VERSION "created by canmatrix"

NS_ :

BS_:

BU_: IPD

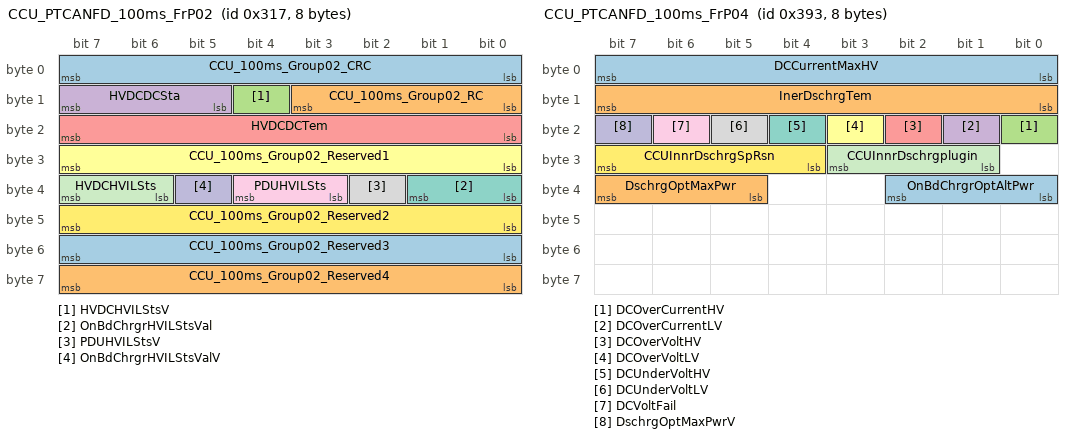
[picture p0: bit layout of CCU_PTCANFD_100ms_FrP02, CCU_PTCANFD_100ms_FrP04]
BO_ 791 CCU_PTCANFD_100ms_FrP02: 8 Vector__XXX
 SG_ CCU_100ms_Group02_CRC : 7|8@0+ (1,0) [0|255] "null" IPD
 SG_ CCU_100ms_Group02_RC : 11|4@0+ (1,0) [0|15] "null" IPD
 SG_ HVDCHVILStsV : 12|1@0+ (1,0) [0|1] "null" IPD
 SG_ HVDCDCSta : 15|3@0+ (1,0) [0|7] "null" IPD
 SG_ HVDCDCTem : 23|8@0+ (1,-40) [-40|215] "" IPD
 SG_ CCU_100ms_Group02_Reserved1 : 31|8@0+ (1,0) [0|255] "null" IPD
 SG_ OnBdChrgrHVILStsVal : 33|2@0+ (1,0) [0|3] "null" IPD
 SG_ PDUHVILStsV : 34|1@0+ (1,0) [0|1] "null" IPD
 SG_ PDUHVILSts : 36|2@0+ (1,0) [0|3] "null" IPD
 SG_ OnBdChrgrHVILStsValV : 37|1@0+ (1,0) [0|1] "null" IPD
 SG_ HVDCHVILSts : 39|2@0+ (1,0) [0|3] "null" IPD
 SG_ CCU_100ms_Group02_Reserved2 : 47|8@0+ (1,0) [0|255] "null" IPD
 SG_ CCU_100ms_Group02_Reserved3 : 55|8@0+ (1,0) [0|255] "null" IPD
 SG_ CCU_100ms_Group02_Reserved4 : 63|8@0+ (1,0) [0|255] "null" IPD

BO_ 915 CCU_PTCANFD_100ms_FrP04: 8 Vector__XXX
 SG_ DCCurrentMaxHV : 7|8@0+ (0.25,0) [0.00|63.75] "A" Vector__XXX
 SG_ InerDschrgTem : 15|8@0+ (1,-40) [-40|215] "DegC" Vector__XXX
 SG_ DCOverCurrentHV : 16|1@0+ (1,0) [0|1] "null" Vector__XXX
 SG_ DCOverCurrentLV : 17|1@0+ (1,0) [0|1] "null" Vector__XXX
 SG_ DCOverVoltHV : 18|1@0+ (1,0) [0|1] "null" Vector__XXX
 SG_ DCOverVoltLV : 19|1@0+ (1,0) [0|1] "null" Vector__XXX
 SG_ DCUnderVoltHV : 20|1@0+ (1,0) [0|1] "null" Vector__XXX
 SG_ DCUnderVoltLV : 21|1@0+ (1,0) [0|1] "null" Vector__XXX
 SG_ DCVoltFail : 22|1@0+ (1,0) [0|1] "null" Vector__XXX
 SG_ DschrgOptMaxPwrV : 23|1@0+ (1,0) [0|1] "null" Vector__XXX
 SG_ CCUInnrDschrgplugin : 27|3@0+ (1,0) [0|7] "null" Vector__XXX
 SG_ CCUInnrDschrgSpRsn : 31|4@0+ (1,0) [0|15] "null" Vector__XXX
 SG_ OnBdChrgrOptAltPwr : 34|3@0+ (0.1,0) [0|0.7] "null" IPD
 SG_ DschrgOptMaxPwr : 39|3@0+ (0.1,0) [0|0.7] "null" IPD

BO_ 992 CCU_PTCANFD_100ms_FrP07: 24 Vector__XXX
 SG_ CCU_100ms_Group07_CRC : 7|8@0+ (1,0) [0|255] "null" IPD
 SG_ CCU_100ms_Group07_RC : 11|4@0+ (1,0) [0|15] "null" IPD
 SG_ CCUOnbdChrgrPlugOnV : 12|1@0+ (1,0) [0|1] "null" IPD
 SG_ CCU_100ms_Group07_Reserved1 : 15|3@0+ (1,0) [0|7] "null" IPD
 SG_ OnBdChrgrCtrlPilotPWMSts : 18|3@0+ (1,0) [0|7] "null" IPD
 SG_ OnBdChrgrWkup : 19|1@0+ (1,0) [0|1] "null" IPD
 SG_ OnBdChrgrSts : 23|4@0+ (1,0) [0|15] "null" IPD
 SG_ OnbdChrgrAltrCrntInptHVCrntLmt : 31|8@0+ (0.5,0) [0|127.5] "A" IPD
 SG_ CCU_100ms_Group07_Reserved3 : 32|1@0+ (1,0) [0|1] "null" IPD
 SG_ OnbdChrgrOtptCrntV : 33|1@0+ (1,0) [0|1] "null" IPD
 SG_ OnbdChrgrOpngMd : 36|3@0+ (1,0) [0|7] "null" IPD
 SG_ CCU_100ms_Group07_Reserved2 : 39|3@0+ (1,0) [0|7] "null" IPD
 SG_ OnBdChrgrAltrCrntInptCrnt : 47|8@0+ (0.2,0) [0|51] "A" IPD
 SG_ OnBdChrgrAltrCrntInptVol : 55|8@0+ (2,0) [0|510] "V" IPD
 SG_ OnbdChrgrOtptCrntVal : 63|12@0+ (0.1,-204.8) [-204.8|204.7] "null" IPD
 SG_ CCU_100ms_Group07_Reserved4 : 66|3@0+ (1,0) [0|7] "null" IPD
 SG_ OnBdChrgrOtptVolV : 67|1@0+ (1,0) [0|1] "null" IPD
 SG_ OnbdChrgrOtptVolVal : 79|16@0+ (0.02,0) [0.00|1310.70] "null" IPD
 SG_ OnBdChrgrL1AltrCrntInptCrnt : 95|8@0+ (0.2,0) [0|51] "A" IPD
 SG_ OnBdChrgrL1AltrCrntInptVol : 103|8@0+ (2,0) [0|510] "V" IPD
 SG_ OnBdChrgrL2AltrCrntInptCrnt : 111|8@0+ (0.2,0) [0|51] "A" IPD
 SG_ OnBdChrgrL2AltrCrntInptVol : 119|8@0+ (2,0) [0|510] "V" IPD
 SG_ OnBdChrgrL3AltrCrntInptCrnt : 127|8@0+ (0.2,0) [0|51] "A" IPD
 SG_ OnBdChrgrL3AltrCrntInptVol : 135|8@0+ (2,0) [0|510] "V" IPD
 SG_ CCUActiveWkup : 136|1@0+ (1,0) [0|1] "null" IPD
 SG_ CCUOnbdChrgrMaxChrgPwr : 143|7@0+ (0.1,0) [0|12.7] "KW" IPD
 SG_ CCU_100ms_Group07_Reserved5 : 147|4@0+ (1,0) [0|15] "null" IPD
 SG_ CCUOnbdChrgrPlugOn : 151|4@0+ (1,0) [0|15] "null" IPD
 SG_ CCU_100ms_Group07_Reserved6 : 155|4@0+ (1,0) [0|15] "null" IPD
 SG_ CCUOnbdChrgrSpRsn : 159|4@0+ (1,0) [0|15] "null" IPD
 SG_ CCU_100ms_Group07_Reserved7 : 167|8@0+ (1,0) [0|255] "null" IPD
 SG_ CCU_100ms_Group07_Reserved9 : 169|2@0+ (1,0) [0|3] "null" IPD
 SG_ OnBdChrgrLastWkup : 170|1@0+ (1,0) [0|1] "null" IPD
 SG_ CCU_100ms_Group07_Reserved8 : 175|5@0+ (1,0) [0|31] "null" IPD
 SG_ CCU_100ms_Group07_Reserved10 : 176|1@0+ (1,0) [0|1] "null" IPD
 SG_ OnBdChrgrCtrlPilotPWMDuty : 183|7@0+ (1,0) [0|127] "null" IPD
 SG_ CCU_100ms_Group07_Reserved11 : 191|8@0+ (1,0) [0|255] "null" IPD

BO_ 966 CCU_PTCANFD_100ms_FrP11: 16 Vector__XXX
 SG_ CCU_100ms_Group11_CRC : 7|8@0+ (1,0) [0|255] "null" IPD
 SG_ CCU_100ms_Group11_RC : 11|4@0+ (1,0) [0|15] "null" IPD
 SG_ CCU_100ms_Group11_Reserved1 : 13|2@0+ (1,0) [0|3] "null" IPD
 SG_ AirCtrlrHVILClsd : 15|2@0+ (1,0) [0|3] "null" IPD
 SG_ CCU_100ms_Group11_Reserved2 : 23|8@0+ (1,0) [0|255] "null" IPD
 SG_ CCUClntFlowReq : 31|8@0+ (0.1,0) [0|25.5] "null" IPD
 SG_ CCU_100ms_Group11_Reserved3 : 39|8@0+ (1,0) [0|255] "null" IPD
 SG_ HVDCDCClntPumpPWMReq : 47|8@0+ (0.4,0) [0|102] "%" IPD
 SG_ AirCtrlrHVILClsdV : 48|1@0+ (1,0) [0|1] "null" IPD
 SG_ ESSPTCHVILSts : 50|2@0+ (1,0) [0|3] "null" IPD
 SG_ CCUOnbdChrgrSktEleccLckEnable : 52|2@0+ (1,0) [0|3] "null" IPD
 SG_ CCU_100ms_Group11_Reserved4 : 55|3@0+ (1,0) [0|7] "null" IPD
 SG_ CCU_100ms_Group11_Reserved6 : 57|2@0+ (1,0) [0|3] "null" IPD
 SG_ HVDCDCIntnlFlr : 58|1@0+ (1,0) [0|1] "null" IPD
 SG_ HVDCDCHdwrFlr : 59|1@0+ (1,0) [0|1] "null" IPD
 SG_ ESSPTCHVILStsV : 60|1@0+ (1,0) [0|1] "null" IPD
 SG_ CCU_100ms_Group11_Reserved5 : 63|3@0+ (1,0) [0|7] "null" IPD
 SG_ CCU_100ms_Group11_Reserved7 : 71|8@0+ (1,0) [0|255] "null" IPD
 SG_ CCU_100ms_Group11_Reserved8 : 79|8@0+ (1,0) [0|255] "null" IPD
 SG_ CCU_100ms_Group11_Reserved9 : 87|8@0+ (1,0) [0|255] "null" IPD
 SG_ CCU_100ms_Group11_Reserved10 : 95|8@0+ (1,0) [0|255] "null" IPD
 SG_ CCU_100ms_Group11_Reserved11 : 103|8@0+ (1,0) [0|255] "null" IPD
 SG_ CCU_100ms_Group11_Reserved12 : 111|8@0+ (1,0) [0|255] "null" IPD
 SG_ CCU_100ms_Group11_Reserved13 : 119|8@0+ (1,0) [0|255] "null" IPD
 SG_ CCU_100ms_Group11_Reserved14 : 127|8@0+ (1,0) [0|255] "null" IPD

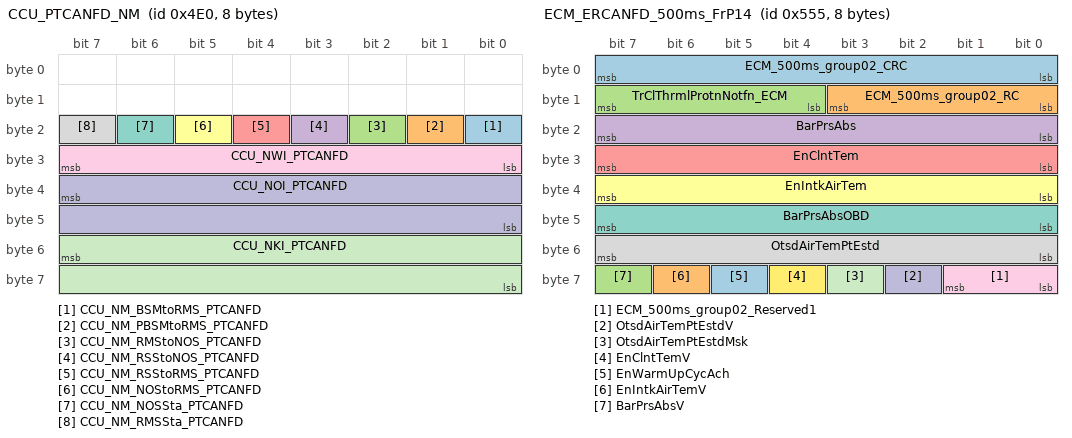
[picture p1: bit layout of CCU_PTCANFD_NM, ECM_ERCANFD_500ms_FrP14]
BO_ 1248 CCU_PTCANFD_NM: 8 Vector__XXX
 SG_ CCU_NM_BSMtoRMS_PTCANFD : 16|1@0+ (1,0) [0|1] "null" Vector__XXX
 SG_ CCU_NM_PBSMtoRMS_PTCANFD : 17|1@0+ (1,0) [0|1] "null" Vector__XXX
 SG_ CCU_NM_RMStoNOS_PTCANFD : 18|1@0+ (1,0) [0|1] "null" Vector__XXX
 SG_ CCU_NM_RSStoNOS_PTCANFD : 19|1@0+ (1,0) [0|1] "null" Vector__XXX
 SG_ CCU_NM_RSStoRMS_PTCANFD : 20|1@0+ (1,0) [0|1] "null" Vector__XXX
 SG_ CCU_NM_NOStoRMS_PTCANFD : 21|1@0+ (1,0) [0|1] "null" Vector__XXX
 SG_ CCU_NM_NOSSta_PTCANFD : 22|1@0+ (1,0) [0|1] "null" Vector__XXX
 SG_ CCU_NM_RMSSta_PTCANFD : 23|1@0+ (1,0) [0|1] "null" Vector__XXX
 SG_ CCU_NWI_PTCANFD : 31|8@0+ (1,0) [0|255] "null" Vector__XXX
 SG_ CCU_NOI_PTCANFD : 39|16@0+ (1,0) [0|65535] "null" Vector__XXX
 SG_ CCU_NKI_PTCANFD : 55|16@0+ (1,0) [0|65535] "null" Vector__XXX

BO_ 132 ECM_ERCANFD_10ms_FrP00: 8 Vector__XXX
 SG_ ECM_010ms_Group00_CRC : 7|8@0+ (1,0) [0|255] "null" IPD
 SG_ ECM_010ms_Group00_RC : 11|4@0+ (1,0) [0|15] "null" IPD
 SG_ EnActuStdyStaToqV : 12|1@0+ (1,0) [0|1] "null" IPD
 SG_ EnRunA : 13|1@0+ (1,0) [0|1] "null" IPD
 SG_ EnSpdSts : 15|2@0+ (1,0) [0|3] "null" IPD
 SG_ EnSpd : 23|16@0+ (0.25,0) [0.00|16383.75] "rpm" IPD
 SG_ ClOpenReqA : 32|1@0+ (1,0) [0|1] "null" IPD
 SG_ EnCtrlrRunCrkTrmlSts : 33|1@0+ (1,0) [0|1] "null" IPD
 SG_ IntlckRelayAuth : 34|1@0+ (1,0) [0|1] "null" IPD
 SG_ RVSPtCrkAbotd : 35|1@0+ (1,0) [0|1] "null" IPD
 SG_ RVSPtRunAbotd : 36|1@0+ (1,0) [0|1] "null" IPD
 SG_ EnTestMdEnbReq : 37|1@0+ (1,0) [0|1] "null" IPD
 SG_ ECM_010ms_Group00_Reserved39 : 39|2@0+ (1,0) [0|3] "null" IPD
 SG_ EnActuStdyStaToq : 47|12@0+ (0.5,-848) [-848|1199.5] "null" IPD
 SG_ EnSpReqToTr : 48|1@0+ (1,0) [0|1] "null" IPD
 SG_ EnCCMd : 51|3@0+ (1,0) [0|7] "null" IPD
 SG_ ECM_010ms_Group00_Reserved63 : 63|8@0+ (1,0) [0|255] "null" IPD

BO_ 1365 ECM_ERCANFD_500ms_FrP14: 8 Vector__XXX
 SG_ ECM_500ms_group02_CRC : 7|8@0+ (1,0) [0|255] "null" IPD
 SG_ ECM_500ms_group02_RC : 11|4@0+ (1,0) [0|15] "null" IPD
 SG_ TrClThrmlProtnNotfn_ECM : 15|4@0+ (1,0) [0|15] "null" IPD
 SG_ BarPrsAbs : 23|8@0+ (0.5,0) [0|127.5] "null" IPD
 SG_ EnClntTem : 31|8@0+ (1,-40) [-40|215] "" IPD
 SG_ EnIntkAirTem : 39|8@0+ (1,-40) [-40|215] "null" IPD
 SG_ BarPrsAbsOBD : 47|8@0+ (1,0) [0|255] "null" IPD
 SG_ OtsdAirTemPtEstd : 55|8@0+ (0.5,-40) [-40|87.5] "null" IPD
 SG_ ECM_500ms_group02_Reserved1 : 57|2@0+ (1,0) [0|3] "null" IPD
 SG_ OtsdAirTemPtEstdV : 58|1@0+ (1,0) [0|1] "null" IPD
 SG_ OtsdAirTemPtEstdMsk : 59|1@0+ (1,0) [0|1] "null" IPD
 SG_ EnClntTemV : 60|1@0+ (1,0) [0|1] "null" IPD
 SG_ EnWarmUpCycAch : 61|1@0+ (1,0) [0|1] "null" IPD
 SG_ EnIntkAirTemV : 62|1@0+ (1,0) [0|1] "null" IPD
 SG_ BarPrsAbsV : 63|1@0+ (1,0) [0|1] "null" IPD

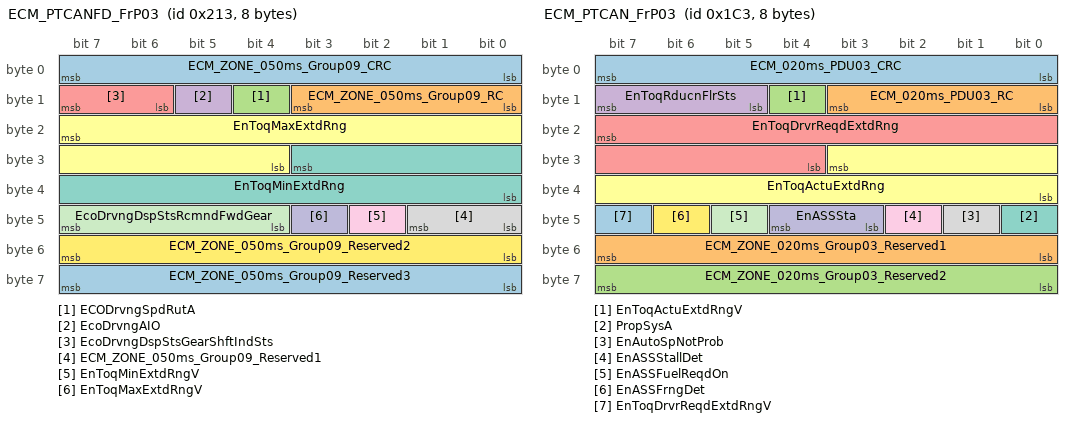
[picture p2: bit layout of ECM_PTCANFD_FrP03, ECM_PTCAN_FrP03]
BO_ 531 ECM_PTCANFD_FrP03: 8 Vector__XXX
 SG_ ECM_ZONE_050ms_Group09_CRC : 7|8@0+ (1,0) [0|255] "null" IPD
 SG_ ECM_ZONE_050ms_Group09_RC : 11|4@0+ (1,0) [0|15] "null" IPD
 SG_ ECODrvngSpdRutA : 12|1@0+ (1,0) [0|1] "null" IPD
 SG_ EcoDrvngAIO : 13|1@0+ (1,0) [0|1] "null" IPD
 SG_ EcoDrvngDspStsGearShftIndSts : 15|2@0+ (1,0) [0|3] "null" IPD
 SG_ EnToqMaxExtdRng : 23|12@0+ (0.5,-848) [-848|1199.5] "Nm" IPD
 SG_ EnToqMinExtdRng : 27|12@0+ (0.5,-848) [-848|1199.5] "Nm" IPD
 SG_ ECM_ZONE_050ms_Group09_Reserved1 : 41|2@0+ (1,0) [0|3] "null" IPD
 SG_ EnToqMinExtdRngV : 42|1@0+ (1,0) [0|1] "null" IPD
 SG_ EnToqMaxExtdRngV : 43|1@0+ (1,0) [0|1] "null" IPD
 SG_ EcoDrvngDspStsRcmndFwdGear : 47|4@0+ (1,0) [0|15] "null" IPD
 SG_ ECM_ZONE_050ms_Group09_Reserved2 : 55|8@0+ (1,0) [0|255] "null" IPD
 SG_ ECM_ZONE_050ms_Group09_Reserved3 : 63|8@0+ (1,0) [0|255] "null" IPD

BO_ 451 ECM_PTCAN_FrP03: 8 Vector__XXX
 SG_ ECM_020ms_PDU03_CRC : 7|8@0+ (1,0) [0|255] "null" IPD
 SG_ ECM_020ms_PDU03_RC : 11|4@0+ (1,0) [0|15] "null" IPD
 SG_ EnToqActuExtdRngV : 12|1@0+ (1,0) [0|1] "null" IPD
 SG_ EnToqRducnFlrSts : 15|3@0+ (1,0) [0|7] "null" IPD
 SG_ EnToqDrvrReqdExtdRng : 23|12@0+ (0.5,-848) [-848|1199.5] "Nm" IPD
 SG_ EnToqActuExtdRng : 27|12@0+ (0.5,-848) [-848|1199.5] "Nm" IPD
 SG_ PropSysA : 40|1@0+ (1,0) [0|1] "null" IPD
 SG_ EnAutoSpNotProb : 41|1@0+ (1,0) [0|1] "null" IPD
 SG_ EnASSStallDet : 42|1@0+ (1,0) [0|1] "null" IPD
 SG_ EnASSSta : 44|2@0+ (1,0) [0|3] "null" IPD
 SG_ EnASSFuelReqdOn : 45|1@0+ (1,0) [0|1] "null" IPD
 SG_ EnASSFrngDet : 46|1@0+ (1,0) [0|1] "null" IPD
 SG_ EnToqDrvrReqdExtdRngV : 47|1@0+ (1,0) [0|1] "null" IPD
 SG_ ECM_ZONE_020ms_Group03_Reserved1 : 55|8@0+ (1,0) [0|255] "null" IPD
 SG_ ECM_ZONE_020ms_Group03_Reserved2 : 63|8@0+ (1,0) [0|255] "null" IPD

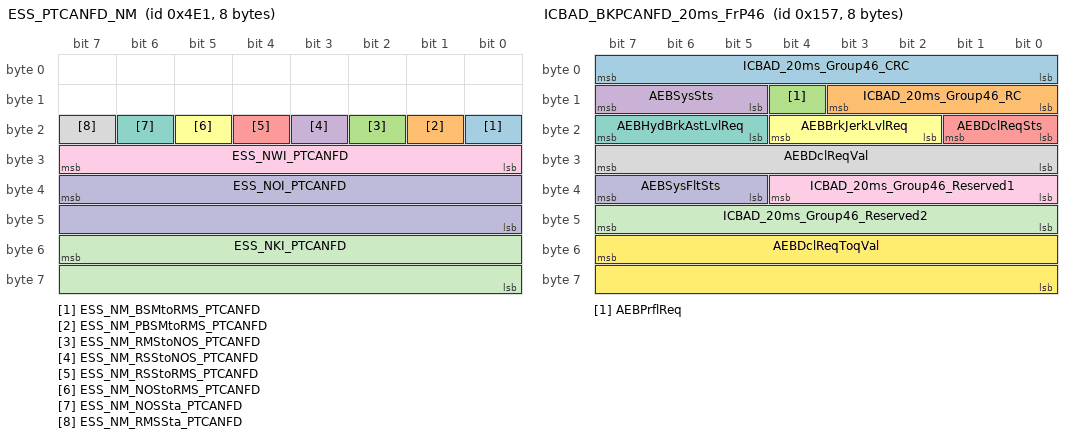
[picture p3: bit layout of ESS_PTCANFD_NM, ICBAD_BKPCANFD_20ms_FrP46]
BO_ 1249 ESS_PTCANFD_NM: 8 Vector__XXX
 SG_ ESS_NM_BSMtoRMS_PTCANFD : 16|1@0+ (1,0) [0|1] "null" Vector__XXX
 SG_ ESS_NM_PBSMtoRMS_PTCANFD : 17|1@0+ (1,0) [0|1] "null" Vector__XXX
 SG_ ESS_NM_RMStoNOS_PTCANFD : 18|1@0+ (1,0) [0|1] "null" Vector__XXX
 SG_ ESS_NM_RSStoNOS_PTCANFD : 19|1@0+ (1,0) [0|1] "null" Vector__XXX
 SG_ ESS_NM_RSStoRMS_PTCANFD : 20|1@0+ (1,0) [0|1] "null" Vector__XXX
 SG_ ESS_NM_NOStoRMS_PTCANFD : 21|1@0+ (1,0) [0|1] "null" Vector__XXX
 SG_ ESS_NM_NOSSta_PTCANFD : 22|1@0+ (1,0) [0|1] "null" Vector__XXX
 SG_ ESS_NM_RMSSta_PTCANFD : 23|1@0+ (1,0) [0|1] "null" Vector__XXX
 SG_ ESS_NWI_PTCANFD : 31|8@0+ (1,0) [0|255] "null" Vector__XXX
 SG_ ESS_NOI_PTCANFD : 39|16@0+ (1,0) [0|65535] "null" Vector__XXX
 SG_ ESS_NKI_PTCANFD : 55|16@0+ (1,0) [0|65535] "null" Vector__XXX

BO_ 307 FVCM_BKPCANFD_20ms_FrP02: 16 IPD
 SG_ FVCM_20ms_Group02_CRC : 7|8@0+ (1,0) [0|255] "null" Vector__XXX
 SG_ FVCM_20ms_Group02_RC : 11|4@0+ (1,0) [0|15] "null" Vector__XXX
 SG_ FVCM_20ms_Group02_Reserved1 : 15|4@0+ (1,0) [0|15] "null" Vector__XXX
 SG_ ACCTotWhlToqReqVal : 23|16@0+ (1,-30000) [-30000|35535] "null" Vector__XXX
 SG_ ACCDrvrSelTrgtSpd : 39|15@0+ (0.015625,0) [0.000000|511.984375] "ms" Vector__XXX
 SG_ ACCGoNotfr : 40|1@0+ (1,0) [0|1] "null" Vector__XXX
 SG_ FVCM_20ms_Group02_Reserved2 : 48|1@0+ (1,0) [0|1] "null" Vector__XXX
 SG_ ACCDetObjDistLvl : 51|3@0+ (1,0) [0|7] "null" Vector__XXX
 SG_ ELKSysSts_IPD : 55|4@0+ (1,0) [0|15] "null" Vector__XXX
 SG_ ACCTotWhlToqReqSts : 57|2@0+ (1,0) [0|3] "null" Vector__XXX
 SG_ ACCTJAMdSwDspCmd : 60|3@0+ (1,0) [0|7] "null" Vector__XXX
 SG_ ACCSeldTrgtDistLvl : 63|3@0+ (1,0) [0|7] "null" Vector__XXX
 SG_ FVCM_20ms_Group02_Reserved3 : 71|8@0+ (1,0) [0|255] "null" Vector__XXX
 SG_ HandOffStrgWhlDetnSta : 73|2@0+ (1,0) [0|3] "null" Vector__XXX
 SG_ ILCActvnDircnDspCmd : 76|3@0+ (1,0) [0|7] "null" Vector__XXX
 SG_ FVCM_20ms_Group02_Reserved4 : 79|3@0+ (1,0) [0|7] "null" Vector__XXX
 SG_ ILCSwDspCmd : 81|2@0+ (1,0) [0|3] "null" Vector__XXX
 SG_ ILCSysSts : 84|3@0+ (1,0) [0|7] "null" Vector__XXX
 SG_ ILCActvnVelDspCmd : 87|3@0+ (1,0) [0|7] "null" Vector__XXX
 SG_ HandOffStrgWhlDetnStaV : 88|1@0+ (1,0) [0|1] "null" Vector__XXX
 SG_ LDWLKAAudReq : 90|2@0+ (1,0) [0|3] "null" Vector__XXX
 SG_ LDWAdoWrnngDspCmd : 92|2@0+ (1,0) [0|3] "null" Vector__XXX
 SG_ LDWLKADspCmd : 95|3@0+ (1,0) [0|7] "null" Vector__XXX
 SG_ FVCM_20ms_Group02_Reserved5 : 98|3@0+ (1,0) [0|7] "null" Vector__XXX
 SG_ LKADrvrTkovReq : 99|1@0+ (1,0) [0|1] "null" Vector__XXX
 SG_ LDWSnstvtLvl : 101|2@0+ (1,0) [0|3] "null" Vector__XXX
 SG_ LDWLKAHptWrnngDspCmd : 103|2@0+ (1,0) [0|3] "null" Vector__XXX
 SG_ EyeOffRoadDetnSta : 105|2@0+ (1,0) [0|3] "null" Vector__XXX
 SG_ FVCM_20ms_Group02_Reserved6 : 111|6@0+ (1,0) [0|63] "null" Vector__XXX
 SG_ FVCM_20ms_Group02_Reserved7 : 113|2@0+ (1,0) [0|3] "null" Vector__XXX
 SG_ EyeOffRoadDetnStaV : 114|1@0+ (1,0) [0|1] "null" Vector__XXX
 SG_ ACCMsgReq : 119|5@0+ (1,0) [0|31] "null" Vector__XXX
 SG_ FVCM_20ms_Group02_Reserved8 : 127|8@0+ (1,0) [0|255] "null" Vector__XXX

BO_ 382 ICBAD_BKPCANFD_20ms_FrP07: 8 IPD
 SG_ ICBAD_20ms_Group07_CRC : 7|8@0+ (1,0) [0|255] "null" Vector__XXX
 SG_ ICBAD_20ms_Group07_RC : 11|4@0+ (1,0) [0|15] "null" Vector__XXX
 SG_ ACCSdslReq : 12|1@0+ (1,0) [0|1] "null" Vector__XXX
 SG_ ACCGoReq : 13|1@0+ (1,0) [0|1] "null" Vector__XXX
 SG_ ACCAccReqSts_CH : 15|2@0+ (1,0) [0|3] "null" Vector__XXX
 SG_ ACCAccReqVal : 18|11@0+ (0.006,-10.278) [-10.278|2.004] "null" Vector__XXX
 SG_ APAEPBOPReq : 20|2@0+ (1,0) [0|3] "null" Vector__XXX
 SG_ ACCSysFltSts : 23|3@0+ (1,0) [0|7] "null" Vector__XXX
 SG_ AIPkgAPASCSAcclReqVal : 34|11@0+ (0.005,-9.22) [-9.220|1.015] "m/s^2" Vector__XXX
 SG_ ACCSysSts : 37|3@0+ (1,0) [0|7] "null" Vector__XXX
 SG_ APASCSAcclReqSts : 38|1@0+ (1,0) [0|1] "null" Vector__XXX
 SG_ APAEPBOPReqV : 39|1@0+ (1,0) [0|1] "null" Vector__XXX
 SG_ AutodDrvngSysSCSSdslReqV : 48|1@0+ (1,0) [0|1] "null" Vector__XXX
 SG_ AutodDrvngSysSCSSdslReq : 49|1@0+ (1,0) [0|1] "null" Vector__XXX
 SG_ AutodDrvngSysEmgcBrkReqV : 50|1@0+ (1,0) [0|1] "null" Vector__XXX
 SG_ AutodDrvngSysEmgcBrkReq : 51|1@0+ (1,0) [0|1] "null" Vector__XXX
 SG_ ICBAD_20ms_Group07_Reserved1 : 55|4@0+ (1,0) [0|15] "null" Vector__XXX
 SG_ AutodDrvngSysSCSDrvOffReqV : 56|1@0+ (1,0) [0|1] "null" Vector__XXX
 SG_ AutodDrvngSysSCSDrvOffReq : 57|1@0+ (1,0) [0|1] "null" Vector__XXX
 SG_ AutodDrvngSysMdReqV : 58|1@0+ (1,0) [0|1] "null" Vector__XXX
 SG_ AutodDrvngSysMdReq : 59|1@0+ (1,0) [0|1] "null" Vector__XXX
 SG_ AutodDrvngSysFlrStsV : 60|1@0+ (1,0) [0|1] "null" Vector__XXX
 SG_ AutodDrvngSysFlrSts : 63|3@0+ (1,0) [0|7] "null" Vector__XXX

BO_ 343 ICBAD_BKPCANFD_20ms_FrP46: 8 IPD
 SG_ ICBAD_20ms_Group46_CRC : 7|8@0+ (1,0) [0|255] "null" Vector__XXX
 SG_ ICBAD_20ms_Group46_RC : 11|4@0+ (1,0) [0|15] "null" Vector__XXX
 SG_ AEBPrflReq : 12|1@0+ (1,0) [0|1] "null" Vector__XXX
 SG_ AEBSysSts : 15|3@0+ (1,0) [0|7] "null" Vector__XXX
 SG_ AEBDclReqSts : 17|2@0+ (1,0) [0|3] "null" Vector__XXX
 SG_ AEBBrkJerkLvlReq : 20|3@0+ (1,0) [0|7] "null" Vector__XXX
 SG_ AEBHydBrkAstLvlReq : 23|3@0+ (1,0) [0|7] "null" Vector__XXX
 SG_ AEBDclReqVal : 31|8@0+ (0.1,-12.7) [-12.7|12.8] "m/s2" Vector__XXX
 SG_ ICBAD_20ms_Group46_Reserved1 : 36|5@0+ (1,0) [0|31] "null" Vector__XXX
 SG_ AEBSysFltSts : 39|3@0+ (1,0) [0|7] "null" Vector__XXX
 SG_ ICBAD_20ms_Group46_Reserved2 : 47|8@0+ (1,0) [0|255] "null" Vector__XXX
 SG_ AEBDclReqToqVal : 55|16@0+ (1,0) [0|65535] "Nm" Vector__XXX

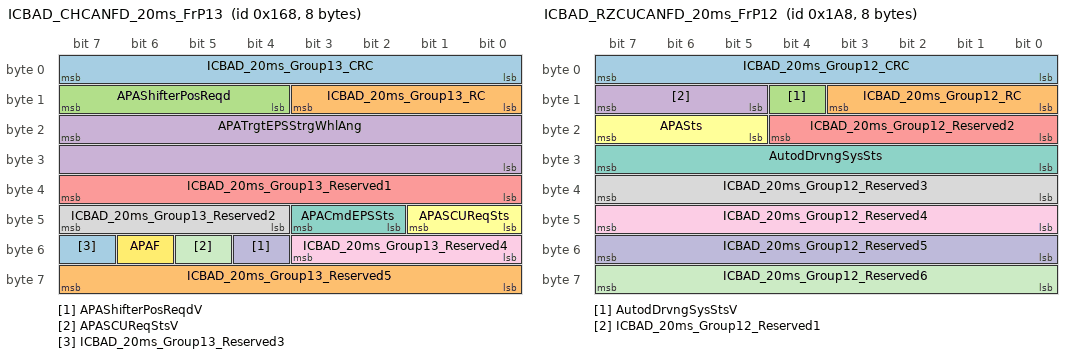
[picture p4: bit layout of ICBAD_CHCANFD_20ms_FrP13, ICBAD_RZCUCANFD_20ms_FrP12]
BO_ 360 ICBAD_CHCANFD_20ms_FrP13: 8 IPD
 SG_ ICBAD_20ms_Group13_CRC : 7|8@0+ (1,0) [0|255] "null" Vector__XXX
 SG_ ICBAD_20ms_Group13_RC : 11|4@0+ (1,0) [0|15] "null" Vector__XXX
 SG_ APAShifterPosReqd : 15|4@0+ (1,0) [0|15] "null" Vector__XXX
 SG_ APATrgtEPSStrgWhlAng : 23|16@0+ (0.0625,-2048) [-2048.0000|2047.9375] "percent" Vector__XXX
 SG_ ICBAD_20ms_Group13_Reserved1 : 39|8@0+ (1,0) [0|255] "null" Vector__XXX
 SG_ APASCUReqSts : 41|2@0+ (1,0) [0|3] "null" Vector__XXX
 SG_ APACmdEPSSts : 43|2@0+ (1,0) [0|3] "null" Vector__XXX
 SG_ ICBAD_20ms_Group13_Reserved2 : 47|4@0+ (1,0) [0|15] "null" Vector__XXX
 SG_ ICBAD_20ms_Group13_Reserved4 : 51|4@0+ (1,0) [0|15] "null" Vector__XXX
 SG_ APAShifterPosReqdV : 52|1@0+ (1,0) [0|1] "null" Vector__XXX
 SG_ APASCUReqStsV : 53|1@0+ (1,0) [0|1] "null" Vector__XXX
 SG_ APAF : 54|1@0+ (1,0) [0|1] "null" Vector__XXX
 SG_ ICBAD_20ms_Group13_Reserved3 : 55|1@0+ (1,0) [0|1] "null" Vector__XXX
 SG_ ICBAD_20ms_Group13_Reserved5 : 63|8@0+ (1,0) [0|255] "null" Vector__XXX

BO_ 351 ICBAD_RZCUCANFD_20ms_FrP05: 20 IPD
 SG_ ICBAD_20ms_Group05_CRC : 7|8@0+ (1,0) [0|255] "null" Vector__XXX
 SG_ ICBAD_20ms_Group05_RC : 11|4@0+ (1,0) [0|15] "null" Vector__XXX
 SG_ ICBAD_20ms_Group05_Reserved1 : 12|1@0+ (1,0) [0|1] "null" Vector__XXX
 SG_ APAVCUReqSts : 15|3@0+ (1,0) [0|7] "null" Vector__XXX
 SG_ ICBAD_20ms_Group05_Reserved2 : 23|8@0+ (1,0) [0|255] "null" Vector__XXX
 SG_ APAToqReqVal : 31|12@0+ (0.5,-848) [-848|1199.5] "Nm" Vector__XXX
 SG_ APACrpSpdReqVal_IPD : 33|10@0+ (0.1,0) [0|102.3] "km/h" Vector__XXX
 SG_ ICBAD_20ms_Group05_Reserved3 : 34|1@0+ (1,0) [0|1] "null" Vector__XXX
 SG_ APARevrDrgReq : 35|1@0+ (1,0) [0|1] "null" Vector__XXX
 SG_ ICBAD_20ms_Group05_Reserved4 : 55|8@0+ (1,0) [0|255] "null" Vector__XXX
 SG_ ICBAD_20ms_Group05_Reserved5 : 63|8@0+ (1,0) [0|255] "null" Vector__XXX
 SG_ APATotWhlToqReqVal : 71|16@0+ (1,-30000) [-30000|35535] "Nm" Vector__XXX
 SG_ ICBAD_20ms_Group05_Reserved6 : 87|8@0+ (1,0) [0|255] "null" Vector__XXX
 SG_ ICBAD_20ms_Group05_Reserved7 : 95|8@0+ (1,0) [0|255] "null" Vector__XXX
 SG_ ICBAD_20ms_Group05_Reserved8 : 103|8@0+ (1,0) [0|255] "null" Vector__XXX
 SG_ ICBAD_20ms_Group05_Reserved9 : 111|8@0+ (1,0) [0|255] "null" Vector__XXX
 SG_ ICBAD_20ms_Group05_Reserved10 : 119|8@0+ (1,0) [0|255] "null" Vector__XXX
 SG_ ICBAD_20ms_Group05_Reserved11 : 127|8@0+ (1,0) [0|255] "null" Vector__XXX
 SG_ ICBAD_20ms_Group05_Reserved12 : 135|8@0+ (1,0) [0|255] "null" Vector__XXX
 SG_ ICBAD_20ms_Group05_Reserved13 : 143|8@0+ (1,0) [0|255] "null" Vector__XXX
 SG_ ICBAD_20ms_Group05_Reserved14 : 151|8@0+ (1,0) [0|255] "null" Vector__XXX
 SG_ ICBAD_20ms_Group05_Reserved15 : 159|8@0+ (1,0) [0|255] "null" Vector__XXX

BO_ 424 ICBAD_RZCUCANFD_20ms_FrP12: 8 IPD
 SG_ ICBAD_20ms_Group12_CRC : 7|8@0+ (1,0) [0|255] "null" Vector__XXX
 SG_ ICBAD_20ms_Group12_RC : 11|4@0+ (1,0) [0|15] "null" Vector__XXX
 SG_ AutodDrvngSysStsV : 12|1@0+ (1,0) [0|1] "null" Vector__XXX
 SG_ ICBAD_20ms_Group12_Reserved1 : 15|3@0+ (1,0) [0|7] "null" Vector__XXX
 SG_ ICBAD_20ms_Group12_Reserved2 : 20|5@0+ (1,0) [0|31] "null" Vector__XXX
 SG_ APASts : 23|3@0+ (1,0) [0|7] "null" Vector__XXX
 SG_ AutodDrvngSysSts : 31|8@0+ (1,0) [0|255] "null" Vector__XXX
 SG_ ICBAD_20ms_Group12_Reserved3 : 39|8@0+ (1,0) [0|255] "null" Vector__XXX
 SG_ ICBAD_20ms_Group12_Reserved4 : 47|8@0+ (1,0) [0|255] "null" Vector__XXX
 SG_ ICBAD_20ms_Group12_Reserved5 : 55|8@0+ (1,0) [0|255] "null" Vector__XXX
 SG_ ICBAD_20ms_Group12_Reserved6 : 63|8@0+ (1,0) [0|255] "null" Vector__XXX

BO_ 431 ICBAD_RZCUCANFD_20ms_FrP15_NoSec: 12 IPD
 SG_ ICBAD_20ms_Group15_CRC : 7|8@0+ (1,0) [0|255] "null" Vector__XXX
 SG_ ICBAD_20ms_Group15_RC : 11|4@0+ (1,0) [0|15] "null" Vector__XXX
 SG_ ACCDclReqSts : 13|2@0+ (1,0) [0|3] "null" Vector__XXX
 SG_ ICBAD_20ms_Group15_Reserved1 : 15|2@0+ (1,0) [0|3] "null" Vector__XXX
 SG_ ICBAD_20ms_Group15_Reserved2 : 23|8@0+ (1,0) [0|255] "null" Vector__XXX
 SG_ ACCOtptShaftTotToqReqVal : 31|12@0+ (2,-3392) [-3392|4798] "Nm" Vector__XXX
 SG_ ICBAD_20ms_Group15_Reserved3 : 33|2@0+ (1,0) [0|3] "null" Vector__XXX
 SG_ ACCOtptShaftTotToqReqSts : 35|2@0+ (1,0) [0|3] "null" Vector__XXX
 SG_ AutodDrvngSysStsPT : 47|8@0+ (1,0) [0|255] "null" Vector__XXX
 SG_ ICBAD_20ms_Group15_Reserved4 : 55|8@0+ (1,0) [0|255] "null" Vector__XXX
 SG_ ICBAD_20ms_Group15_Reserved5 : 63|8@0+ (1,0) [0|255] "null" Vector__XXX
 SG_ ICBAD_20ms_Group15_Reserved6 : 71|8@0+ (1,0) [0|255] "null" Vector__XXX
 SG_ ICBAD_20ms_Group15_Reserved7 : 79|8@0+ (1,0) [0|255] "null" Vector__XXX
 SG_ ICBAD_20ms_Group15_Reserved8 : 87|8@0+ (1,0) [0|255] "null" Vector__XXX
 SG_ ICBAD_20ms_Group15_Reserved9 : 95|8@0+ (1,0) [0|255] "null" Vector__XXX

BA_DEF_ BO_ "FrameTriggeringName" STRING;
BA_DEF_ BO_ "GenMsgCycleTime" INT 0 65535;
BA_DEF_ BO_ "GenMsgSendType" ENUM  "cyclicX","spontanX","cyclicIfActiveX","spontanWithDelay","cyclicAndSpontanX","cyclicAndSpontanWithDelay","spontanWithRepitition","cyclicIfActiveAndSpontanWD","cyclicIfActiveFast","cyclicWithRepeatOnDemand","none";
BA_DEF_ BO_ "GenMsgStartValue" STRING;
BA_DEF_ BO_ "PduName" STRING;
BA_DEF_ BO_ "SystemMessageLongSymbol" STRING;
BA_DEF_ BO_ "VFrameFormat" ENUM  "StandardCAN","ExtendedCAN","reserved","reserved","reserved","reserved","reserved","reserved","reserved","reserved","reserved","reserved","reserved","reserved","StandardCAN_FD","ExtendedCAN_FD";
BA_DEF_ SG_ "CompuMethodName" STRING;
BA_DEF_ SG_ "GenSigStartValue" FLOAT 0 100000000000;
BA_DEF_ SG_ "ISignalName" STRING;
BA_DEF_ SG_ "LongName" STRING;
BA_DEF_ SG_ "SysSignalName" STRING;
BA_DEF_ SG_ "SystemSignalLongSymbol" STRING;
BA_DEF_ BU_ "NWM-Knoten" ENUM  "nein","ja";
BA_DEF_ BU_ "NWM-Stationsadresse" HEX 0 63;
BA_DEF_  "BusType" STRING;
BA_ "NWM-Knoten" BU_ IPD 0;
BA_ "NWM-Stationsadresse" BU_ IPD 0;

BA_ "BusType"   "CAN FD";

BA_ "FrameTriggeringName" BO_ 791 "CCU_PTCANFD_100ms_FrP02";
BA_ "GenMsgCycleTime" BO_ 791 100;
BA_ "GenMsgSendType" BO_ 791 0;
BA_ "GenMsgStartValue" BO_ 791 "0010feff24ffffff";
BA_ "PduName" BO_ 791 "CCU_100ms_PDU02";
BA_ "VFrameFormat" BO_ 791 14;
BA_ "FrameTriggeringName" BO_ 915 "CCU_PTCANFD_100ms_FrP04";
BA_ "GenMsgCycleTime" BO_ 915 100;
BA_ "GenMsgSendType" BO_ 915 0;
BA_ "GenMsgStartValue" BO_ 915 "00fe000000000000";
BA_ "PduName" BO_ 915 "CCU_100ms_PDU04";
BA_ "VFrameFormat" BO_ 915 14;
BA_ "FrameTriggeringName" BO_ 992 "CCU_PTCANFD_100ms_FrP07";
BA_ "GenMsgCycleTime" BO_ 992 100;
BA_ "GenMsgSendType" BO_ 992 0;
BA_ "GenMsgStartValue" BO_ 992 "00e00000e30000000f0000000000000000000f0ffffb01ff";
BA_ "PduName" BO_ 992 "CCU_100ms_PDU07";
BA_ "VFrameFormat" BO_ 992 14;
BA_ "FrameTriggeringName" BO_ 966 "CCU_PTCANFD_100ms_FrP11";
BA_ "GenMsgCycleTime" BO_ 966 100;
BA_ "GenMsgSendType" BO_ 966 0;
BA_ "GenMsgStartValue" BO_ 966 "0030ff00ff00e1f3ffffffffffffffff";
BA_ "PduName" BO_ 966 "CCU_100ms_PDU11";
BA_ "VFrameFormat" BO_ 966 14;
BA_ "FrameTriggeringName" BO_ 1248 "CCU_PTCANFD_NM";
BA_ "GenMsgSendType" BO_ 1248 1;
BA_ "GenMsgStartValue" BO_ 1248 "0000000000000000";
BA_ "PduName" BO_ 1248 "NmPDU_PTCANFD_CCU";
BA_ "VFrameFormat" BO_ 1248 14;
BA_ "FrameTriggeringName" BO_ 132 "ECM_ERCANFD_10ms_FrP00";
BA_ "GenMsgCycleTime" BO_ 132 10;
BA_ "GenMsgSendType" BO_ 132 0;
BA_ "GenMsgStartValue" BO_ 132 "00000000c00000ff";
BA_ "PduName" BO_ 132 "ECM_010ms_PDU00";
BA_ "VFrameFormat" BO_ 132 14;
BA_ "FrameTriggeringName" BO_ 1365 "ECM_ERCANFD_500ms_FrP14";
BA_ "GenMsgCycleTime" BO_ 1365 500;
BA_ "GenMsgSendType" BO_ 1365 0;
BA_ "GenMsgStartValue" BO_ 1365 "0000c80000000093";
BA_ "PduName" BO_ 1365 "ECM_500ms_PDU14";
BA_ "VFrameFormat" BO_ 1365 14;
BA_ "FrameTriggeringName" BO_ 531 "ECM_PTCANFD_FrP03";
BA_ "GenMsgCycleTime" BO_ 531 50;
BA_ "GenMsgSendType" BO_ 531 0;
BA_ "GenMsgStartValue" BO_ 531 "000000000003ffff";
BA_ "PduName" BO_ 531 "ECM_ZONE_050ms_PDU09";
BA_ "VFrameFormat" BO_ 531 14;
BA_ "FrameTriggeringName" BO_ 451 "ECM_PTCAN_FrP03";
BA_ "GenMsgCycleTime" BO_ 451 20;
BA_ "GenMsgSendType" BO_ 451 0;
BA_ "GenMsgStartValue" BO_ 451 "000000000008ffff";
BA_ "PduName" BO_ 451 "ECM_ZONE_020ms_PDU03";
BA_ "VFrameFormat" BO_ 451 14;
BA_ "FrameTriggeringName" BO_ 1249 "ESS_PTCANFD_NM";
BA_ "GenMsgSendType" BO_ 1249 1;
BA_ "GenMsgStartValue" BO_ 1249 "0000000000000000";
BA_ "PduName" BO_ 1249 "NmPDU_PTCANFD_ESS";
BA_ "VFrameFormat" BO_ 1249 14;
BA_ "FrameTriggeringName" BO_ 307 "FVCM_BKPCANFD_20ms_FrP02";
BA_ "GenMsgCycleTime" BO_ 307 20;
BA_ "GenMsgSendType" BO_ 307 0;
BA_ "GenMsgStartValue" BO_ 307 "00f0753000000160ffe0000007fc03ff";
BA_ "PduName" BO_ 307 "FVCM_20ms_PDU02";
BA_ "VFrameFormat" BO_ 307 14;
BA_ "FrameTriggeringName" BO_ 382 "ICBAD_BKPCANFD_20ms_FrP07";
BA_ "GenMsgCycleTime" BO_ 382 20;
BA_ "GenMsgSendType" BO_ 382 0;
BA_ "GenMsgStartValue" BO_ 382 "000005a40000f000";
BA_ "PduName" BO_ 382 "ICBAD_20ms_PDU07";
BA_ "VFrameFormat" BO_ 382 14;
BA_ "FrameTriggeringName" BO_ 343 "ICBAD_BKPCANFD_20ms_FrP46";
BA_ "GenMsgCycleTime" BO_ 343 20;
BA_ "GenMsgSendType" BO_ 343 0;
BA_ "GenMsgStartValue" BO_ 343 "0020007f1fff0000";
BA_ "PduName" BO_ 343 "ICBAD_20ms_PDU46";
BA_ "VFrameFormat" BO_ 343 14;
BA_ "FrameTriggeringName" BO_ 360 "ICBAD_CHCANFD_20ms_FrP13";
BA_ "GenMsgCycleTime" BO_ 360 20;
BA_ "GenMsgSendType" BO_ 360 0;
BA_ "GenMsgStartValue" BO_ 360 "00008000fff08fff";
BA_ "PduName" BO_ 360 "ICBAD_20ms_PDU13";
BA_ "VFrameFormat" BO_ 360 14;
BA_ "FrameTriggeringName" BO_ 351 "ICBAD_RZCUCANFD_20ms_FrP05";
BA_ "GenMsgCycleTime" BO_ 351 20;
BA_ "GenMsgSendType" BO_ 351 0;
BA_ "GenMsgStartValue" BO_ 351 "0010ff000400ffff0000ffffffffffffffffffff";
BA_ "PduName" BO_ 351 "ICBAD_20ms_PDU05";
BA_ "VFrameFormat" BO_ 351 14;
BA_ "FrameTriggeringName" BO_ 424 "ICBAD_RZCUCANFD_20ms_FrP12";
BA_ "GenMsgCycleTime" BO_ 424 20;
BA_ "GenMsgSendType" BO_ 424 0;
BA_ "GenMsgStartValue" BO_ 424 "00e01f00ffffffff";
BA_ "PduName" BO_ 424 "ICBAD_20ms_PDU12";
BA_ "VFrameFormat" BO_ 424 14;
BA_ "FrameTriggeringName" BO_ 431 "ICBAD_RZCUCANFD_20ms_FrP15_NoSecOC";
BA_ "GenMsgCycleTime" BO_ 431 20;
BA_ "GenMsgSendType" BO_ 431 0;
BA_ "GenMsgStartValue" BO_ 431 "00c0ff6a0300ffffffffffff";
BA_ "PduName" BO_ 431 "ICBAD_20ms_PDU15";
BA_ "SystemMessageLongSymbol" BO_ 431 "ICBAD_RZCUCANFD_20ms_FrP15_NoSecOC";
BA_ "VFrameFormat" BO_ 431 14;

BA_ "CompuMethodName" SG_ 791 CCU_100ms_Group02_CRC "CCU_100ms_Group02_CRC";
BA_ "ISignalName" SG_ 791 CCU_100ms_Group02_CRC "ICCU_100ms_Group02_CRC";
BA_ "LongName" SG_ 791 CCU_100ms_Group02_CRC "CCU_100ms_Group02_CRC";
BA_ "SysSignalName" SG_ 791 CCU_100ms_Group02_CRC "CCU_100ms_Group02_CRC";
BA_ "CompuMethodName" SG_ 791 CCU_100ms_Group02_RC "CCU_100ms_Group02_RC";
BA_ "ISignalName" SG_ 791 CCU_100ms_Group02_RC "ICCU_100ms_Group02_RC";
BA_ "LongName" SG_ 791 CCU_100ms_Group02_RC "CCU_100ms_Group02_RC";
BA_ "SysSignalName" SG_ 791 CCU_100ms_Group02_RC "CCU_100ms_Group02_RC";
BA_ "CompuMethodName" SG_ 791 HVDCHVILStsV "HVDCHVILStsV";
BA_ "GenSigStartValue" SG_ 791 HVDCHVILStsV 1;
BA_ "ISignalName" SG_ 791 HVDCHVILStsV "IHVDCHVILStsV";
BA_ "LongName" SG_ 791 HVDCHVILStsV "High Voltage Direct Current High Voltage Interlock Loop Status Validity";
BA_ "SysSignalName" SG_ 791 HVDCHVILStsV "HVDCHVILStsV";
BA_ "CompuMethodName" SG_ 791 HVDCDCSta "HVDCDCSta";
BA_ "ISignalName" SG_ 791 HVDCDCSta "IHVDCDCSta";
BA_ "LongName" SG_ 791 HVDCDCSta "High_Voltage_Direct_Current_Direct_Current_State";
BA_ "SysSignalName" SG_ 791 HVDCDCSta "HVDCDCSta";
BA_ "CompuMethodName" SG_ 791 HVDCDCTem "HVDCDCTem";
BA_ "GenSigStartValue" SG_ 791 HVDCDCTem 254;
BA_ "ISignalName" SG_ 791 HVDCDCTem "IHVDCDCTem";
BA_ "LongName" SG_ 791 HVDCDCTem "High Voltage Direct Current Direct Current Temperature";
BA_ "SysSignalName" SG_ 791 HVDCDCTem "HVDCDCTem";
BA_ "CompuMethodName" SG_ 791 CCU_100ms_Group02_Reserved1 "CCU_100ms_Group02_Reserved1";
BA_ "GenSigStartValue" SG_ 791 CCU_100ms_Group02_Reserved1 255;
BA_ "ISignalName" SG_ 791 CCU_100ms_Group02_Reserved1 "ICCU_100ms_Group02_Reserved1";
BA_ "SysSignalName" SG_ 791 CCU_100ms_Group02_Reserved1 "CCU_100ms_Group02_Reserved1";
BA_ "CompuMethodName" SG_ 791 OnBdChrgrHVILStsVal "OnBdChrgrHVILStsVal";
BA_ "ISignalName" SG_ 791 OnBdChrgrHVILStsVal "IOnBdChrgrHVILStsVal";
BA_ "LongName" SG_ 791 OnBdChrgrHVILStsVal "On Board Charger High Voltage Interlock Loop Status Value";
BA_ "SysSignalName" SG_ 791 OnBdChrgrHVILStsVal "OnBdChrgrHVILStsVal";
BA_ "CompuMethodName" SG_ 791 PDUHVILStsV "PDUHVILStsV";
BA_ "GenSigStartValue" SG_ 791 PDUHVILStsV 1;
BA_ "ISignalName" SG_ 791 PDUHVILStsV "IPDUHVILStsV";
BA_ "LongName" SG_ 791 PDUHVILStsV "Power Distribution Unit High Voltage Interlock Loop Status Validity";
BA_ "SysSignalName" SG_ 791 PDUHVILStsV "PDUHVILStsV";
BA_ "CompuMethodName" SG_ 791 PDUHVILSts "PDUHVILSts";
BA_ "ISignalName" SG_ 791 PDUHVILSts "IPDUHVILSts";
BA_ "LongName" SG_ 791 PDUHVILSts "Power Distribution Unit High Voltage Interlock Loop Status";
BA_ "SysSignalName" SG_ 791 PDUHVILSts "PDUHVILSts";
BA_ "CompuMethodName" SG_ 791 OnBdChrgrHVILStsValV "OnBdChrgrHVILStsValV";
BA_ "GenSigStartValue" SG_ 791 OnBdChrgrHVILStsValV 1;
BA_ "ISignalName" SG_ 791 OnBdChrgrHVILStsValV "IOnBdChrgrHVILStsValV";
BA_ "LongName" SG_ 791 OnBdChrgrHVILStsValV "On Board Charger High Voltage Interlock Loop Status Value Validity";
BA_ "SysSignalName" SG_ 791 OnBdChrgrHVILStsValV "OnBdChrgrHVILStsValV";
BA_ "CompuMethodName" SG_ 791 HVDCHVILSts "HVDCHVILSts";
BA_ "ISignalName" SG_ 791 HVDCHVILSts "IHVDCHVILSts";
BA_ "LongName" SG_ 791 HVDCHVILSts "High Voltage Direct Current High Voltage Interlock Loop Status";
BA_ "SysSignalName" SG_ 791 HVDCHVILSts "HVDCHVILSts";
BA_ "CompuMethodName" SG_ 791 CCU_100ms_Group02_Reserved2 "CCU_100ms_Group02_Reserved2";
BA_ "GenSigStartValue" SG_ 791 CCU_100ms_Group02_Reserved2 255;
BA_ "ISignalName" SG_ 791 CCU_100ms_Group02_Reserved2 "ICCU_100ms_Group02_Reserved2";
BA_ "SysSignalName" SG_ 791 CCU_100ms_Group02_Reserved2 "CCU_100ms_Group02_Reserved2";
BA_ "CompuMethodName" SG_ 791 CCU_100ms_Group02_Reserved3 "CCU_100ms_Group02_Reserved3";
BA_ "GenSigStartValue" SG_ 791 CCU_100ms_Group02_Reserved3 255;
BA_ "ISignalName" SG_ 791 CCU_100ms_Group02_Reserved3 "ICCU_100ms_Group02_Reserved3";
BA_ "SysSignalName" SG_ 791 CCU_100ms_Group02_Reserved3 "CCU_100ms_Group02_Reserved3";
BA_ "CompuMethodName" SG_ 791 CCU_100ms_Group02_Reserved4 "CCU_100ms_Group02_Reserved4";
BA_ "GenSigStartValue" SG_ 791 CCU_100ms_Group02_Reserved4 255;
BA_ "ISignalName" SG_ 791 CCU_100ms_Group02_Reserved4 "ICCU_100ms_Group02_Reserved4";
BA_ "SysSignalName" SG_ 791 CCU_100ms_Group02_Reserved4 "CCU_100ms_Group02_Reserved4";
BA_ "CompuMethodName" SG_ 915 DCCurrentMaxHV "DCCurrentMaxHV";
BA_ "ISignalName" SG_ 915 DCCurrentMaxHV "IDCCurrentMaxHV";
BA_ "LongName" SG_ 915 DCCurrentMaxHV "Direct Current Max Current At Hv Side";
BA_ "SysSignalName" SG_ 915 DCCurrentMaxHV "DCCurrentMaxHV";
BA_ "CompuMethodName" SG_ 915 InerDschrgTem "InerDschrgTem";
BA_ "GenSigStartValue" SG_ 915 InerDschrgTem 254;
BA_ "ISignalName" SG_ 915 InerDschrgTem "IInerDschrgTem";
BA_ "LongName" SG_ 915 InerDschrgTem "Inner Discharger Socket Temperature";
BA_ "SysSignalName" SG_ 915 InerDschrgTem "InerDschrgTem";
BA_ "CompuMethodName" SG_ 915 DCOverCurrentHV "DCOverCurrentHV";
BA_ "ISignalName" SG_ 915 DCOverCurrentHV "IDCOverCurrentHV";
BA_ "LongName" SG_ 915 DCOverCurrentHV "Direct Current Over Current At Hv Side";
BA_ "SysSignalName" SG_ 915 DCOverCurrentHV "DCOverCurrentHV";
BA_ "CompuMethodName" SG_ 915 DCOverCurrentLV "DCOverCurrentLV";
BA_ "ISignalName" SG_ 915 DCOverCurrentLV "IDCOverCurrentLV";
BA_ "LongName" SG_ 915 DCOverCurrentLV "Direct Current Over Current At Lv Side";
BA_ "SysSignalName" SG_ 915 DCOverCurrentLV "DCOverCurrentLV";
BA_ "CompuMethodName" SG_ 915 DCOverVoltHV "DCOverVoltHV";
BA_ "ISignalName" SG_ 915 DCOverVoltHV "IDCOverVoltHV";
BA_ "LongName" SG_ 915 DCOverVoltHV "Direct Current Over Volt High Voltage";
BA_ "SysSignalName" SG_ 915 DCOverVoltHV "DCOverVoltHV";
BA_ "CompuMethodName" SG_ 915 DCOverVoltLV "DCOverVoltLV";
BA_ "ISignalName" SG_ 915 DCOverVoltLV "IDCOverVoltLV";
BA_ "LongName" SG_ 915 DCOverVoltLV "Direct Current Over Volt Low Voltage";
BA_ "SysSignalName" SG_ 915 DCOverVoltLV "DCOverVoltLV";
BA_ "CompuMethodName" SG_ 915 DCUnderVoltHV "DCUnderVoltHV";
BA_ "ISignalName" SG_ 915 DCUnderVoltHV "IDCUnderVoltHV";
BA_ "LongName" SG_ 915 DCUnderVoltHV "Direct Current Under Volt High Voltage";
BA_ "SysSignalName" SG_ 915 DCUnderVoltHV "DCUnderVoltHV";
BA_ "CompuMethodName" SG_ 915 DCUnderVoltLV "DCUnderVoltLV";
BA_ "ISignalName" SG_ 915 DCUnderVoltLV "IDCUnderVoltLV";
BA_ "LongName" SG_ 915 DCUnderVoltLV "Direct Current Under Volt Low Voltage";
BA_ "SysSignalName" SG_ 915 DCUnderVoltLV "DCUnderVoltLV";
BA_ "CompuMethodName" SG_ 915 DCVoltFail "DCVoltFail";
BA_ "ISignalName" SG_ 915 DCVoltFail "IDCVoltFail";
BA_ "LongName" SG_ 915 DCVoltFail "Direct Current Voltage Failure";
BA_ "SysSignalName" SG_ 915 DCVoltFail "DCVoltFail";
BA_ "CompuMethodName" SG_ 915 DschrgOptMaxPwrV "DschrgOptMaxPwrV";
BA_ "ISignalName" SG_ 915 DschrgOptMaxPwrV "IDschrgOptMaxPwrV";
BA_ "LongName" SG_ 915 DschrgOptMaxPwrV "Discharge  Output Max Power Valid";
BA_ "SysSignalName" SG_ 915 DschrgOptMaxPwrV "DschrgOptMaxPwrV";
BA_ "CompuMethodName" SG_ 915 CCUInnrDschrgplugin "CCUInnrDschrgplugin";
BA_ "ISignalName" SG_ 915 CCUInnrDschrgplugin "ICCUInnrDschrgplugin";
BA_ "LongName" SG_ 915 CCUInnrDschrgplugin "CCU inner Discharger plug in";
BA_ "SysSignalName" SG_ 915 CCUInnrDschrgplugin "CCUInnrDschrgplugin";
BA_ "CompuMethodName" SG_ 915 CCUInnrDschrgSpRsn "CCUInnrDschrgSpRsn";
BA_ "ISignalName" SG_ 915 CCUInnrDschrgSpRsn "ICCUInnrDschrgSpRsn";
BA_ "LongName" SG_ 915 CCUInnrDschrgSpRsn "CCU Inner Dischargering Stop Reason";
BA_ "SysSignalName" SG_ 915 CCUInnrDschrgSpRsn "CCUInnrDschrgSpRsn";
BA_ "CompuMethodName" SG_ 915 OnBdChrgrOptAltPwr "OnBdChrgrOptAltPwr";
BA_ "ISignalName" SG_ 915 OnBdChrgrOptAltPwr "IOnBdChrgrOptAltPwr";
BA_ "LongName" SG_ 915 OnBdChrgrOptAltPwr "On Board Charger Output Alternating Power";
BA_ "SysSignalName" SG_ 915 OnBdChrgrOptAltPwr "OnBdChrgrOptAltPwr";
BA_ "CompuMethodName" SG_ 915 DschrgOptMaxPwr "DschrgOptMaxPwr";
BA_ "ISignalName" SG_ 915 DschrgOptMaxPwr "IDschrgOptMaxPwr";
BA_ "LongName" SG_ 915 DschrgOptMaxPwr "Discharge  Output Max Power";
BA_ "SysSignalName" SG_ 915 DschrgOptMaxPwr "DschrgOptMaxPwr";
BA_ "CompuMethodName" SG_ 992 CCU_100ms_Group07_CRC "CCU_100ms_Group07_CRC";
BA_ "ISignalName" SG_ 992 CCU_100ms_Group07_CRC "ICCU_100ms_Group07_CRC";
BA_ "LongName" SG_ 992 CCU_100ms_Group07_CRC "CCU_100ms_Group07_CRC";
BA_ "SysSignalName" SG_ 992 CCU_100ms_Group07_CRC "CCU_100ms_Group07_CRC";
BA_ "CompuMethodName" SG_ 992 CCU_100ms_Group07_RC "CCU_100ms_Group07_RC";
BA_ "ISignalName" SG_ 992 CCU_100ms_Group07_RC "ICCU_100ms_Group07_RC";
BA_ "LongName" SG_ 992 CCU_100ms_Group07_RC "CCU_100ms_Group07_RC";
BA_ "SysSignalName" SG_ 992 CCU_100ms_Group07_RC "CCU_100ms_Group07_RC";
BA_ "CompuMethodName" SG_ 992 CCUOnbdChrgrPlugOnV "CCUOnbdChrgrPlugOnV";
BA_ "ISignalName" SG_ 992 CCUOnbdChrgrPlugOnV "ICCUOnbdChrgrPlugOnV";
BA_ "LongName" SG_ 992 CCUOnbdChrgrPlugOnV "Combined Charging Unit Onboard Charger Plug On Validity";
BA_ "SysSignalName" SG_ 992 CCUOnbdChrgrPlugOnV "CCUOnbdChrgrPlugOnV";
BA_ "CompuMethodName" SG_ 992 CCU_100ms_Group07_Reserved1 "CCU_100ms_Group07_Reserved1";
BA_ "GenSigStartValue" SG_ 992 CCU_100ms_Group07_Reserved1 7;
BA_ "ISignalName" SG_ 992 CCU_100ms_Group07_Reserved1 "ICCU_100ms_Group07_Reserved1";
BA_ "SysSignalName" SG_ 992 CCU_100ms_Group07_Reserved1 "CCU_100ms_Group07_Reserved1";
BA_ "CompuMethodName" SG_ 992 OnBdChrgrCtrlPilotPWMSts "OnBdChrgrCtrlPilotPWMSts";
BA_ "ISignalName" SG_ 992 OnBdChrgrCtrlPilotPWMSts "IOnBdChrgrCtrlPilotPWMSts";
BA_ "LongName" SG_ 992 OnBdChrgrCtrlPilotPWMSts "On Board Charger Control Pilot Pulse Width Modulation Status";
BA_ "SysSignalName" SG_ 992 OnBdChrgrCtrlPilotPWMSts "OnBdChrgrCtrlPilotPWMSts";
BA_ "CompuMethodName" SG_ 992 OnBdChrgrWkup "OnBdChrgrWkup";
BA_ "ISignalName" SG_ 992 OnBdChrgrWkup "IOnBdChrgrWkup";
BA_ "LongName" SG_ 992 OnBdChrgrWkup "On Board Charger Wakeup";
BA_ "SysSignalName" SG_ 992 OnBdChrgrWkup "OnBdChrgrWkup";
BA_ "CompuMethodName" SG_ 992 OnBdChrgrSts "OnBdChrgrSts";
BA_ "ISignalName" SG_ 992 OnBdChrgrSts "IOnBdChrgrSts";
BA_ "LongName" SG_ 992 OnBdChrgrSts "On Board Charger Status";
BA_ "SysSignalName" SG_ 992 OnBdChrgrSts "OnBdChrgrSts";
BA_ "CompuMethodName" SG_ 992 OnbdChrgrAltrCrntInptHVCrntLmt "OnbdChrgrAltrCrntInptHVCrntLmt";
BA_ "ISignalName" SG_ 992 OnbdChrgrAltrCrntInptHVCrntLmt "IOnbdChrgrAltrCrntInptHVCrntLmt";
BA_ "LongName" SG_ 992 OnbdChrgrAltrCrntInptHVCrntLmt "Onboard Charger Alternator Current Input High Voltage Current Limit";
BA_ "SysSignalName" SG_ 992 OnbdChrgrAltrCrntInptHVCrntLmt "OnbdChrgrAltrCrntInptHVCrntLmt";
BA_ "CompuMethodName" SG_ 992 CCU_100ms_Group07_Reserved3 "CCU_100ms_Group07_Reserved3";
BA_ "GenSigStartValue" SG_ 992 CCU_100ms_Group07_Reserved3 1;
BA_ "ISignalName" SG_ 992 CCU_100ms_Group07_Reserved3 "ICCU_100ms_Group07_Reserved3";
BA_ "SysSignalName" SG_ 992 CCU_100ms_Group07_Reserved3 "CCU_100ms_Group07_Reserved3";
BA_ "CompuMethodName" SG_ 992 OnbdChrgrOtptCrntV "OnbdChrgrOtptCrntV";
BA_ "GenSigStartValue" SG_ 992 OnbdChrgrOtptCrntV 1;
BA_ "ISignalName" SG_ 992 OnbdChrgrOtptCrntV "IOnbdChrgrOtptCrntV";
BA_ "LongName" SG_ 992 OnbdChrgrOtptCrntV "On Board Charger Output Current Validity";
BA_ "SysSignalName" SG_ 992 OnbdChrgrOtptCrntV "OnbdChrgrOtptCrntV";
BA_ "CompuMethodName" SG_ 992 OnbdChrgrOpngMd "OnbdChrgrOpngMd";
BA_ "ISignalName" SG_ 992 OnbdChrgrOpngMd "IOnbdChrgrOpngMd";
BA_ "LongName" SG_ 992 OnbdChrgrOpngMd "On Board Charger Operating Mode";
BA_ "SysSignalName" SG_ 992 OnbdChrgrOpngMd "OnbdChrgrOpngMd";
BA_ "CompuMethodName" SG_ 992 CCU_100ms_Group07_Reserved2 "CCU_100ms_Group07_Reserved2";
BA_ "GenSigStartValue" SG_ 992 CCU_100ms_Group07_Reserved2 7;
BA_ "ISignalName" SG_ 992 CCU_100ms_Group07_Reserved2 "ICCU_100ms_Group07_Reserved2";
BA_ "SysSignalName" SG_ 992 CCU_100ms_Group07_Reserved2 "CCU_100ms_Group07_Reserved2";
BA_ "CompuMethodName" SG_ 992 OnBdChrgrAltrCrntInptCrnt "OnBdChrgrAltrCrntInptCrnt";
BA_ "ISignalName" SG_ 992 OnBdChrgrAltrCrntInptCrnt "IOnBdChrgrAltrCrntInptCrnt";
BA_ "LongName" SG_ 992 OnBdChrgrAltrCrntInptCrnt "On Board Charger Alternator Current Input Current";
BA_ "SysSignalName" SG_ 992 OnBdChrgrAltrCrntInptCrnt "OnBdChrgrAltrCrntInptCrnt";
BA_ "CompuMethodName" SG_ 992 OnBdChrgrAltrCrntInptVol "OnBdChrgrAltrCrntInptVol";
BA_ "ISignalName" SG_ 992 OnBdChrgrAltrCrntInptVol "IOnBdChrgrAltrCrntInptVol";
BA_ "LongName" SG_ 992 OnBdChrgrAltrCrntInptVol "On Board Charger Alternator Current Input Voltage";
BA_ "SysSignalName" SG_ 992 OnBdChrgrAltrCrntInptVol "OnBdChrgrAltrCrntInptVol";
BA_ "CompuMethodName" SG_ 992 OnbdChrgrOtptCrntVal "OnbdChrgrOtptCrntVal";
BA_ "ISignalName" SG_ 992 OnbdChrgrOtptCrntVal "IOnbdChrgrOtptCrntVal";
BA_ "LongName" SG_ 992 OnbdChrgrOtptCrntVal "On Board Charger Output Current Value";
BA_ "SysSignalName" SG_ 992 OnbdChrgrOtptCrntVal "OnbdChrgrOtptCrntVal";
BA_ "CompuMethodName" SG_ 992 CCU_100ms_Group07_Reserved4 "CCU_100ms_Group07_Reserved4";
BA_ "GenSigStartValue" SG_ 992 CCU_100ms_Group07_Reserved4 7;
BA_ "ISignalName" SG_ 992 CCU_100ms_Group07_Reserved4 "ICCU_100ms_Group07_Reserved4";
BA_ "SysSignalName" SG_ 992 CCU_100ms_Group07_Reserved4 "CCU_100ms_Group07_Reserved4";
BA_ "CompuMethodName" SG_ 992 OnBdChrgrOtptVolV "OnBdChrgrOtptVolV";
BA_ "GenSigStartValue" SG_ 992 OnBdChrgrOtptVolV 1;
BA_ "ISignalName" SG_ 992 OnBdChrgrOtptVolV "IOnBdChrgrOtptVolV";
BA_ "LongName" SG_ 992 OnBdChrgrOtptVolV "On Board Charger Output Voltage Validity";
BA_ "SysSignalName" SG_ 992 OnBdChrgrOtptVolV "OnBdChrgrOtptVolV";
BA_ "CompuMethodName" SG_ 992 OnbdChrgrOtptVolVal "OnbdChrgrOtptVolVal";
BA_ "ISignalName" SG_ 992 OnbdChrgrOtptVolVal "IOnbdChrgrOtptVolVal";
BA_ "LongName" SG_ 992 OnbdChrgrOtptVolVal "On Board Charger Output Voltage Value";
BA_ "SysSignalName" SG_ 992 OnbdChrgrOtptVolVal "OnbdChrgrOtptVolVal";
BA_ "CompuMethodName" SG_ 992 OnBdChrgrL1AltrCrntInptCrnt "OnBdChrgrL1AltrCrntInptCrnt";
BA_ "ISignalName" SG_ 992 OnBdChrgrL1AltrCrntInptCrnt "IOnBdChrgrL1AltrCrntInptCrnt";
BA_ "LongName" SG_ 992 OnBdChrgrL1AltrCrntInptCrnt "On Board Charger Live Wire 1 Alternator Current Input Current";
BA_ "SysSignalName" SG_ 992 OnBdChrgrL1AltrCrntInptCrnt "OnBdChrgrL1AltrCrntInptCrnt";
BA_ "CompuMethodName" SG_ 992 OnBdChrgrL1AltrCrntInptVol "OnBdChrgrL1AltrCrntInptVol";
BA_ "ISignalName" SG_ 992 OnBdChrgrL1AltrCrntInptVol "IOnBdChrgrL1AltrCrntInptVol";
BA_ "LongName" SG_ 992 OnBdChrgrL1AltrCrntInptVol "On Board Charger Live Wire 1 Alternator Current Input Voltage";
BA_ "SysSignalName" SG_ 992 OnBdChrgrL1AltrCrntInptVol "OnBdChrgrL1AltrCrntInptVol";
BA_ "CompuMethodName" SG_ 992 OnBdChrgrL2AltrCrntInptCrnt "OnBdChrgrL2AltrCrntInptCrnt";
BA_ "ISignalName" SG_ 992 OnBdChrgrL2AltrCrntInptCrnt "IOnBdChrgrL2AltrCrntInptCrnt";
BA_ "LongName" SG_ 992 OnBdChrgrL2AltrCrntInptCrnt "On Board Charger Live Wire 2 Alternator Current Input Current";
BA_ "SysSignalName" SG_ 992 OnBdChrgrL2AltrCrntInptCrnt "OnBdChrgrL2AltrCrntInptCrnt";
BA_ "CompuMethodName" SG_ 992 OnBdChrgrL2AltrCrntInptVol "OnBdChrgrL2AltrCrntInptVol";
BA_ "ISignalName" SG_ 992 OnBdChrgrL2AltrCrntInptVol "IOnBdChrgrL2AltrCrntInptVol";
BA_ "LongName" SG_ 992 OnBdChrgrL2AltrCrntInptVol "On Board Charger Live Wire 2 Alternator Current Input Voltage";
BA_ "SysSignalName" SG_ 992 OnBdChrgrL2AltrCrntInptVol "OnBdChrgrL2AltrCrntInptVol";
BA_ "CompuMethodName" SG_ 992 OnBdChrgrL3AltrCrntInptCrnt "OnBdChrgrL3AltrCrntInptCrnt";
BA_ "ISignalName" SG_ 992 OnBdChrgrL3AltrCrntInptCrnt "IOnBdChrgrL3AltrCrntInptCrnt";
BA_ "LongName" SG_ 992 OnBdChrgrL3AltrCrntInptCrnt "On Board Charger Live Wire 3 Alternator Current Input Current";
BA_ "SysSignalName" SG_ 992 OnBdChrgrL3AltrCrntInptCrnt "OnBdChrgrL3AltrCrntInptCrnt";
BA_ "CompuMethodName" SG_ 992 OnBdChrgrL3AltrCrntInptVol "OnBdChrgrL3AltrCrntInptVol";
BA_ "ISignalName" SG_ 992 OnBdChrgrL3AltrCrntInptVol "IOnBdChrgrL3AltrCrntInptVol";
BA_ "LongName" SG_ 992 OnBdChrgrL3AltrCrntInptVol "On Board Charger Live Wire 3 Alternator Current Input Voltage";
BA_ "SysSignalName" SG_ 992 OnBdChrgrL3AltrCrntInptVol "OnBdChrgrL3AltrCrntInptVol";
BA_ "CompuMethodName" SG_ 992 CCUActiveWkup "CCUActiveWkup";
BA_ "ISignalName" SG_ 992 CCUActiveWkup "ICCUActiveWkup";
BA_ "LongName" SG_ 992 CCUActiveWkup "CCUActive Wakeup";
BA_ "SysSignalName" SG_ 992 CCUActiveWkup "CCUActiveWkup";
BA_ "CompuMethodName" SG_ 992 CCUOnbdChrgrMaxChrgPwr "CCUOnbdChrgrMaxChrgPwr";
BA_ "ISignalName" SG_ 992 CCUOnbdChrgrMaxChrgPwr "ICCUOnbdChrgrMaxChrgPwr";
BA_ "LongName" SG_ 992 CCUOnbdChrgrMaxChrgPwr "Combined Charging Unit Onboard Charger Maximum Charge Power";
BA_ "SysSignalName" SG_ 992 CCUOnbdChrgrMaxChrgPwr "CCUOnbdChrgrMaxChrgPwr";
BA_ "CompuMethodName" SG_ 992 CCU_100ms_Group07_Reserved5 "CCU_100ms_Group07_Reserved5";
BA_ "GenSigStartValue" SG_ 992 CCU_100ms_Group07_Reserved5 15;
BA_ "ISignalName" SG_ 992 CCU_100ms_Group07_Reserved5 "ICCU_100ms_Group07_Reserved5";
BA_ "SysSignalName" SG_ 992 CCU_100ms_Group07_Reserved5 "CCU_100ms_Group07_Reserved5";
BA_ "CompuMethodName" SG_ 992 CCUOnbdChrgrPlugOn "CCUOnbdChrgrPlugOn";
BA_ "ISignalName" SG_ 992 CCUOnbdChrgrPlugOn "ICCUOnbdChrgrPlugOn";
BA_ "LongName" SG_ 992 CCUOnbdChrgrPlugOn "Combined Charging Unit Onboard Charger Plug On";
BA_ "SysSignalName" SG_ 992 CCUOnbdChrgrPlugOn "CCUOnbdChrgrPlugOn";
BA_ "CompuMethodName" SG_ 992 CCU_100ms_Group07_Reserved6 "CCU_100ms_Group07_Reserved6";
BA_ "GenSigStartValue" SG_ 992 CCU_100ms_Group07_Reserved6 15;
BA_ "ISignalName" SG_ 992 CCU_100ms_Group07_Reserved6 "ICCU_100ms_Group07_Reserved6";
BA_ "SysSignalName" SG_ 992 CCU_100ms_Group07_Reserved6 "CCU_100ms_Group07_Reserved6";
BA_ "CompuMethodName" SG_ 992 CCUOnbdChrgrSpRsn "CCUOnbdChrgrSpRsn";
BA_ "ISignalName" SG_ 992 CCUOnbdChrgrSpRsn "ICCUOnbdChrgrSpRsn";
BA_ "LongName" SG_ 992 CCUOnbdChrgrSpRsn "Combined Charging Unit Onboard Charger Stop Reason";
BA_ "SysSignalName" SG_ 992 CCUOnbdChrgrSpRsn "CCUOnbdChrgrSpRsn";
BA_ "CompuMethodName" SG_ 992 CCU_100ms_Group07_Reserved7 "CCU_100ms_Group07_Reserved7";
BA_ "GenSigStartValue" SG_ 992 CCU_100ms_Group07_Reserved7 255;
BA_ "ISignalName" SG_ 992 CCU_100ms_Group07_Reserved7 "ICCU_100ms_Group07_Reserved7";
BA_ "SysSignalName" SG_ 992 CCU_100ms_Group07_Reserved7 "CCU_100ms_Group07_Reserved7";
BA_ "CompuMethodName" SG_ 992 CCU_100ms_Group07_Reserved9 "CCU_100ms_Group07_Reserved9";
BA_ "GenSigStartValue" SG_ 992 CCU_100ms_Group07_Reserved9 3;
BA_ "ISignalName" SG_ 992 CCU_100ms_Group07_Reserved9 "ICCU_100ms_Group07_Reserved9";
BA_ "SysSignalName" SG_ 992 CCU_100ms_Group07_Reserved9 "CCU_100ms_Group07_Reserved9";
BA_ "CompuMethodName" SG_ 992 OnBdChrgrLastWkup "OnBdChrgrLastWkup";
BA_ "ISignalName" SG_ 992 OnBdChrgrLastWkup "IOnBdChrgrLastWkup";
BA_ "LongName" SG_ 992 OnBdChrgrLastWkup "On Board Charger Last Wakeup";
BA_ "SysSignalName" SG_ 992 OnBdChrgrLastWkup "OnBdChrgrLastWkup";
BA_ "CompuMethodName" SG_ 992 CCU_100ms_Group07_Reserved8 "CCU_100ms_Group07_Reserved8";
BA_ "GenSigStartValue" SG_ 992 CCU_100ms_Group07_Reserved8 31;
BA_ "ISignalName" SG_ 992 CCU_100ms_Group07_Reserved8 "ICCU_100ms_Group07_Reserved8";
BA_ "SysSignalName" SG_ 992 CCU_100ms_Group07_Reserved8 "CCU_100ms_Group07_Reserved8";
BA_ "CompuMethodName" SG_ 992 CCU_100ms_Group07_Reserved10 "CCU_100ms_Group07_Reserved10";
BA_ "GenSigStartValue" SG_ 992 CCU_100ms_Group07_Reserved10 1;
BA_ "ISignalName" SG_ 992 CCU_100ms_Group07_Reserved10 "ICCU_100ms_Group07_Reserved10";
BA_ "SysSignalName" SG_ 992 CCU_100ms_Group07_Reserved10 "CCU_100ms_Group07_Reserved10";
BA_ "CompuMethodName" SG_ 992 OnBdChrgrCtrlPilotPWMDuty "OnBdChrgrCtrlPilotPWMDuty";
BA_ "ISignalName" SG_ 992 OnBdChrgrCtrlPilotPWMDuty "IOnBdChrgrCtrlPilotPWMDuty";
BA_ "LongName" SG_ 992 OnBdChrgrCtrlPilotPWMDuty "On Board Charger Control Pilot Pulse Width Modulation Duty";
BA_ "SysSignalName" SG_ 992 OnBdChrgrCtrlPilotPWMDuty "OnBdChrgrCtrlPilotPWMDuty";
BA_ "CompuMethodName" SG_ 992 CCU_100ms_Group07_Reserved11 "CCU_100ms_Group07_Reserved11";
BA_ "GenSigStartValue" SG_ 992 CCU_100ms_Group07_Reserved11 255;
BA_ "ISignalName" SG_ 992 CCU_100ms_Group07_Reserved11 "ICCU_100ms_Group07_Reserved11";
BA_ "SysSignalName" SG_ 992 CCU_100ms_Group07_Reserved11 "CCU_100ms_Group07_Reserved11";
BA_ "CompuMethodName" SG_ 966 CCU_100ms_Group11_CRC "CCU_100ms_Group11_CRC";
BA_ "ISignalName" SG_ 966 CCU_100ms_Group11_CRC "ICCU_100ms_Group11_CRC";
BA_ "LongName" SG_ 966 CCU_100ms_Group11_CRC "CCU_100ms_Group11_CRC";
BA_ "SysSignalName" SG_ 966 CCU_100ms_Group11_CRC "CCU_100ms_Group11_CRC";
BA_ "CompuMethodName" SG_ 966 CCU_100ms_Group11_RC "CCU_100ms_Group11_RC";
BA_ "ISignalName" SG_ 966 CCU_100ms_Group11_RC "ICCU_100ms_Group11_RC";
BA_ "LongName" SG_ 966 CCU_100ms_Group11_RC "CCU_100ms_Group11_RC";
BA_ "SysSignalName" SG_ 966 CCU_100ms_Group11_RC "CCU_100ms_Group11_RC";
BA_ "CompuMethodName" SG_ 966 CCU_100ms_Group11_Reserved1 "CCU_100ms_Group11_Reserved1";
BA_ "GenSigStartValue" SG_ 966 CCU_100ms_Group11_Reserved1 3;
BA_ "ISignalName" SG_ 966 CCU_100ms_Group11_Reserved1 "ICCU_100ms_Group11_Reserved1";
BA_ "SysSignalName" SG_ 966 CCU_100ms_Group11_Reserved1 "CCU_100ms_Group11_Reserved1";
BA_ "CompuMethodName" SG_ 966 AirCtrlrHVILClsd "AirCtrlrHVILClsd";
BA_ "ISignalName" SG_ 966 AirCtrlrHVILClsd "IAirCtrlrHVILClsd";
BA_ "LongName" SG_ 966 AirCtrlrHVILClsd "Air Controller High Voltage Interlock Loop Closed";
BA_ "SysSignalName" SG_ 966 AirCtrlrHVILClsd "AirCtrlrHVILClsd";
BA_ "CompuMethodName" SG_ 966 CCU_100ms_Group11_Reserved2 "CCU_100ms_Group11_Reserved2";
BA_ "GenSigStartValue" SG_ 966 CCU_100ms_Group11_Reserved2 255;
BA_ "ISignalName" SG_ 966 CCU_100ms_Group11_Reserved2 "ICCU_100ms_Group11_Reserved2";
BA_ "SysSignalName" SG_ 966 CCU_100ms_Group11_Reserved2 "CCU_100ms_Group11_Reserved2";
BA_ "CompuMethodName" SG_ 966 CCUClntFlowReq "CCUClntFlowReq";
BA_ "ISignalName" SG_ 966 CCUClntFlowReq "ICCUClntFlowReq";
BA_ "LongName" SG_ 966 CCUClntFlowReq "Combined Charging Unit Coolant Flow Request";
BA_ "SysSignalName" SG_ 966 CCUClntFlowReq "CCUClntFlowReq";
BA_ "CompuMethodName" SG_ 966 CCU_100ms_Group11_Reserved3 "CCU_100ms_Group11_Reserved3";
BA_ "GenSigStartValue" SG_ 966 CCU_100ms_Group11_Reserved3 255;
BA_ "ISignalName" SG_ 966 CCU_100ms_Group11_Reserved3 "ICCU_100ms_Group11_Reserved3";
BA_ "SysSignalName" SG_ 966 CCU_100ms_Group11_Reserved3 "CCU_100ms_Group11_Reserved3";
BA_ "CompuMethodName" SG_ 966 HVDCDCClntPumpPWMReq "HVDCDCClntPumpPWMReq";
BA_ "ISignalName" SG_ 966 HVDCDCClntPumpPWMReq "IHVDCDCClntPumpPWMReq";
BA_ "LongName" SG_ 966 HVDCDCClntPumpPWMReq "High Voltage Direct Current Direct Current Coolant Pump Pulse Width Modulation Request";
BA_ "SysSignalName" SG_ 966 HVDCDCClntPumpPWMReq "HVDCDCClntPumpPWMReq";
BA_ "CompuMethodName" SG_ 966 AirCtrlrHVILClsdV "AirCtrlrHVILClsdV";
BA_ "GenSigStartValue" SG_ 966 AirCtrlrHVILClsdV 1;
BA_ "ISignalName" SG_ 966 AirCtrlrHVILClsdV "IAirCtrlrHVILClsdV";
BA_ "LongName" SG_ 966 AirCtrlrHVILClsdV "Air Controller High Voltage Interlock Loop Closed Validity";
BA_ "SysSignalName" SG_ 966 AirCtrlrHVILClsdV "AirCtrlrHVILClsdV";
BA_ "CompuMethodName" SG_ 966 ESSPTCHVILSts "ESSPTCHVILSts";
BA_ "ISignalName" SG_ 966 ESSPTCHVILSts "IESSPTCHVILSts";
BA_ "LongName" SG_ 966 ESSPTCHVILSts "Energy Store System PTC High Voltage Interlock Loop Status";
BA_ "SysSignalName" SG_ 966 ESSPTCHVILSts "ESSPTCHVILSts";
BA_ "CompuMethodName" SG_ 966 CCUOnbdChrgrSktEleccLckEnable "CCUOnbdChrgrSktEleccLckEnable";
BA_ "ISignalName" SG_ 966 CCUOnbdChrgrSktEleccLckEnable "ICCUOnbdChrgrSktEleccLckEnable";
BA_ "LongName" SG_ 966 CCUOnbdChrgrSktEleccLckEnable "Combined Charging Unit Onboard Charger Socket Electric Lock Enable";
BA_ "SysSignalName" SG_ 966 CCUOnbdChrgrSktEleccLckEnable "CCUOnbdChrgrSktEleccLckEnable";
BA_ "CompuMethodName" SG_ 966 CCU_100ms_Group11_Reserved4 "CCU_100ms_Group11_Reserved4";
BA_ "GenSigStartValue" SG_ 966 CCU_100ms_Group11_Reserved4 7;
BA_ "ISignalName" SG_ 966 CCU_100ms_Group11_Reserved4 "ICCU_100ms_Group11_Reserved4";
BA_ "SysSignalName" SG_ 966 CCU_100ms_Group11_Reserved4 "CCU_100ms_Group11_Reserved4";
BA_ "CompuMethodName" SG_ 966 CCU_100ms_Group11_Reserved6 "CCU_100ms_Group11_Reserved6";
BA_ "GenSigStartValue" SG_ 966 CCU_100ms_Group11_Reserved6 3;
BA_ "ISignalName" SG_ 966 CCU_100ms_Group11_Reserved6 "ICCU_100ms_Group11_Reserved6";
BA_ "SysSignalName" SG_ 966 CCU_100ms_Group11_Reserved6 "CCU_100ms_Group11_Reserved6";
BA_ "CompuMethodName" SG_ 966 HVDCDCIntnlFlr "HVDCDCIntnlFlr";
BA_ "ISignalName" SG_ 966 HVDCDCIntnlFlr "IHVDCDCIntnlFlr";
BA_ "LongName" SG_ 966 HVDCDCIntnlFlr "High Voltage Direct Current Direct Current Internal Failure";
BA_ "SysSignalName" SG_ 966 HVDCDCIntnlFlr "HVDCDCIntnlFlr";
BA_ "CompuMethodName" SG_ 966 HVDCDCHdwrFlr "HVDCDCHdwrFlr";
BA_ "ISignalName" SG_ 966 HVDCDCHdwrFlr "IHVDCDCHdwrFlr";
BA_ "LongName" SG_ 966 HVDCDCHdwrFlr "High Voltage Direct Current Direct Current Hardware Failure";
BA_ "SysSignalName" SG_ 966 HVDCDCHdwrFlr "HVDCDCHdwrFlr";
BA_ "CompuMethodName" SG_ 966 ESSPTCHVILStsV "ESSPTCHVILStsV";
BA_ "GenSigStartValue" SG_ 966 ESSPTCHVILStsV 1;
BA_ "ISignalName" SG_ 966 ESSPTCHVILStsV "IESSPTCHVILStsV";
BA_ "LongName" SG_ 966 ESSPTCHVILStsV "Energy Store System PTC High Voltage Interlock Loop Status Validity";
BA_ "SysSignalName" SG_ 966 ESSPTCHVILStsV "ESSPTCHVILStsV";
BA_ "CompuMethodName" SG_ 966 CCU_100ms_Group11_Reserved5 "CCU_100ms_Group11_Reserved5";
BA_ "GenSigStartValue" SG_ 966 CCU_100ms_Group11_Reserved5 7;
BA_ "ISignalName" SG_ 966 CCU_100ms_Group11_Reserved5 "ICCU_100ms_Group11_Reserved5";
BA_ "SysSignalName" SG_ 966 CCU_100ms_Group11_Reserved5 "CCU_100ms_Group11_Reserved5";
BA_ "CompuMethodName" SG_ 966 CCU_100ms_Group11_Reserved7 "CCU_100ms_Group11_Reserved7";
BA_ "GenSigStartValue" SG_ 966 CCU_100ms_Group11_Reserved7 255;
BA_ "ISignalName" SG_ 966 CCU_100ms_Group11_Reserved7 "ICCU_100ms_Group11_Reserved7";
BA_ "SysSignalName" SG_ 966 CCU_100ms_Group11_Reserved7 "CCU_100ms_Group11_Reserved7";
BA_ "CompuMethodName" SG_ 966 CCU_100ms_Group11_Reserved8 "CCU_100ms_Group11_Reserved8";
BA_ "GenSigStartValue" SG_ 966 CCU_100ms_Group11_Reserved8 255;
BA_ "ISignalName" SG_ 966 CCU_100ms_Group11_Reserved8 "ICCU_100ms_Group11_Reserved8";
BA_ "SysSignalName" SG_ 966 CCU_100ms_Group11_Reserved8 "CCU_100ms_Group11_Reserved8";
BA_ "CompuMethodName" SG_ 966 CCU_100ms_Group11_Reserved9 "CCU_100ms_Group11_Reserved9";
BA_ "GenSigStartValue" SG_ 966 CCU_100ms_Group11_Reserved9 255;
BA_ "ISignalName" SG_ 966 CCU_100ms_Group11_Reserved9 "ICCU_100ms_Group11_Reserved9";
BA_ "SysSignalName" SG_ 966 CCU_100ms_Group11_Reserved9 "CCU_100ms_Group11_Reserved9";
BA_ "CompuMethodName" SG_ 966 CCU_100ms_Group11_Reserved10 "CCU_100ms_Group11_Reserved10";
BA_ "GenSigStartValue" SG_ 966 CCU_100ms_Group11_Reserved10 255;
BA_ "ISignalName" SG_ 966 CCU_100ms_Group11_Reserved10 "ICCU_100ms_Group11_Reserved10";
BA_ "SysSignalName" SG_ 966 CCU_100ms_Group11_Reserved10 "CCU_100ms_Group11_Reserved10";
BA_ "CompuMethodName" SG_ 966 CCU_100ms_Group11_Reserved11 "CCU_100ms_Group11_Reserved11";
BA_ "GenSigStartValue" SG_ 966 CCU_100ms_Group11_Reserved11 255;
BA_ "ISignalName" SG_ 966 CCU_100ms_Group11_Reserved11 "ICCU_100ms_Group11_Reserved11";
BA_ "SysSignalName" SG_ 966 CCU_100ms_Group11_Reserved11 "CCU_100ms_Group11_Reserved11";
BA_ "CompuMethodName" SG_ 966 CCU_100ms_Group11_Reserved12 "CCU_100ms_Group11_Reserved12";
BA_ "GenSigStartValue" SG_ 966 CCU_100ms_Group11_Reserved12 255;
BA_ "ISignalName" SG_ 966 CCU_100ms_Group11_Reserved12 "ICCU_100ms_Group11_Reserved12";
BA_ "SysSignalName" SG_ 966 CCU_100ms_Group11_Reserved12 "CCU_100ms_Group11_Reserved12";
BA_ "CompuMethodName" SG_ 966 CCU_100ms_Group11_Reserved13 "CCU_100ms_Group11_Reserved13";
BA_ "GenSigStartValue" SG_ 966 CCU_100ms_Group11_Reserved13 255;
BA_ "ISignalName" SG_ 966 CCU_100ms_Group11_Reserved13 "ICCU_100ms_Group11_Reserved13";
BA_ "SysSignalName" SG_ 966 CCU_100ms_Group11_Reserved13 "CCU_100ms_Group11_Reserved13";
BA_ "CompuMethodName" SG_ 966 CCU_100ms_Group11_Reserved14 "CCU_100ms_Group11_Reserved14";
BA_ "GenSigStartValue" SG_ 966 CCU_100ms_Group11_Reserved14 255;
BA_ "ISignalName" SG_ 966 CCU_100ms_Group11_Reserved14 "ICCU_100ms_Group11_Reserved14";
BA_ "SysSignalName" SG_ 966 CCU_100ms_Group11_Reserved14 "CCU_100ms_Group11_Reserved14";
BA_ "CompuMethodName" SG_ 1248 CCU_NM_BSMtoRMS_PTCANFD "CCU_NM_BSMtoRMS_PTCANFD";
BA_ "ISignalName" SG_ 1248 CCU_NM_BSMtoRMS_PTCANFD "ICCU_NM_BSMtoRMS_PTCANFD";
BA_ "LongName" SG_ 1248 CCU_NM_BSMtoRMS_PTCANFD "CCU_NM_BSMtoRMS_PTCANFD";
BA_ "SysSignalName" SG_ 1248 CCU_NM_BSMtoRMS_PTCANFD "CCU_NM_BSMtoRMS_PTCANFD";
BA_ "CompuMethodName" SG_ 1248 CCU_NM_PBSMtoRMS_PTCANFD "CCU_NM_PBSMtoRMS_PTCANFD";
BA_ "ISignalName" SG_ 1248 CCU_NM_PBSMtoRMS_PTCANFD "ICCU_NM_PBSMtoRMS_PTCANFD";
BA_ "LongName" SG_ 1248 CCU_NM_PBSMtoRMS_PTCANFD "CCU_NM_PBSMtoRMS_PTCANFD";
BA_ "SysSignalName" SG_ 1248 CCU_NM_PBSMtoRMS_PTCANFD "CCU_NM_PBSMtoRMS_PTCANFD";
BA_ "CompuMethodName" SG_ 1248 CCU_NM_RMStoNOS_PTCANFD "CCU_NM_RMStoNOS_PTCANFD";
BA_ "ISignalName" SG_ 1248 CCU_NM_RMStoNOS_PTCANFD "ICCU_NM_RMStoNOS_PTCANFD";
BA_ "LongName" SG_ 1248 CCU_NM_RMStoNOS_PTCANFD "CCU_NM_RMStoNOS_PTCANFD";
BA_ "SysSignalName" SG_ 1248 CCU_NM_RMStoNOS_PTCANFD "CCU_NM_RMStoNOS_PTCANFD";
BA_ "CompuMethodName" SG_ 1248 CCU_NM_RSStoNOS_PTCANFD "CCU_NM_RSStoNOS_PTCANFD";
BA_ "ISignalName" SG_ 1248 CCU_NM_RSStoNOS_PTCANFD "ICCU_NM_RSStoNOS_PTCANFD";
BA_ "LongName" SG_ 1248 CCU_NM_RSStoNOS_PTCANFD "CCU_NM_RSStoNOS_PTCANFD";
BA_ "SysSignalName" SG_ 1248 CCU_NM_RSStoNOS_PTCANFD "CCU_NM_RSStoNOS_PTCANFD";
BA_ "CompuMethodName" SG_ 1248 CCU_NM_RSStoRMS_PTCANFD "CCU_NM_RSStoRMS_PTCANFD";
BA_ "ISignalName" SG_ 1248 CCU_NM_RSStoRMS_PTCANFD "ICCU_NM_RSStoRMS_PTCANFD";
BA_ "LongName" SG_ 1248 CCU_NM_RSStoRMS_PTCANFD "CCU_NM_RSStoRMS_PTCANFD";
BA_ "SysSignalName" SG_ 1248 CCU_NM_RSStoRMS_PTCANFD "CCU_NM_RSStoRMS_PTCANFD";
BA_ "CompuMethodName" SG_ 1248 CCU_NM_NOStoRMS_PTCANFD "CCU_NM_NOStoRMS_PTCANFD";
BA_ "ISignalName" SG_ 1248 CCU_NM_NOStoRMS_PTCANFD "ICCU_NM_NOStoRMS_PTCANFD";
BA_ "LongName" SG_ 1248 CCU_NM_NOStoRMS_PTCANFD "CCU_NM_NOStoRMS_PTCANFD";
BA_ "SysSignalName" SG_ 1248 CCU_NM_NOStoRMS_PTCANFD "CCU_NM_NOStoRMS_PTCANFD";
BA_ "CompuMethodName" SG_ 1248 CCU_NM_NOSSta_PTCANFD "CCU_NM_NOSSta_PTCANFD";
BA_ "ISignalName" SG_ 1248 CCU_NM_NOSSta_PTCANFD "ICCU_NM_NOSSta_PTCANFD";
BA_ "LongName" SG_ 1248 CCU_NM_NOSSta_PTCANFD "CCU_NM_NOSSta_PTCANFD";
BA_ "SysSignalName" SG_ 1248 CCU_NM_NOSSta_PTCANFD "CCU_NM_NOSSta_PTCANFD";
BA_ "CompuMethodName" SG_ 1248 CCU_NM_RMSSta_PTCANFD "CCU_NM_RMSSta_PTCANFD";
BA_ "ISignalName" SG_ 1248 CCU_NM_RMSSta_PTCANFD "ICCU_NM_RMSSta_PTCANFD";
BA_ "LongName" SG_ 1248 CCU_NM_RMSSta_PTCANFD "CCU_NM_RMSSta_PTCANFD";
BA_ "SysSignalName" SG_ 1248 CCU_NM_RMSSta_PTCANFD "CCU_NM_RMSSta_PTCANFD";
BA_ "CompuMethodName" SG_ 1248 CCU_NWI_PTCANFD "CCU_NWI_PTCANFD";
BA_ "ISignalName" SG_ 1248 CCU_NWI_PTCANFD "ICCU_NWI_PTCANFD";
BA_ "LongName" SG_ 1248 CCU_NWI_PTCANFD "CCU_PTCANFD Network Wakeup Indication";
BA_ "SysSignalName" SG_ 1248 CCU_NWI_PTCANFD "CCU_NWI_PTCANFD";
BA_ "CompuMethodName" SG_ 1248 CCU_NOI_PTCANFD "CCU_NOI_PTCANFD";
BA_ "ISignalName" SG_ 1248 CCU_NOI_PTCANFD "ICCU_NOI_PTCANFD";
BA_ "LongName" SG_ 1248 CCU_NOI_PTCANFD "CCU PTCANFD Network Operation Indication";
BA_ "SysSignalName" SG_ 1248 CCU_NOI_PTCANFD "CCU_NOI_PTCANFD";
BA_ "CompuMethodName" SG_ 1248 CCU_NKI_PTCANFD "CCU_NKI_PTCANFD";
BA_ "ISignalName" SG_ 1248 CCU_NKI_PTCANFD "ICCU_NKI_PTCANFD";
BA_ "LongName" SG_ 1248 CCU_NKI_PTCANFD "CCU PTCANFD Network Keep Indication";
BA_ "SysSignalName" SG_ 1248 CCU_NKI_PTCANFD "CCU_NKI_PTCANFD";
BA_ "CompuMethodName" SG_ 132 ECM_010ms_Group00_CRC "ECM_010ms_Group00_CRC";
BA_ "ISignalName" SG_ 132 ECM_010ms_Group00_CRC "IECM_010ms_Group00_CRC";
BA_ "LongName" SG_ 132 ECM_010ms_Group00_CRC "ECM_010ms_Group00_CRC";
BA_ "SysSignalName" SG_ 132 ECM_010ms_Group00_CRC "ECM_010ms_Group00_CRC";
BA_ "CompuMethodName" SG_ 132 ECM_010ms_Group00_RC "ECM_010ms_Group00_RC";
BA_ "ISignalName" SG_ 132 ECM_010ms_Group00_RC "IECM_010ms_Group00_RC";
BA_ "LongName" SG_ 132 ECM_010ms_Group00_RC "ECM_010ms_Group00_RC";
BA_ "SysSignalName" SG_ 132 ECM_010ms_Group00_RC "ECM_010ms_Group00_RC";
BA_ "CompuMethodName" SG_ 132 EnActuStdyStaToqV "EnActuStdyStaToqV";
BA_ "ISignalName" SG_ 132 EnActuStdyStaToqV "IEnActuStdyStaToqV";
BA_ "LongName" SG_ 132 EnActuStdyStaToqV "Engine Actual Steady State Torque Validity";
BA_ "SysSignalName" SG_ 132 EnActuStdyStaToqV "EnActuStdyStaToqV";
BA_ "CompuMethodName" SG_ 132 EnRunA "EnRunA";
BA_ "ISignalName" SG_ 132 EnRunA "IEnRunA";
BA_ "LongName" SG_ 132 EnRunA "EngineRunActive";
BA_ "SysSignalName" SG_ 132 EnRunA "EnRunA";
BA_ "CompuMethodName" SG_ 132 EnSpdSts "EnSpdSts";
BA_ "ISignalName" SG_ 132 EnSpdSts "IEnSpdSts";
BA_ "LongName" SG_ 132 EnSpdSts "Engine Speed Status";
BA_ "SysSignalName" SG_ 132 EnSpdSts "EnSpdSts";
BA_ "CompuMethodName" SG_ 132 EnSpd "EnSpd";
BA_ "ISignalName" SG_ 132 EnSpd "IEnSpd";
BA_ "LongName" SG_ 132 EnSpd "Engine Speed";
BA_ "SysSignalName" SG_ 132 EnSpd "EnSpd";
BA_ "CompuMethodName" SG_ 132 ClOpenReqA "ClOpenReqA";
BA_ "ISignalName" SG_ 132 ClOpenReqA "IClOpenReqA";
BA_ "LongName" SG_ 132 ClOpenReqA "Clutch Open Request A";
BA_ "SysSignalName" SG_ 132 ClOpenReqA "ClOpenReqA";
BA_ "CompuMethodName" SG_ 132 EnCtrlrRunCrkTrmlSts "EnCtrlrRunCrkTrmlSts";
BA_ "ISignalName" SG_ 132 EnCtrlrRunCrkTrmlSts "IEnCtrlrRunCrkTrmlSts";
BA_ "LongName" SG_ 132 EnCtrlrRunCrkTrmlSts "Engine Controller Run Crank Terminal Status";
BA_ "SysSignalName" SG_ 132 EnCtrlrRunCrkTrmlSts "EnCtrlrRunCrkTrmlSts";
BA_ "CompuMethodName" SG_ 132 IntlckRelayAuth "IntlckRelayAuth";
BA_ "ISignalName" SG_ 132 IntlckRelayAuth "IIntlckRelayAuth";
BA_ "LongName" SG_ 132 IntlckRelayAuth "Interlock Relay Authorization";
BA_ "SysSignalName" SG_ 132 IntlckRelayAuth "IntlckRelayAuth";
BA_ "CompuMethodName" SG_ 132 RVSPtCrkAbotd "RVSPtCrkAbotd";
BA_ "ISignalName" SG_ 132 RVSPtCrkAbotd "IRVSPtCrkAbotd";
BA_ "SysSignalName" SG_ 132 RVSPtCrkAbotd "RVSPtCrkAbotd";
BA_ "CompuMethodName" SG_ 132 RVSPtRunAbotd "RVSPtRunAbotd";
BA_ "ISignalName" SG_ 132 RVSPtRunAbotd "IRVSPtRunAbotd";
BA_ "SysSignalName" SG_ 132 RVSPtRunAbotd "RVSPtRunAbotd";
BA_ "CompuMethodName" SG_ 132 EnTestMdEnbReq "EnTestMdEnbReq";
BA_ "ISignalName" SG_ 132 EnTestMdEnbReq "IEnTestMdEnbReq";
BA_ "LongName" SG_ 132 EnTestMdEnbReq "Engine Test Mode Enable Request";
BA_ "SysSignalName" SG_ 132 EnTestMdEnbReq "EnTestMdEnbReq";
BA_ "CompuMethodName" SG_ 132 ECM_010ms_Group00_Reserved39 "ECM_010ms_Group00_Reserved39";
BA_ "GenSigStartValue" SG_ 132 ECM_010ms_Group00_Reserved39 3;
BA_ "ISignalName" SG_ 132 ECM_010ms_Group00_Reserved39 "IECM_010ms_Group00_Reserved39";
BA_ "SysSignalName" SG_ 132 ECM_010ms_Group00_Reserved39 "ECM_010ms_Group00_Reserved39";
BA_ "CompuMethodName" SG_ 132 EnActuStdyStaToq "EnActuStdyStaToq";
BA_ "ISignalName" SG_ 132 EnActuStdyStaToq "IEnActuStdyStaToq";
BA_ "LongName" SG_ 132 EnActuStdyStaToq "Engine Actual Steady State Torque";
BA_ "SysSignalName" SG_ 132 EnActuStdyStaToq "EnActuStdyStaToq";
BA_ "CompuMethodName" SG_ 132 EnSpReqToTr "EnSpReqToTr";
BA_ "ISignalName" SG_ 132 EnSpReqToTr "IEnSpReqToTr";
BA_ "LongName" SG_ 132 EnSpReqToTr "Engine Stop Request To Transmission";
BA_ "SysSignalName" SG_ 132 EnSpReqToTr "EnSpReqToTr";
BA_ "CompuMethodName" SG_ 132 EnCCMd "EnCCMd";
BA_ "ISignalName" SG_ 132 EnCCMd "IEnCCMd";
BA_ "LongName" SG_ 132 EnCCMd "Engine Cruise Control Mode";
BA_ "SysSignalName" SG_ 132 EnCCMd "EnCCMd";
BA_ "CompuMethodName" SG_ 132 ECM_010ms_Group00_Reserved63 "ECM_010ms_Group00_Reserved63";
BA_ "GenSigStartValue" SG_ 132 ECM_010ms_Group00_Reserved63 255;
BA_ "ISignalName" SG_ 132 ECM_010ms_Group00_Reserved63 "IECM_010ms_Group00_Reserved63";
BA_ "SysSignalName" SG_ 132 ECM_010ms_Group00_Reserved63 "ECM_010ms_Group00_Reserved63";
BA_ "CompuMethodName" SG_ 1365 ECM_500ms_group02_CRC "ECM_500ms_group02_CRC";
BA_ "ISignalName" SG_ 1365 ECM_500ms_group02_CRC "IECM_500ms_group02_CRC";
BA_ "LongName" SG_ 1365 ECM_500ms_group02_CRC "ECM_500ms_group02_CRC";
BA_ "SysSignalName" SG_ 1365 ECM_500ms_group02_CRC "ECM_500ms_group02_CRC";
BA_ "CompuMethodName" SG_ 1365 ECM_500ms_group02_RC "ECM_500ms_group02_RC";
BA_ "ISignalName" SG_ 1365 ECM_500ms_group02_RC "IECM_500ms_group02_RC";
BA_ "LongName" SG_ 1365 ECM_500ms_group02_RC "ECM_500ms_group02_RC";
BA_ "SysSignalName" SG_ 1365 ECM_500ms_group02_RC "ECM_500ms_group02_RC";
BA_ "CompuMethodName" SG_ 1365 TrClThrmlProtnNotfn_ECM "TrClThrmlProtnNotfn_ECM";
BA_ "ISignalName" SG_ 1365 TrClThrmlProtnNotfn_ECM "ITrClThrmlProtnNotfn_ECM";
BA_ "LongName" SG_ 1365 TrClThrmlProtnNotfn_ECM "Transmission Clutch Thermal Protection Notification";
BA_ "SysSignalName" SG_ 1365 TrClThrmlProtnNotfn_ECM "TrClThrmlProtnNotfn_ECM";
BA_ "CompuMethodName" SG_ 1365 BarPrsAbs "BarPrsAbs";
BA_ "GenSigStartValue" SG_ 1365 BarPrsAbs 200;
BA_ "ISignalName" SG_ 1365 BarPrsAbs "IBarPrsAbs";
BA_ "LongName" SG_ 1365 BarPrsAbs "Barometric Pressure Absolute";
BA_ "SysSignalName" SG_ 1365 BarPrsAbs "BarPrsAbs";
BA_ "CompuMethodName" SG_ 1365 EnClntTem "EnClntTem";
BA_ "ISignalName" SG_ 1365 EnClntTem "IEnClntTem";
BA_ "LongName" SG_ 1365 EnClntTem "Engine Coolant Temperature";
BA_ "SysSignalName" SG_ 1365 EnClntTem "EnClntTem";
BA_ "CompuMethodName" SG_ 1365 EnIntkAirTem "EnIntkAirTem";
BA_ "ISignalName" SG_ 1365 EnIntkAirTem "IEnIntkAirTem";
BA_ "LongName" SG_ 1365 EnIntkAirTem "Engine Intake Air Temperature";
BA_ "SysSignalName" SG_ 1365 EnIntkAirTem "EnIntkAirTem";
BA_ "CompuMethodName" SG_ 1365 BarPrsAbsOBD "BarPrsAbsOBD";
BA_ "ISignalName" SG_ 1365 BarPrsAbsOBD "IBarPrsAbsOBD";
BA_ "LongName" SG_ 1365 BarPrsAbsOBD "Barometric Pressure Absolute On Board Diagnostics";
BA_ "SysSignalName" SG_ 1365 BarPrsAbsOBD "BarPrsAbsOBD";
BA_ "CompuMethodName" SG_ 1365 OtsdAirTemPtEstd "OtsdAirTemPtEstd";
BA_ "ISignalName" SG_ 1365 OtsdAirTemPtEstd "IOtsdAirTemPtEstd";
BA_ "LongName" SG_ 1365 OtsdAirTemPtEstd "Outside Air Temperature Powertrain Estimated";
BA_ "SysSignalName" SG_ 1365 OtsdAirTemPtEstd "OtsdAirTemPtEstd";
BA_ "CompuMethodName" SG_ 1365 ECM_500ms_group02_Reserved1 "ECM_500ms_group02_Reserved1";
BA_ "GenSigStartValue" SG_ 1365 ECM_500ms_group02_Reserved1 3;
BA_ "ISignalName" SG_ 1365 ECM_500ms_group02_Reserved1 "IECM_500ms_group02_Reserved1";
BA_ "SysSignalName" SG_ 1365 ECM_500ms_group02_Reserved1 "ECM_500ms_group02_Reserved1";
BA_ "CompuMethodName" SG_ 1365 OtsdAirTemPtEstdV "OtsdAirTemPtEstdV";
BA_ "ISignalName" SG_ 1365 OtsdAirTemPtEstdV "IOtsdAirTemPtEstdV";
BA_ "LongName" SG_ 1365 OtsdAirTemPtEstdV "Outside Air Temperature Powertrain Estimated Validity";
BA_ "SysSignalName" SG_ 1365 OtsdAirTemPtEstdV "OtsdAirTemPtEstdV";
BA_ "CompuMethodName" SG_ 1365 OtsdAirTemPtEstdMsk "OtsdAirTemPtEstdMsk";
BA_ "ISignalName" SG_ 1365 OtsdAirTemPtEstdMsk "IOtsdAirTemPtEstdMsk";
BA_ "LongName" SG_ 1365 OtsdAirTemPtEstdMsk "Outside Air Temperature Powertrain Estimated Mask";
BA_ "SysSignalName" SG_ 1365 OtsdAirTemPtEstdMsk "OtsdAirTemPtEstdMsk";
BA_ "CompuMethodName" SG_ 1365 EnClntTemV "EnClntTemV";
BA_ "GenSigStartValue" SG_ 1365 EnClntTemV 1;
BA_ "ISignalName" SG_ 1365 EnClntTemV "IEnClntTemV";
BA_ "LongName" SG_ 1365 EnClntTemV "Engine Coolant Temperature Validity";
BA_ "SysSignalName" SG_ 1365 EnClntTemV "EnClntTemV";
BA_ "CompuMethodName" SG_ 1365 EnWarmUpCycAch "EnWarmUpCycAch";
BA_ "ISignalName" SG_ 1365 EnWarmUpCycAch "IEnWarmUpCycAch";
BA_ "LongName" SG_ 1365 EnWarmUpCycAch "Engine Warm Up Cycle Achieved";
BA_ "SysSignalName" SG_ 1365 EnWarmUpCycAch "EnWarmUpCycAch";
BA_ "CompuMethodName" SG_ 1365 EnIntkAirTemV "EnIntkAirTemV";
BA_ "ISignalName" SG_ 1365 EnIntkAirTemV "IEnIntkAirTemV";
BA_ "LongName" SG_ 1365 EnIntkAirTemV "Engine Intake Air Temperature Validity";
BA_ "SysSignalName" SG_ 1365 EnIntkAirTemV "EnIntkAirTemV";
BA_ "CompuMethodName" SG_ 1365 BarPrsAbsV "BarPrsAbsV";
BA_ "GenSigStartValue" SG_ 1365 BarPrsAbsV 1;
BA_ "ISignalName" SG_ 1365 BarPrsAbsV "IBarPrsAbsV";
BA_ "LongName" SG_ 1365 BarPrsAbsV "Barometric Pressure Absolute Validity";
BA_ "SysSignalName" SG_ 1365 BarPrsAbsV "BarPrsAbsV";
BA_ "CompuMethodName" SG_ 531 ECM_ZONE_050ms_Group09_CRC "ECM_ZONE_050ms_Group09_CRC";
BA_ "ISignalName" SG_ 531 ECM_ZONE_050ms_Group09_CRC "IECM_ZONE_050ms_Group09_CRC";
BA_ "SysSignalName" SG_ 531 ECM_ZONE_050ms_Group09_CRC "ECM_ZONE_050ms_Group09_CRC";
BA_ "CompuMethodName" SG_ 531 ECM_ZONE_050ms_Group09_RC "ECM_ZONE_050ms_Group09_RC";
BA_ "ISignalName" SG_ 531 ECM_ZONE_050ms_Group09_RC "IECM_ZONE_050ms_Group09_RC";
BA_ "SysSignalName" SG_ 531 ECM_ZONE_050ms_Group09_RC "ECM_ZONE_050ms_Group09_RC";
BA_ "CompuMethodName" SG_ 531 ECODrvngSpdRutA "ECODrvngSpdRutA";
BA_ "ISignalName" SG_ 531 ECODrvngSpdRutA "IECODrvngSpdRutA";
BA_ "LongName" SG_ 531 ECODrvngSpdRutA "Ecology Conservation Optimization Driving Speed Route A";
BA_ "SysSignalName" SG_ 531 ECODrvngSpdRutA "ECODrvngSpdRutA";
BA_ "CompuMethodName" SG_ 531 EcoDrvngAIO "EcoDrvngAIO";
BA_ "ISignalName" SG_ 531 EcoDrvngAIO "IEcoDrvngAIO";
BA_ "LongName" SG_ 531 EcoDrvngAIO "Economy Driving A Indication On";
BA_ "SysSignalName" SG_ 531 EcoDrvngAIO "EcoDrvngAIO";
BA_ "CompuMethodName" SG_ 531 EcoDrvngDspStsGearShftIndSts "EcoDrvngDspStsGearShftIndSts";
BA_ "ISignalName" SG_ 531 EcoDrvngDspStsGearShftIndSts "IEcoDrvngDspStsGearShftIndSts";
BA_ "LongName" SG_ 531 EcoDrvngDspStsGearShftIndSts "Economy Driving Display Status Gear Shift Indication Status";
BA_ "SysSignalName" SG_ 531 EcoDrvngDspStsGearShftIndSts "EcoDrvngDspStsGearShftIndSts";
BA_ "CompuMethodName" SG_ 531 EnToqMaxExtdRng "EnToqMaxExtdRng";
BA_ "ISignalName" SG_ 531 EnToqMaxExtdRng "IEnToqMaxExtdRng";
BA_ "LongName" SG_ 531 EnToqMaxExtdRng "Engine Torque Maximum Extended Range";
BA_ "SysSignalName" SG_ 531 EnToqMaxExtdRng "EnToqMaxExtdRng";
BA_ "CompuMethodName" SG_ 531 EnToqMinExtdRng "EnToqMinExtdRng";
BA_ "ISignalName" SG_ 531 EnToqMinExtdRng "IEnToqMinExtdRng";
BA_ "LongName" SG_ 531 EnToqMinExtdRng "Engine Torque Minimum Extended Range";
BA_ "SysSignalName" SG_ 531 EnToqMinExtdRng "EnToqMinExtdRng";
BA_ "CompuMethodName" SG_ 531 ECM_ZONE_050ms_Group09_Reserved1 "ECM_ZONE_050ms_Group09_Reserved1";
BA_ "GenSigStartValue" SG_ 531 ECM_ZONE_050ms_Group09_Reserved1 3;
BA_ "ISignalName" SG_ 531 ECM_ZONE_050ms_Group09_Reserved1 "IECM_ZONE_050ms_Group09_Reserved1";
BA_ "SysSignalName" SG_ 531 ECM_ZONE_050ms_Group09_Reserved1 "ECM_ZONE_050ms_Group09_Reserved1";
BA_ "CompuMethodName" SG_ 531 EnToqMinExtdRngV "EnToqMinExtdRngV";
BA_ "ISignalName" SG_ 531 EnToqMinExtdRngV "IEnToqMinExtdRngV";
BA_ "LongName" SG_ 531 EnToqMinExtdRngV "Engine Torque Minimum Extended Range Validity";
BA_ "SysSignalName" SG_ 531 EnToqMinExtdRngV "EnToqMinExtdRngV";
BA_ "CompuMethodName" SG_ 531 EnToqMaxExtdRngV "EnToqMaxExtdRngV";
BA_ "ISignalName" SG_ 531 EnToqMaxExtdRngV "IEnToqMaxExtdRngV";
BA_ "LongName" SG_ 531 EnToqMaxExtdRngV "Engine Torque Maximum Extended Range Validity";
BA_ "SysSignalName" SG_ 531 EnToqMaxExtdRngV "EnToqMaxExtdRngV";
BA_ "CompuMethodName" SG_ 531 EcoDrvngDspStsRcmndFwdGear "EcoDrvngDspStsRcmndFwdGear";
BA_ "ISignalName" SG_ 531 EcoDrvngDspStsRcmndFwdGear "IEcoDrvngDspStsRcmndFwdGear";
BA_ "LongName" SG_ 531 EcoDrvngDspStsRcmndFwdGear "Economy Driving Display Status Recommended Forward Gear";
BA_ "SysSignalName" SG_ 531 EcoDrvngDspStsRcmndFwdGear "EcoDrvngDspStsRcmndFwdGear";
BA_ "CompuMethodName" SG_ 531 ECM_ZONE_050ms_Group09_Reserved2 "ECM_ZONE_050ms_Group09_Reserved2";
BA_ "GenSigStartValue" SG_ 531 ECM_ZONE_050ms_Group09_Reserved2 255;
BA_ "ISignalName" SG_ 531 ECM_ZONE_050ms_Group09_Reserved2 "IECM_ZONE_050ms_Group09_Reserved2";
BA_ "SysSignalName" SG_ 531 ECM_ZONE_050ms_Group09_Reserved2 "ECM_ZONE_050ms_Group09_Reserved2";
BA_ "CompuMethodName" SG_ 531 ECM_ZONE_050ms_Group09_Reserved3 "ECM_ZONE_050ms_Group09_Reserved3";
BA_ "GenSigStartValue" SG_ 531 ECM_ZONE_050ms_Group09_Reserved3 255;
BA_ "ISignalName" SG_ 531 ECM_ZONE_050ms_Group09_Reserved3 "IECM_ZONE_050ms_Group09_Reserved3";
BA_ "SysSignalName" SG_ 531 ECM_ZONE_050ms_Group09_Reserved3 "ECM_ZONE_050ms_Group09_Reserved3";
BA_ "CompuMethodName" SG_ 451 ECM_020ms_PDU03_CRC "ECM_020ms_PDU03_CRC";
BA_ "ISignalName" SG_ 451 ECM_020ms_PDU03_CRC "IECM_020ms_PDU03_CRC";
BA_ "SysSignalName" SG_ 451 ECM_020ms_PDU03_CRC "ECM_020ms_PDU03_CRC";
BA_ "CompuMethodName" SG_ 451 ECM_020ms_PDU03_RC "ECM_020ms_PDU03_RC";
BA_ "ISignalName" SG_ 451 ECM_020ms_PDU03_RC "IECM_020ms_PDU03_RC";
BA_ "SysSignalName" SG_ 451 ECM_020ms_PDU03_RC "ECM_020ms_PDU03_RC";
BA_ "CompuMethodName" SG_ 451 EnToqActuExtdRngV "EnToqActuExtdRngV";
BA_ "ISignalName" SG_ 451 EnToqActuExtdRngV "IEnToqActuExtdRngV";
BA_ "LongName" SG_ 451 EnToqActuExtdRngV "Engine Torque Actual Extended Range Validity";
BA_ "SysSignalName" SG_ 451 EnToqActuExtdRngV "EnToqActuExtdRngV";
BA_ "CompuMethodName" SG_ 451 EnToqRducnFlrSts "EnToqRducnFlrSts";
BA_ "ISignalName" SG_ 451 EnToqRducnFlrSts "IEnToqRducnFlrSts";
BA_ "LongName" SG_ 451 EnToqRducnFlrSts "Engine Torque Reduction Failure Status";
BA_ "SysSignalName" SG_ 451 EnToqRducnFlrSts "EnToqRducnFlrSts";
BA_ "CompuMethodName" SG_ 451 EnToqDrvrReqdExtdRng "EnToqDrvrReqdExtdRng";
BA_ "ISignalName" SG_ 451 EnToqDrvrReqdExtdRng "IEnToqDrvrReqdExtdRng";
BA_ "LongName" SG_ 451 EnToqDrvrReqdExtdRng "Engine Torque Driver Requested Extended Range";
BA_ "SysSignalName" SG_ 451 EnToqDrvrReqdExtdRng "EnToqDrvrReqdExtdRng";
BA_ "CompuMethodName" SG_ 451 EnToqActuExtdRng "EnToqActuExtdRng";
BA_ "ISignalName" SG_ 451 EnToqActuExtdRng "IEnToqActuExtdRng";
BA_ "LongName" SG_ 451 EnToqActuExtdRng "Engine Torque Actual Extended Range";
BA_ "SysSignalName" SG_ 451 EnToqActuExtdRng "EnToqActuExtdRng";
BA_ "CompuMethodName" SG_ 451 PropSysA "PropSysA";
BA_ "ISignalName" SG_ 451 PropSysA "IPropSysA";
BA_ "LongName" SG_ 451 PropSysA "Propulsion System A";
BA_ "SysSignalName" SG_ 451 PropSysA "PropSysA";
BA_ "CompuMethodName" SG_ 451 EnAutoSpNotProb "EnAutoSpNotProb";
BA_ "ISignalName" SG_ 451 EnAutoSpNotProb "IEnAutoSpNotProb";
BA_ "LongName" SG_ 451 EnAutoSpNotProb "Engine Auto Stop Not Probable";
BA_ "SysSignalName" SG_ 451 EnAutoSpNotProb "EnAutoSpNotProb";
BA_ "CompuMethodName" SG_ 451 EnASSStallDet "EnASSStallDet";
BA_ "ISignalName" SG_ 451 EnASSStallDet "IEnASSStallDet";
BA_ "LongName" SG_ 451 EnASSStallDet "Engine Auto Stop Start Stall Detected";
BA_ "SysSignalName" SG_ 451 EnASSStallDet "EnASSStallDet";
BA_ "CompuMethodName" SG_ 451 EnASSSta "EnASSSta";
BA_ "GenSigStartValue" SG_ 451 EnASSSta 1;
BA_ "ISignalName" SG_ 451 EnASSSta "IEnASSSta";
BA_ "LongName" SG_ 451 EnASSSta "Engine Auto Stop Start State";
BA_ "SysSignalName" SG_ 451 EnASSSta "EnASSSta";
BA_ "CompuMethodName" SG_ 451 EnASSFuelReqdOn "EnASSFuelReqdOn";
BA_ "ISignalName" SG_ 451 EnASSFuelReqdOn "IEnASSFuelReqdOn";
BA_ "LongName" SG_ 451 EnASSFuelReqdOn "Engine Auto Stop Start Fuel Requested On";
BA_ "SysSignalName" SG_ 451 EnASSFuelReqdOn "EnASSFuelReqdOn";
BA_ "CompuMethodName" SG_ 451 EnASSFrngDet "EnASSFrngDet";
BA_ "ISignalName" SG_ 451 EnASSFrngDet "IEnASSFrngDet";
BA_ "LongName" SG_ 451 EnASSFrngDet "Engine Auto Stop Start Firing Detected";
BA_ "SysSignalName" SG_ 451 EnASSFrngDet "EnASSFrngDet";
BA_ "CompuMethodName" SG_ 451 EnToqDrvrReqdExtdRngV "EnToqDrvrReqdExtdRngV";
BA_ "ISignalName" SG_ 451 EnToqDrvrReqdExtdRngV "IEnToqDrvrReqdExtdRngV";
BA_ "LongName" SG_ 451 EnToqDrvrReqdExtdRngV "Engine Torque Driver Requested Extended Range Validity";
BA_ "SysSignalName" SG_ 451 EnToqDrvrReqdExtdRngV "EnToqDrvrReqdExtdRngV";
BA_ "CompuMethodName" SG_ 451 ECM_ZONE_020ms_Group03_Reserved1 "ECM_ZONE_020ms_Group03_Reserved1";
BA_ "GenSigStartValue" SG_ 451 ECM_ZONE_020ms_Group03_Reserved1 255;
BA_ "ISignalName" SG_ 451 ECM_ZONE_020ms_Group03_Reserved1 "IECM_ZONE_020ms_Group03_Reserved1";
BA_ "SysSignalName" SG_ 451 ECM_ZONE_020ms_Group03_Reserved1 "ECM_ZONE_020ms_Group03_Reserved1";
BA_ "CompuMethodName" SG_ 451 ECM_ZONE_020ms_Group03_Reserved2 "ECM_ZONE_020ms_Group03_Reserved2";
BA_ "GenSigStartValue" SG_ 451 ECM_ZONE_020ms_Group03_Reserved2 255;
BA_ "ISignalName" SG_ 451 ECM_ZONE_020ms_Group03_Reserved2 "IECM_ZONE_020ms_Group03_Reserved2";
BA_ "SysSignalName" SG_ 451 ECM_ZONE_020ms_Group03_Reserved2 "ECM_ZONE_020ms_Group03_Reserved2";
BA_ "CompuMethodName" SG_ 1249 ESS_NM_BSMtoRMS_PTCANFD "ESS_NM_BSMtoRMS_PTCANFD";
BA_ "ISignalName" SG_ 1249 ESS_NM_BSMtoRMS_PTCANFD "IESS_NM_BSMtoRMS_PTCANFD";
BA_ "LongName" SG_ 1249 ESS_NM_BSMtoRMS_PTCANFD "ESS_NM_BSMtoRMS_PTCANFD";
BA_ "SysSignalName" SG_ 1249 ESS_NM_BSMtoRMS_PTCANFD "ESS_NM_BSMtoRMS_PTCANFD";
BA_ "CompuMethodName" SG_ 1249 ESS_NM_PBSMtoRMS_PTCANFD "ESS_NM_PBSMtoRMS_PTCANFD";
BA_ "ISignalName" SG_ 1249 ESS_NM_PBSMtoRMS_PTCANFD "IESS_NM_PBSMtoRMS_PTCANFD";
BA_ "LongName" SG_ 1249 ESS_NM_PBSMtoRMS_PTCANFD "ESS_NM_PBSMtoRMS_PTCANFD";
BA_ "SysSignalName" SG_ 1249 ESS_NM_PBSMtoRMS_PTCANFD "ESS_NM_PBSMtoRMS_PTCANFD";
BA_ "CompuMethodName" SG_ 1249 ESS_NM_RMStoNOS_PTCANFD "ESS_NM_RMStoNOS_PTCANFD";
BA_ "ISignalName" SG_ 1249 ESS_NM_RMStoNOS_PTCANFD "IESS_NM_RMStoNOS_PTCANFD";
BA_ "LongName" SG_ 1249 ESS_NM_RMStoNOS_PTCANFD "ESS_NM_RMStoNOS_PTCANFD";
BA_ "SysSignalName" SG_ 1249 ESS_NM_RMStoNOS_PTCANFD "ESS_NM_RMStoNOS_PTCANFD";
BA_ "CompuMethodName" SG_ 1249 ESS_NM_RSStoNOS_PTCANFD "ESS_NM_RSStoNOS_PTCANFD";
BA_ "ISignalName" SG_ 1249 ESS_NM_RSStoNOS_PTCANFD "IESS_NM_RSStoNOS_PTCANFD";
BA_ "LongName" SG_ 1249 ESS_NM_RSStoNOS_PTCANFD "ESS_NM_RSStoNOS_PTCANFD";
BA_ "SysSignalName" SG_ 1249 ESS_NM_RSStoNOS_PTCANFD "ESS_NM_RSStoNOS_PTCANFD";
BA_ "CompuMethodName" SG_ 1249 ESS_NM_RSStoRMS_PTCANFD "ESS_NM_RSStoRMS_PTCANFD";
BA_ "ISignalName" SG_ 1249 ESS_NM_RSStoRMS_PTCANFD "IESS_NM_RSStoRMS_PTCANFD";
BA_ "LongName" SG_ 1249 ESS_NM_RSStoRMS_PTCANFD "ESS_NM_RSStoRMS_PTCANFD";
BA_ "SysSignalName" SG_ 1249 ESS_NM_RSStoRMS_PTCANFD "ESS_NM_RSStoRMS_PTCANFD";
BA_ "CompuMethodName" SG_ 1249 ESS_NM_NOStoRMS_PTCANFD "ESS_NM_NOStoRMS_PTCANFD";
BA_ "ISignalName" SG_ 1249 ESS_NM_NOStoRMS_PTCANFD "IESS_NM_NOStoRMS_PTCANFD";
BA_ "LongName" SG_ 1249 ESS_NM_NOStoRMS_PTCANFD "ESS_NM_NOStoRMS_PTCANFD";
BA_ "SysSignalName" SG_ 1249 ESS_NM_NOStoRMS_PTCANFD "ESS_NM_NOStoRMS_PTCANFD";
BA_ "CompuMethodName" SG_ 1249 ESS_NM_NOSSta_PTCANFD "ESS_NM_NOSSta_PTCANFD";
BA_ "ISignalName" SG_ 1249 ESS_NM_NOSSta_PTCANFD "IESS_NM_NOSSta_PTCANFD";
BA_ "LongName" SG_ 1249 ESS_NM_NOSSta_PTCANFD "ESS_NM_NOSSta_PTCANFD";
BA_ "SysSignalName" SG_ 1249 ESS_NM_NOSSta_PTCANFD "ESS_NM_NOSSta_PTCANFD";
BA_ "CompuMethodName" SG_ 1249 ESS_NM_RMSSta_PTCANFD "ESS_NM_RMSSta_PTCANFD";
BA_ "ISignalName" SG_ 1249 ESS_NM_RMSSta_PTCANFD "IESS_NM_RMSSta_PTCANFD";
BA_ "LongName" SG_ 1249 ESS_NM_RMSSta_PTCANFD "ESS_NM_RMSSta_PTCANFD";
BA_ "SysSignalName" SG_ 1249 ESS_NM_RMSSta_PTCANFD "ESS_NM_RMSSta_PTCANFD";
BA_ "CompuMethodName" SG_ 1249 ESS_NWI_PTCANFD "ESS_NWI_PTCANFD";
BA_ "ISignalName" SG_ 1249 ESS_NWI_PTCANFD "IESS_NWI_PTCANFD";
BA_ "LongName" SG_ 1249 ESS_NWI_PTCANFD "ESS PTCANFD Network_Wakeup_Indication";
BA_ "SysSignalName" SG_ 1249 ESS_NWI_PTCANFD "ESS_NWI_PTCANFD";
BA_ "CompuMethodName" SG_ 1249 ESS_NOI_PTCANFD "ESS_NOI_PTCANFD";
BA_ "ISignalName" SG_ 1249 ESS_NOI_PTCANFD "IESS_NOI_PTCANFD";
BA_ "LongName" SG_ 1249 ESS_NOI_PTCANFD "ESS PTCANFD Network Operation Indication";
BA_ "SysSignalName" SG_ 1249 ESS_NOI_PTCANFD "ESS_NOI_PTCANFD";
BA_ "CompuMethodName" SG_ 1249 ESS_NKI_PTCANFD "ESS_NKI_PTCANFD";
BA_ "ISignalName" SG_ 1249 ESS_NKI_PTCANFD "IESS_NKI_PTCANFD";
BA_ "LongName" SG_ 1249 ESS_NKI_PTCANFD "ESS PTCANFD Network Keep Indication";
BA_ "SysSignalName" SG_ 1249 ESS_NKI_PTCANFD "ESS_NKI_PTCANFD";
BA_ "CompuMethodName" SG_ 307 FVCM_20ms_Group02_CRC "FVCM_20ms_Group02_CRC";
BA_ "ISignalName" SG_ 307 FVCM_20ms_Group02_CRC "IFVCM_20ms_Group02_CRC";
BA_ "SysSignalName" SG_ 307 FVCM_20ms_Group02_CRC "FVCM_20ms_Group02_CRC";
BA_ "CompuMethodName" SG_ 307 FVCM_20ms_Group02_RC "FVCM_20ms_Group02_RC";
BA_ "ISignalName" SG_ 307 FVCM_20ms_Group02_RC "IFVCM_20ms_Group02_RC";
BA_ "SysSignalName" SG_ 307 FVCM_20ms_Group02_RC "FVCM_20ms_Group02_RC";
BA_ "CompuMethodName" SG_ 307 FVCM_20ms_Group02_Reserved1 "FVCM_20ms_Group02_Reserved1";
BA_ "GenSigStartValue" SG_ 307 FVCM_20ms_Group02_Reserved1 15;
BA_ "ISignalName" SG_ 307 FVCM_20ms_Group02_Reserved1 "IFVCM_20ms_Group02_Reserved1";
BA_ "SysSignalName" SG_ 307 FVCM_20ms_Group02_Reserved1 "FVCM_20ms_Group02_Reserved1";
BA_ "CompuMethodName" SG_ 307 ACCTotWhlToqReqVal "ACCTotWhlToqReqVal";
BA_ "GenSigStartValue" SG_ 307 ACCTotWhlToqReqVal 30000;
BA_ "ISignalName" SG_ 307 ACCTotWhlToqReqVal "IACCTotWhlToqReqVal";
BA_ "LongName" SG_ 307 ACCTotWhlToqReqVal "Adaptive Cruise Control Total Wheel Torque Request Value";
BA_ "SysSignalName" SG_ 307 ACCTotWhlToqReqVal "ACCTotWhlToqReqVal";
BA_ "CompuMethodName" SG_ 307 ACCDrvrSelTrgtSpd "ACCDrvrSelTrgtSpd";
BA_ "ISignalName" SG_ 307 ACCDrvrSelTrgtSpd "IACCDrvrSelTrgtSpd";
BA_ "LongName" SG_ 307 ACCDrvrSelTrgtSpd "Adaptive_Cruise_Control_Driver_Select_Target_Speed";
BA_ "SysSignalName" SG_ 307 ACCDrvrSelTrgtSpd "ACCDrvrSelTrgtSpd";
BA_ "CompuMethodName" SG_ 307 ACCGoNotfr "ACCGoNotfr";
BA_ "ISignalName" SG_ 307 ACCGoNotfr "IACCGoNotfr";
BA_ "LongName" SG_ 307 ACCGoNotfr "Adaptive_Cruise_Control_Go_Notifier";
BA_ "SysSignalName" SG_ 307 ACCGoNotfr "ACCGoNotfr";
BA_ "CompuMethodName" SG_ 307 FVCM_20ms_Group02_Reserved2 "FVCM_20ms_Group02_Reserved2";
BA_ "GenSigStartValue" SG_ 307 FVCM_20ms_Group02_Reserved2 1;
BA_ "ISignalName" SG_ 307 FVCM_20ms_Group02_Reserved2 "IFVCM_20ms_Group02_Reserved2";
BA_ "SysSignalName" SG_ 307 FVCM_20ms_Group02_Reserved2 "FVCM_20ms_Group02_Reserved2";
BA_ "CompuMethodName" SG_ 307 ACCDetObjDistLvl "ACCDetObjDistLvl";
BA_ "ISignalName" SG_ 307 ACCDetObjDistLvl "IACCDetObjDistLvl";
BA_ "LongName" SG_ 307 ACCDetObjDistLvl "Adaptive Cruise Control Detected Object Distance Level";
BA_ "SysSignalName" SG_ 307 ACCDetObjDistLvl "ACCDetObjDistLvl";
BA_ "CompuMethodName" SG_ 307 ELKSysSts_IPD "ELKSysSts_IPD";
BA_ "ISignalName" SG_ 307 ELKSysSts_IPD "IELKSysSts_IPD";
BA_ "LongName" SG_ 307 ELKSysSts_IPD "ELK System status";
BA_ "SysSignalName" SG_ 307 ELKSysSts_IPD "ELKSysSts_IPD";
BA_ "CompuMethodName" SG_ 307 ACCTotWhlToqReqSts "ACCTotWhlToqReqSts";
BA_ "ISignalName" SG_ 307 ACCTotWhlToqReqSts "IACCTotWhlToqReqSts";
BA_ "LongName" SG_ 307 ACCTotWhlToqReqSts "Adaptive Cruise Control Total Wheel Torque Request Status";
BA_ "SysSignalName" SG_ 307 ACCTotWhlToqReqSts "ACCTotWhlToqReqSts";
BA_ "CompuMethodName" SG_ 307 ACCTJAMdSwDspCmd "ACCTJAMdSwDspCmd";
BA_ "ISignalName" SG_ 307 ACCTJAMdSwDspCmd "IACCTJAMdSwDspCmd";
BA_ "LongName" SG_ 307 ACCTJAMdSwDspCmd "Adaptive_Cruise_Control_Traffic_Jam_Assist_Mode_Switch_Display_Command";
BA_ "SysSignalName" SG_ 307 ACCTJAMdSwDspCmd "ACCTJAMdSwDspCmd";
BA_ "CompuMethodName" SG_ 307 ACCSeldTrgtDistLvl "ACCSeldTrgtDistLvl";
BA_ "GenSigStartValue" SG_ 307 ACCSeldTrgtDistLvl 3;
BA_ "ISignalName" SG_ 307 ACCSeldTrgtDistLvl "IACCSeldTrgtDistLvl";
BA_ "LongName" SG_ 307 ACCSeldTrgtDistLvl "Adaptive_Cruise_Control_Selected_Target_Distance_Level";
BA_ "SysSignalName" SG_ 307 ACCSeldTrgtDistLvl "ACCSeldTrgtDistLvl";
BA_ "CompuMethodName" SG_ 307 FVCM_20ms_Group02_Reserved3 "FVCM_20ms_Group02_Reserved3";
BA_ "GenSigStartValue" SG_ 307 FVCM_20ms_Group02_Reserved3 255;
BA_ "ISignalName" SG_ 307 FVCM_20ms_Group02_Reserved3 "IFVCM_20ms_Group02_Reserved3";
BA_ "SysSignalName" SG_ 307 FVCM_20ms_Group02_Reserved3 "FVCM_20ms_Group02_Reserved3";
BA_ "CompuMethodName" SG_ 307 HandOffStrgWhlDetnSta "HandOffStrgWhlDetnSta";
BA_ "ISignalName" SG_ 307 HandOffStrgWhlDetnSta "IHandOffStrgWhlDetnSta";
BA_ "LongName" SG_ 307 HandOffStrgWhlDetnSta "Hand_Off_Steering_Wheel_Detection_State";
BA_ "SysSignalName" SG_ 307 HandOffStrgWhlDetnSta "HandOffStrgWhlDetnSta";
BA_ "CompuMethodName" SG_ 307 ILCActvnDircnDspCmd "ILCActvnDircnDspCmd";
BA_ "ISignalName" SG_ 307 ILCActvnDircnDspCmd "IILCActvnDircnDspCmd";
BA_ "LongName" SG_ 307 ILCActvnDircnDspCmd "Intelligent_Lateral_Control_Activation_Direction_Display_Command";
BA_ "SysSignalName" SG_ 307 ILCActvnDircnDspCmd "ILCActvnDircnDspCmd";
BA_ "CompuMethodName" SG_ 307 FVCM_20ms_Group02_Reserved4 "FVCM_20ms_Group02_Reserved4";
BA_ "GenSigStartValue" SG_ 307 FVCM_20ms_Group02_Reserved4 7;
BA_ "ISignalName" SG_ 307 FVCM_20ms_Group02_Reserved4 "IFVCM_20ms_Group02_Reserved4";
BA_ "SysSignalName" SG_ 307 FVCM_20ms_Group02_Reserved4 "FVCM_20ms_Group02_Reserved4";
BA_ "CompuMethodName" SG_ 307 ILCSwDspCmd "ILCSwDspCmd";
BA_ "ISignalName" SG_ 307 ILCSwDspCmd "IILCSwDspCmd";
BA_ "LongName" SG_ 307 ILCSwDspCmd "Intelligent_Lateral_Control_Switch_Display_Command";
BA_ "SysSignalName" SG_ 307 ILCSwDspCmd "ILCSwDspCmd";
BA_ "CompuMethodName" SG_ 307 ILCSysSts "ILCSysSts";
BA_ "ISignalName" SG_ 307 ILCSysSts "IILCSysSts";
BA_ "LongName" SG_ 307 ILCSysSts "Intelligent_Lateral_Control_System_Status";
BA_ "SysSignalName" SG_ 307 ILCSysSts "ILCSysSts";
BA_ "CompuMethodName" SG_ 307 ILCActvnVelDspCmd "ILCActvnVelDspCmd";
BA_ "ISignalName" SG_ 307 ILCActvnVelDspCmd "IILCActvnVelDspCmd";
BA_ "LongName" SG_ 307 ILCActvnVelDspCmd "Intelligent_Longitudinal_Control_Activation_Velocity_Display_Command";
BA_ "SysSignalName" SG_ 307 ILCActvnVelDspCmd "ILCActvnVelDspCmd";
BA_ "CompuMethodName" SG_ 307 HandOffStrgWhlDetnStaV "HandOffStrgWhlDetnStaV";
BA_ "ISignalName" SG_ 307 HandOffStrgWhlDetnStaV "IHandOffStrgWhlDetnStaV";
BA_ "LongName" SG_ 307 HandOffStrgWhlDetnStaV "Hand Off Steering Wheel Detection State Validity";
BA_ "SysSignalName" SG_ 307 HandOffStrgWhlDetnStaV "HandOffStrgWhlDetnStaV";
BA_ "CompuMethodName" SG_ 307 LDWLKAAudReq "LDWLKAAudReq";
BA_ "ISignalName" SG_ 307 LDWLKAAudReq "ILDWLKAAudReq";
BA_ "LongName" SG_ 307 LDWLKAAudReq "Lane_Departure_Warning_Lane_Keeping_Assist_Audible_Request";
BA_ "SysSignalName" SG_ 307 LDWLKAAudReq "LDWLKAAudReq";
BA_ "CompuMethodName" SG_ 307 LDWAdoWrnngDspCmd "LDWAdoWrnngDspCmd";
BA_ "ISignalName" SG_ 307 LDWAdoWrnngDspCmd "ILDWAdoWrnngDspCmd";
BA_ "LongName" SG_ 307 LDWAdoWrnngDspCmd "Lane_Departure_Warning_Audio_Warning_Display_Command";
BA_ "SysSignalName" SG_ 307 LDWAdoWrnngDspCmd "LDWAdoWrnngDspCmd";
BA_ "CompuMethodName" SG_ 307 LDWLKADspCmd "LDWLKADspCmd";
BA_ "ISignalName" SG_ 307 LDWLKADspCmd "ILDWLKADspCmd";
BA_ "LongName" SG_ 307 LDWLKADspCmd "Lane_Departure_Warning_Lane_Keeping_Assist_Display_Command";
BA_ "SysSignalName" SG_ 307 LDWLKADspCmd "LDWLKADspCmd";
BA_ "CompuMethodName" SG_ 307 FVCM_20ms_Group02_Reserved5 "FVCM_20ms_Group02_Reserved5";
BA_ "GenSigStartValue" SG_ 307 FVCM_20ms_Group02_Reserved5 7;
BA_ "ISignalName" SG_ 307 FVCM_20ms_Group02_Reserved5 "IFVCM_20ms_Group02_Reserved5";
BA_ "SysSignalName" SG_ 307 FVCM_20ms_Group02_Reserved5 "FVCM_20ms_Group02_Reserved5";
BA_ "CompuMethodName" SG_ 307 LKADrvrTkovReq "LKADrvrTkovReq";
BA_ "ISignalName" SG_ 307 LKADrvrTkovReq "ILKADrvrTkovReq";
BA_ "LongName" SG_ 307 LKADrvrTkovReq "Lane_Keeping_Assist_Driver_Takeover_Request";
BA_ "SysSignalName" SG_ 307 LKADrvrTkovReq "LKADrvrTkovReq";
BA_ "CompuMethodName" SG_ 307 LDWSnstvtLvl "LDWSnstvtLvl";
BA_ "ISignalName" SG_ 307 LDWSnstvtLvl "ILDWSnstvtLvl";
BA_ "LongName" SG_ 307 LDWSnstvtLvl "Lane_Departure_Warning_Sensitivity_Level";
BA_ "SysSignalName" SG_ 307 LDWSnstvtLvl "LDWSnstvtLvl";
BA_ "CompuMethodName" SG_ 307 LDWLKAHptWrnngDspCmd "LDWLKAHptWrnngDspCmd";
BA_ "ISignalName" SG_ 307 LDWLKAHptWrnngDspCmd "ILDWLKAHptWrnngDspCmd";
BA_ "LongName" SG_ 307 LDWLKAHptWrnngDspCmd "Lane_Departure_Warning_Lane_Keeping_Assist_Haptic_Warning_Display_Command";
BA_ "SysSignalName" SG_ 307 LDWLKAHptWrnngDspCmd "LDWLKAHptWrnngDspCmd";
BA_ "CompuMethodName" SG_ 307 EyeOffRoadDetnSta "EyeOffRoadDetnSta";
BA_ "ISignalName" SG_ 307 EyeOffRoadDetnSta "IEyeOffRoadDetnSta";
BA_ "LongName" SG_ 307 EyeOffRoadDetnSta "Eye_Off_Road_Detection_State";
BA_ "SysSignalName" SG_ 307 EyeOffRoadDetnSta "EyeOffRoadDetnSta";
BA_ "CompuMethodName" SG_ 307 FVCM_20ms_Group02_Reserved6 "FVCM_20ms_Group02_Reserved6";
BA_ "GenSigStartValue" SG_ 307 FVCM_20ms_Group02_Reserved6 63;
BA_ "ISignalName" SG_ 307 FVCM_20ms_Group02_Reserved6 "IFVCM_20ms_Group02_Reserved6";
BA_ "SysSignalName" SG_ 307 FVCM_20ms_Group02_Reserved6 "FVCM_20ms_Group02_Reserved6";
BA_ "CompuMethodName" SG_ 307 FVCM_20ms_Group02_Reserved7 "FVCM_20ms_Group02_Reserved7";
BA_ "GenSigStartValue" SG_ 307 FVCM_20ms_Group02_Reserved7 3;
BA_ "ISignalName" SG_ 307 FVCM_20ms_Group02_Reserved7 "IFVCM_20ms_Group02_Reserved7";
BA_ "SysSignalName" SG_ 307 FVCM_20ms_Group02_Reserved7 "FVCM_20ms_Group02_Reserved7";
BA_ "CompuMethodName" SG_ 307 EyeOffRoadDetnStaV "EyeOffRoadDetnStaV";
BA_ "ISignalName" SG_ 307 EyeOffRoadDetnStaV "IEyeOffRoadDetnStaV";
BA_ "LongName" SG_ 307 EyeOffRoadDetnStaV "Eye_Off_Road_Detection_State_Validity";
BA_ "SysSignalName" SG_ 307 EyeOffRoadDetnStaV "EyeOffRoadDetnStaV";
BA_ "CompuMethodName" SG_ 307 ACCMsgReq "ACCMsgReq";
BA_ "ISignalName" SG_ 307 ACCMsgReq "IACCMsgReq";
BA_ "LongName" SG_ 307 ACCMsgReq "Adaptive_Cruise_Control_Message_Request";
BA_ "SysSignalName" SG_ 307 ACCMsgReq "ACCMsgReq";
BA_ "CompuMethodName" SG_ 307 FVCM_20ms_Group02_Reserved8 "FVCM_20ms_Group02_Reserved8";
BA_ "GenSigStartValue" SG_ 307 FVCM_20ms_Group02_Reserved8 255;
BA_ "ISignalName" SG_ 307 FVCM_20ms_Group02_Reserved8 "IFVCM_20ms_Group02_Reserved8";
BA_ "SysSignalName" SG_ 307 FVCM_20ms_Group02_Reserved8 "FVCM_20ms_Group02_Reserved8";
BA_ "CompuMethodName" SG_ 382 ICBAD_20ms_Group07_CRC "ICBAD_20ms_Group07_CRC";
BA_ "ISignalName" SG_ 382 ICBAD_20ms_Group07_CRC "IICBAD_20ms_Group07_CRC";
BA_ "LongName" SG_ 382 ICBAD_20ms_Group07_CRC "ICBAD_20ms_Group07_CRC";
BA_ "SysSignalName" SG_ 382 ICBAD_20ms_Group07_CRC "ICBAD_20ms_Group07_CRC";
BA_ "CompuMethodName" SG_ 382 ICBAD_20ms_Group07_RC "ICBAD_20ms_Group07_RC";
BA_ "ISignalName" SG_ 382 ICBAD_20ms_Group07_RC "IICBAD_20ms_Group07_RC";
BA_ "LongName" SG_ 382 ICBAD_20ms_Group07_RC "ICBAD_20ms_Group07_RC";
BA_ "SysSignalName" SG_ 382 ICBAD_20ms_Group07_RC "ICBAD_20ms_Group07_RC";
BA_ "CompuMethodName" SG_ 382 ACCSdslReq "ACCSdslReq";
BA_ "ISignalName" SG_ 382 ACCSdslReq "IACCSdslReq";
BA_ "LongName" SG_ 382 ACCSdslReq "Adaptive Cruise Control Standstill Request";
BA_ "SysSignalName" SG_ 382 ACCSdslReq "ACCSdslReq";
BA_ "CompuMethodName" SG_ 382 ACCGoReq "ACCGoReq";
BA_ "ISignalName" SG_ 382 ACCGoReq "IACCGoReq";
BA_ "LongName" SG_ 382 ACCGoReq "Adaptive Cruise Control Go Request";
BA_ "SysSignalName" SG_ 382 ACCGoReq "ACCGoReq";
BA_ "CompuMethodName" SG_ 382 ACCAccReqSts_CH "ACCAccReqSts_CH";
BA_ "ISignalName" SG_ 382 ACCAccReqSts_CH "IACCAccReqSts_CH";
BA_ "LongName" SG_ 382 ACCAccReqSts_CH "Adaptive Cruise Control Acceleration Request Status";
BA_ "SysSignalName" SG_ 382 ACCAccReqSts_CH "ACCAccReqSts_CH";
BA_ "CompuMethodName" SG_ 382 ACCAccReqVal "ACCAccReqVal";
BA_ "GenSigStartValue" SG_ 382 ACCAccReqVal 1444;
BA_ "ISignalName" SG_ 382 ACCAccReqVal "IACCAccReqVal";
BA_ "LongName" SG_ 382 ACCAccReqVal "Adaptive Cruise Control Acceleration Request Value";
BA_ "SysSignalName" SG_ 382 ACCAccReqVal "ACCAccReqVal";
BA_ "CompuMethodName" SG_ 382 APAEPBOPReq "APAEPBOPReq";
BA_ "ISignalName" SG_ 382 APAEPBOPReq "IAPAEPBOPReq";
BA_ "LongName" SG_ 382 APAEPBOPReq "Advanced Park Assist Electric Park Brake Operation Request";
BA_ "SysSignalName" SG_ 382 APAEPBOPReq "APAEPBOPReq";
BA_ "CompuMethodName" SG_ 382 ACCSysFltSts "ACCSysFltSts";
BA_ "ISignalName" SG_ 382 ACCSysFltSts "IACCSysFltSts";
BA_ "LongName" SG_ 382 ACCSysFltSts "Adaptive Cruise Control System Fault Status";
BA_ "SysSignalName" SG_ 382 ACCSysFltSts "ACCSysFltSts";
BA_ "CompuMethodName" SG_ 382 AIPkgAPASCSAcclReqVal "AIPkgAPASCSAcclReqVal";
BA_ "ISignalName" SG_ 382 AIPkgAPASCSAcclReqVal "IAIPkgAPASCSAcclReqVal";
BA_ "LongName" SG_ 382 AIPkgAPASCSAcclReqVal "Ai Parking APA Acceleration Request Value";
BA_ "SysSignalName" SG_ 382 AIPkgAPASCSAcclReqVal "AIPkgAPASCSAcclReqVal";
BA_ "CompuMethodName" SG_ 382 ACCSysSts "ACCSysSts";
BA_ "ISignalName" SG_ 382 ACCSysSts "IACCSysSts";
BA_ "LongName" SG_ 382 ACCSysSts "Adaptive Cruise Control System Status";
BA_ "SysSignalName" SG_ 382 ACCSysSts "ACCSysSts";
BA_ "CompuMethodName" SG_ 382 APASCSAcclReqSts "APASCSAcclReqSts";
BA_ "ISignalName" SG_ 382 APASCSAcclReqSts "IAPASCSAcclReqSts";
BA_ "LongName" SG_ 382 APASCSAcclReqSts "Advanced Park Assist Stability Control System Acceleration Request Status";
BA_ "SysSignalName" SG_ 382 APASCSAcclReqSts "APASCSAcclReqSts";
BA_ "CompuMethodName" SG_ 382 APAEPBOPReqV "APAEPBOPReqV";
BA_ "ISignalName" SG_ 382 APAEPBOPReqV "IAPAEPBOPReqV";
BA_ "LongName" SG_ 382 APAEPBOPReqV "Advanced Park Assist Electric Park Brake Operation Request Validity";
BA_ "SysSignalName" SG_ 382 APAEPBOPReqV "APAEPBOPReqV";
BA_ "CompuMethodName" SG_ 382 AutodDrvngSysSCSSdslReqV "AutodDrvngSysSCSSdslReqV";
BA_ "ISignalName" SG_ 382 AutodDrvngSysSCSSdslReqV "IAutodDrvngSysSCSSdslReqV";
BA_ "LongName" SG_ 382 AutodDrvngSysSCSSdslReqV "Automated Driving System Stability Control System Standstill Request Validity";
BA_ "SysSignalName" SG_ 382 AutodDrvngSysSCSSdslReqV "AutodDrvngSysSCSSdslReqV";
BA_ "CompuMethodName" SG_ 382 AutodDrvngSysSCSSdslReq "AutodDrvngSysSCSSdslReq";
BA_ "ISignalName" SG_ 382 AutodDrvngSysSCSSdslReq "IAutodDrvngSysSCSSdslReq";
BA_ "LongName" SG_ 382 AutodDrvngSysSCSSdslReq "Automated Driving System Stability Control System Standstill Request";
BA_ "SysSignalName" SG_ 382 AutodDrvngSysSCSSdslReq "AutodDrvngSysSCSSdslReq";
BA_ "CompuMethodName" SG_ 382 AutodDrvngSysEmgcBrkReqV "AutodDrvngSysEmgcBrkReqV";
BA_ "ISignalName" SG_ 382 AutodDrvngSysEmgcBrkReqV "IAutodDrvngSysEmgcBrkReqV";
BA_ "LongName" SG_ 382 AutodDrvngSysEmgcBrkReqV "Automated_Driving_System_Emergency_Brake_Request_Validity";
BA_ "SysSignalName" SG_ 382 AutodDrvngSysEmgcBrkReqV "AutodDrvngSysEmgcBrkReqV";
BA_ "CompuMethodName" SG_ 382 AutodDrvngSysEmgcBrkReq "AutodDrvngSysEmgcBrkReq";
BA_ "ISignalName" SG_ 382 AutodDrvngSysEmgcBrkReq "IAutodDrvngSysEmgcBrkReq";
BA_ "LongName" SG_ 382 AutodDrvngSysEmgcBrkReq "Automated_Driving_System_Emergency_Brake_Request";
BA_ "SysSignalName" SG_ 382 AutodDrvngSysEmgcBrkReq "AutodDrvngSysEmgcBrkReq";
BA_ "CompuMethodName" SG_ 382 ICBAD_20ms_Group07_Reserved1 "ICBAD_20ms_Group07_Reserved1";
BA_ "GenSigStartValue" SG_ 382 ICBAD_20ms_Group07_Reserved1 15;
BA_ "ISignalName" SG_ 382 ICBAD_20ms_Group07_Reserved1 "IICBAD_20ms_Group07_Reserved1";
BA_ "SysSignalName" SG_ 382 ICBAD_20ms_Group07_Reserved1 "ICBAD_20ms_Group07_Reserved1";
BA_ "CompuMethodName" SG_ 382 AutodDrvngSysSCSDrvOffReqV "AutodDrvngSysSCSDrvOffReqV";
BA_ "ISignalName" SG_ 382 AutodDrvngSysSCSDrvOffReqV "IAutodDrvngSysSCSDrvOffReqV";
BA_ "LongName" SG_ 382 AutodDrvngSysSCSDrvOffReqV "Automated Driving System Stability Control System Drive Off Request Validity";
BA_ "SysSignalName" SG_ 382 AutodDrvngSysSCSDrvOffReqV "AutodDrvngSysSCSDrvOffReqV";
BA_ "CompuMethodName" SG_ 382 AutodDrvngSysSCSDrvOffReq "AutodDrvngSysSCSDrvOffReq";
BA_ "ISignalName" SG_ 382 AutodDrvngSysSCSDrvOffReq "IAutodDrvngSysSCSDrvOffReq";
BA_ "LongName" SG_ 382 AutodDrvngSysSCSDrvOffReq "Automated Driving System Stability Control System Drive Off Request";
BA_ "SysSignalName" SG_ 382 AutodDrvngSysSCSDrvOffReq "AutodDrvngSysSCSDrvOffReq";
BA_ "CompuMethodName" SG_ 382 AutodDrvngSysMdReqV "AutodDrvngSysMdReqV";
BA_ "ISignalName" SG_ 382 AutodDrvngSysMdReqV "IAutodDrvngSysMdReqV";
BA_ "LongName" SG_ 382 AutodDrvngSysMdReqV "Automated Driving System Mode Request Validity";
BA_ "SysSignalName" SG_ 382 AutodDrvngSysMdReqV "AutodDrvngSysMdReqV";
BA_ "CompuMethodName" SG_ 382 AutodDrvngSysMdReq "AutodDrvngSysMdReq";
BA_ "ISignalName" SG_ 382 AutodDrvngSysMdReq "IAutodDrvngSysMdReq";
BA_ "LongName" SG_ 382 AutodDrvngSysMdReq "Automated Driving System Mode Request";
BA_ "SysSignalName" SG_ 382 AutodDrvngSysMdReq "AutodDrvngSysMdReq";
BA_ "CompuMethodName" SG_ 382 AutodDrvngSysFlrStsV "AutodDrvngSysFlrStsV";
BA_ "ISignalName" SG_ 382 AutodDrvngSysFlrStsV "IAutodDrvngSysFlrStsV";
BA_ "LongName" SG_ 382 AutodDrvngSysFlrStsV "Automated Driving System Failure Status Validity";
BA_ "SysSignalName" SG_ 382 AutodDrvngSysFlrStsV "AutodDrvngSysFlrStsV";
BA_ "CompuMethodName" SG_ 382 AutodDrvngSysFlrSts "AutodDrvngSysFlrSts";
BA_ "ISignalName" SG_ 382 AutodDrvngSysFlrSts "IAutodDrvngSysFlrSts";
BA_ "LongName" SG_ 382 AutodDrvngSysFlrSts "Automated Driving System Failure Status";
BA_ "SysSignalName" SG_ 382 AutodDrvngSysFlrSts "AutodDrvngSysFlrSts";
BA_ "CompuMethodName" SG_ 343 ICBAD_20ms_Group46_CRC "ICBAD_20ms_Group46_CRC";
BA_ "ISignalName" SG_ 343 ICBAD_20ms_Group46_CRC "IICBAD_20ms_Group46_CRC";
BA_ "LongName" SG_ 343 ICBAD_20ms_Group46_CRC "ICBAD_20ms_Group46_CRC";
BA_ "SysSignalName" SG_ 343 ICBAD_20ms_Group46_CRC "ICBAD_20ms_Group46_CRC";
BA_ "CompuMethodName" SG_ 343 ICBAD_20ms_Group46_RC "ICBAD_20ms_Group46_RC";
BA_ "ISignalName" SG_ 343 ICBAD_20ms_Group46_RC "IICBAD_20ms_Group46_RC";
BA_ "LongName" SG_ 343 ICBAD_20ms_Group46_RC "ICBAD_20ms_Group46_RC";
BA_ "SysSignalName" SG_ 343 ICBAD_20ms_Group46_RC "ICBAD_20ms_Group46_RC";
BA_ "CompuMethodName" SG_ 343 AEBPrflReq "AEBPrflReq";
BA_ "ISignalName" SG_ 343 AEBPrflReq "IAEBPrflReq";
BA_ "LongName" SG_ 343 AEBPrflReq "Autonomous Emergency Braking Prefill Request";
BA_ "SysSignalName" SG_ 343 AEBPrflReq "AEBPrflReq";
BA_ "CompuMethodName" SG_ 343 AEBSysSts "AEBSysSts";
BA_ "GenSigStartValue" SG_ 343 AEBSysSts 1;
BA_ "ISignalName" SG_ 343 AEBSysSts "IAEBSysSts";
BA_ "LongName" SG_ 343 AEBSysSts "Autonomous Emergency Braking System Status";
BA_ "SysSignalName" SG_ 343 AEBSysSts "AEBSysSts";
BA_ "CompuMethodName" SG_ 343 AEBDclReqSts "AEBDclReqSts";
BA_ "ISignalName" SG_ 343 AEBDclReqSts "IAEBDclReqSts";
BA_ "LongName" SG_ 343 AEBDclReqSts "Autonomous Emergency Braking Deceleration Request Status";
BA_ "SysSignalName" SG_ 343 AEBDclReqSts "AEBDclReqSts";
BA_ "CompuMethodName" SG_ 343 AEBBrkJerkLvlReq "AEBBrkJerkLvlReq";
BA_ "ISignalName" SG_ 343 AEBBrkJerkLvlReq "IAEBBrkJerkLvlReq";
BA_ "LongName" SG_ 343 AEBBrkJerkLvlReq "Autonomous Emergency Braking Brake Jerk Level Request";
BA_ "SysSignalName" SG_ 343 AEBBrkJerkLvlReq "AEBBrkJerkLvlReq";
BA_ "CompuMethodName" SG_ 343 AEBHydBrkAstLvlReq "AEBHydBrkAstLvlReq";
BA_ "ISignalName" SG_ 343 AEBHydBrkAstLvlReq "IAEBHydBrkAstLvlReq";
BA_ "LongName" SG_ 343 AEBHydBrkAstLvlReq "Autonomous Emergency Braking Hydraulic Brake Assist Level Request";
BA_ "SysSignalName" SG_ 343 AEBHydBrkAstLvlReq "AEBHydBrkAstLvlReq";
BA_ "CompuMethodName" SG_ 343 AEBDclReqVal "AEBDclReqVal";
BA_ "GenSigStartValue" SG_ 343 AEBDclReqVal 127;
BA_ "ISignalName" SG_ 343 AEBDclReqVal "IAEBDclReqVal";
BA_ "LongName" SG_ 343 AEBDclReqVal "Autonomous Emergency Braking Deceleration Request Value";
BA_ "SysSignalName" SG_ 343 AEBDclReqVal "AEBDclReqVal";
BA_ "CompuMethodName" SG_ 343 ICBAD_20ms_Group46_Reserved1 "ICBAD_20ms_Group46_Reserved1";
BA_ "GenSigStartValue" SG_ 343 ICBAD_20ms_Group46_Reserved1 31;
BA_ "ISignalName" SG_ 343 ICBAD_20ms_Group46_Reserved1 "IICBAD_20ms_Group46_Reserved1";
BA_ "SysSignalName" SG_ 343 ICBAD_20ms_Group46_Reserved1 "ICBAD_20ms_Group46_Reserved1";
BA_ "CompuMethodName" SG_ 343 AEBSysFltSts "AEBSysFltSts";
BA_ "ISignalName" SG_ 343 AEBSysFltSts "IAEBSysFltSts";
BA_ "LongName" SG_ 343 AEBSysFltSts "Autonomous Emergency Braking System Fault Status";
BA_ "SysSignalName" SG_ 343 AEBSysFltSts "AEBSysFltSts";
BA_ "CompuMethodName" SG_ 343 ICBAD_20ms_Group46_Reserved2 "ICBAD_20ms_Group46_Reserved2";
BA_ "GenSigStartValue" SG_ 343 ICBAD_20ms_Group46_Reserved2 255;
BA_ "ISignalName" SG_ 343 ICBAD_20ms_Group46_Reserved2 "IICBAD_20ms_Group46_Reserved2";
BA_ "SysSignalName" SG_ 343 ICBAD_20ms_Group46_Reserved2 "ICBAD_20ms_Group46_Reserved2";
BA_ "CompuMethodName" SG_ 343 AEBDclReqToqVal "AEBDclReqToqVal";
BA_ "ISignalName" SG_ 343 AEBDclReqToqVal "IAEBDclReqToqVal";
BA_ "LongName" SG_ 343 AEBDclReqToqVal "Autonomous Emergency Braking Deceleration Request Torque Value";
BA_ "SysSignalName" SG_ 343 AEBDclReqToqVal "AEBDclReqToqVal";
BA_ "CompuMethodName" SG_ 360 ICBAD_20ms_Group13_CRC "ICBAD_20ms_Group13_CRC";
BA_ "ISignalName" SG_ 360 ICBAD_20ms_Group13_CRC "IICBAD_20ms_Group13_CRC";
BA_ "LongName" SG_ 360 ICBAD_20ms_Group13_CRC "ICBAD_20ms_Group13_CRC";
BA_ "SysSignalName" SG_ 360 ICBAD_20ms_Group13_CRC "ICBAD_20ms_Group13_CRC";
BA_ "CompuMethodName" SG_ 360 ICBAD_20ms_Group13_RC "ICBAD_20ms_Group13_RC";
BA_ "ISignalName" SG_ 360 ICBAD_20ms_Group13_RC "IICBAD_20ms_Group13_RC";
BA_ "LongName" SG_ 360 ICBAD_20ms_Group13_RC "ICBAD_20ms_Group13_RC";
BA_ "SysSignalName" SG_ 360 ICBAD_20ms_Group13_RC "ICBAD_20ms_Group13_RC";
BA_ "CompuMethodName" SG_ 360 APAShifterPosReqd "APAShifterPosReqd";
BA_ "ISignalName" SG_ 360 APAShifterPosReqd "IAPAShifterPosReqd";
BA_ "LongName" SG_ 360 APAShifterPosReqd "Advanced Park Assist Shifter Position Requested";
BA_ "SysSignalName" SG_ 360 APAShifterPosReqd "APAShifterPosReqd";
BA_ "CompuMethodName" SG_ 360 APATrgtEPSStrgWhlAng "APATrgtEPSStrgWhlAng";
BA_ "GenSigStartValue" SG_ 360 APATrgtEPSStrgWhlAng 32768;
BA_ "ISignalName" SG_ 360 APATrgtEPSStrgWhlAng "IAPATrgtEPSStrgWhlAng";
BA_ "LongName" SG_ 360 APATrgtEPSStrgWhlAng "Advanced Park Assist Target Electric Power Steering Steering Wheel Angle";
BA_ "SysSignalName" SG_ 360 APATrgtEPSStrgWhlAng "APATrgtEPSStrgWhlAng";
BA_ "CompuMethodName" SG_ 360 ICBAD_20ms_Group13_Reserved1 "ICBAD_20ms_Group13_Reserved1";
BA_ "GenSigStartValue" SG_ 360 ICBAD_20ms_Group13_Reserved1 255;
BA_ "ISignalName" SG_ 360 ICBAD_20ms_Group13_Reserved1 "IICBAD_20ms_Group13_Reserved1";
BA_ "SysSignalName" SG_ 360 ICBAD_20ms_Group13_Reserved1 "ICBAD_20ms_Group13_Reserved1";
BA_ "CompuMethodName" SG_ 360 APASCUReqSts "APASCUReqSts";
BA_ "ISignalName" SG_ 360 APASCUReqSts "IAPASCUReqSts";
BA_ "LongName" SG_ 360 APASCUReqSts "Advanced Park Assist Shifter Control Unit Request Status";
BA_ "SysSignalName" SG_ 360 APASCUReqSts "APASCUReqSts";
BA_ "CompuMethodName" SG_ 360 APACmdEPSSts "APACmdEPSSts";
BA_ "ISignalName" SG_ 360 APACmdEPSSts "IAPACmdEPSSts";
BA_ "LongName" SG_ 360 APACmdEPSSts "Advanced Park Assist Command Electric Power Steering Status";
BA_ "SysSignalName" SG_ 360 APACmdEPSSts "APACmdEPSSts";
BA_ "CompuMethodName" SG_ 360 ICBAD_20ms_Group13_Reserved2 "ICBAD_20ms_Group13_Reserved2";
BA_ "GenSigStartValue" SG_ 360 ICBAD_20ms_Group13_Reserved2 15;
BA_ "ISignalName" SG_ 360 ICBAD_20ms_Group13_Reserved2 "IICBAD_20ms_Group13_Reserved2";
BA_ "SysSignalName" SG_ 360 ICBAD_20ms_Group13_Reserved2 "ICBAD_20ms_Group13_Reserved2";
BA_ "CompuMethodName" SG_ 360 ICBAD_20ms_Group13_Reserved4 "ICBAD_20ms_Group13_Reserved4";
BA_ "GenSigStartValue" SG_ 360 ICBAD_20ms_Group13_Reserved4 15;
BA_ "ISignalName" SG_ 360 ICBAD_20ms_Group13_Reserved4 "IICBAD_20ms_Group13_Reserved4";
BA_ "SysSignalName" SG_ 360 ICBAD_20ms_Group13_Reserved4 "ICBAD_20ms_Group13_Reserved4";
BA_ "CompuMethodName" SG_ 360 APAShifterPosReqdV "APAShifterPosReqdV";
BA_ "ISignalName" SG_ 360 APAShifterPosReqdV "IAPAShifterPosReqdV";
BA_ "LongName" SG_ 360 APAShifterPosReqdV "Advanced Park Assist Shifter Position Requested Validity";
BA_ "SysSignalName" SG_ 360 APAShifterPosReqdV "APAShifterPosReqdV";
BA_ "CompuMethodName" SG_ 360 APASCUReqStsV "APASCUReqStsV";
BA_ "ISignalName" SG_ 360 APASCUReqStsV "IAPASCUReqStsV";
BA_ "LongName" SG_ 360 APASCUReqStsV "Advanced Park Assist Shifter Control Unit Request Status Validity";
BA_ "SysSignalName" SG_ 360 APASCUReqStsV "APASCUReqStsV";
BA_ "CompuMethodName" SG_ 360 APAF "APAF";
BA_ "ISignalName" SG_ 360 APAF "IAPAF";
BA_ "LongName" SG_ 360 APAF "Advanced Park Assist Failed";
BA_ "SysSignalName" SG_ 360 APAF "APAF";
BA_ "CompuMethodName" SG_ 360 ICBAD_20ms_Group13_Reserved3 "ICBAD_20ms_Group13_Reserved3";
BA_ "GenSigStartValue" SG_ 360 ICBAD_20ms_Group13_Reserved3 1;
BA_ "ISignalName" SG_ 360 ICBAD_20ms_Group13_Reserved3 "IICBAD_20ms_Group13_Reserved3";
BA_ "SysSignalName" SG_ 360 ICBAD_20ms_Group13_Reserved3 "ICBAD_20ms_Group13_Reserved3";
BA_ "CompuMethodName" SG_ 360 ICBAD_20ms_Group13_Reserved5 "ICBAD_20ms_Group13_Reserved5";
BA_ "GenSigStartValue" SG_ 360 ICBAD_20ms_Group13_Reserved5 255;
BA_ "ISignalName" SG_ 360 ICBAD_20ms_Group13_Reserved5 "IICBAD_20ms_Group13_Reserved5";
BA_ "SysSignalName" SG_ 360 ICBAD_20ms_Group13_Reserved5 "ICBAD_20ms_Group13_Reserved5";
BA_ "CompuMethodName" SG_ 351 ICBAD_20ms_Group05_CRC "ICBAD_20ms_Group05_CRC";
BA_ "ISignalName" SG_ 351 ICBAD_20ms_Group05_CRC "IICBAD_20ms_Group05_CRC";
BA_ "LongName" SG_ 351 ICBAD_20ms_Group05_CRC "ICBAD_20ms_Group05_CRC";
BA_ "SysSignalName" SG_ 351 ICBAD_20ms_Group05_CRC "ICBAD_20ms_Group05_CRC";
BA_ "CompuMethodName" SG_ 351 ICBAD_20ms_Group05_RC "ICBAD_20ms_Group05_RC";
BA_ "ISignalName" SG_ 351 ICBAD_20ms_Group05_RC "IICBAD_20ms_Group05_RC";
BA_ "LongName" SG_ 351 ICBAD_20ms_Group05_RC "ICBAD_20ms_Group05_RC";
BA_ "SysSignalName" SG_ 351 ICBAD_20ms_Group05_RC "ICBAD_20ms_Group05_RC";
BA_ "CompuMethodName" SG_ 351 ICBAD_20ms_Group05_Reserved1 "ICBAD_20ms_Group05_Reserved1";
BA_ "GenSigStartValue" SG_ 351 ICBAD_20ms_Group05_Reserved1 1;
BA_ "ISignalName" SG_ 351 ICBAD_20ms_Group05_Reserved1 "IICBAD_20ms_Group05_Reserved1";
BA_ "SysSignalName" SG_ 351 ICBAD_20ms_Group05_Reserved1 "ICBAD_20ms_Group05_Reserved1";
BA_ "CompuMethodName" SG_ 351 APAVCUReqSts "APAVCUReqSts";
BA_ "ISignalName" SG_ 351 APAVCUReqSts "IAPAVCUReqSts";
BA_ "LongName" SG_ 351 APAVCUReqSts "Apa Vcu Request Status";
BA_ "SysSignalName" SG_ 351 APAVCUReqSts "APAVCUReqSts";
BA_ "CompuMethodName" SG_ 351 ICBAD_20ms_Group05_Reserved2 "ICBAD_20ms_Group05_Reserved2";
BA_ "GenSigStartValue" SG_ 351 ICBAD_20ms_Group05_Reserved2 255;
BA_ "ISignalName" SG_ 351 ICBAD_20ms_Group05_Reserved2 "IICBAD_20ms_Group05_Reserved2";
BA_ "SysSignalName" SG_ 351 ICBAD_20ms_Group05_Reserved2 "ICBAD_20ms_Group05_Reserved2";
BA_ "CompuMethodName" SG_ 351 APAToqReqVal "APAToqReqVal";
BA_ "ISignalName" SG_ 351 APAToqReqVal "IAPAToqReqVal";
BA_ "LongName" SG_ 351 APAToqReqVal "Advanced Park Assist Torque Request Value";
BA_ "SysSignalName" SG_ 351 APAToqReqVal "APAToqReqVal";
BA_ "CompuMethodName" SG_ 351 APACrpSpdReqVal_IPD "APACrpSpdReqVal_IPD";
BA_ "ISignalName" SG_ 351 APACrpSpdReqVal_IPD "IAPACrpSpdReqVal_IPD";
BA_ "LongName" SG_ 351 APACrpSpdReqVal_IPD "Advanced Park Assist Creep Speed Request Value";
BA_ "SysSignalName" SG_ 351 APACrpSpdReqVal_IPD "APACrpSpdReqVal_IPD";
BA_ "CompuMethodName" SG_ 351 ICBAD_20ms_Group05_Reserved3 "ICBAD_20ms_Group05_Reserved3";
BA_ "GenSigStartValue" SG_ 351 ICBAD_20ms_Group05_Reserved3 1;
BA_ "ISignalName" SG_ 351 ICBAD_20ms_Group05_Reserved3 "IICBAD_20ms_Group05_Reserved3";
BA_ "SysSignalName" SG_ 351 ICBAD_20ms_Group05_Reserved3 "ICBAD_20ms_Group05_Reserved3";
BA_ "CompuMethodName" SG_ 351 APARevrDrgReq "APARevrDrgReq";
BA_ "ISignalName" SG_ 351 APARevrDrgReq "IAPARevrDrgReq";
BA_ "LongName" SG_ 351 APARevrDrgReq "Advanced Park Assist Reverse Drag Request";
BA_ "SysSignalName" SG_ 351 APARevrDrgReq "APARevrDrgReq";
BA_ "CompuMethodName" SG_ 351 ICBAD_20ms_Group05_Reserved4 "ICBAD_20ms_Group05_Reserved4";
BA_ "GenSigStartValue" SG_ 351 ICBAD_20ms_Group05_Reserved4 255;
BA_ "ISignalName" SG_ 351 ICBAD_20ms_Group05_Reserved4 "IICBAD_20ms_Group05_Reserved4";
BA_ "SysSignalName" SG_ 351 ICBAD_20ms_Group05_Reserved4 "ICBAD_20ms_Group05_Reserved4";
BA_ "CompuMethodName" SG_ 351 ICBAD_20ms_Group05_Reserved5 "ICBAD_20ms_Group05_Reserved5";
BA_ "GenSigStartValue" SG_ 351 ICBAD_20ms_Group05_Reserved5 255;
BA_ "ISignalName" SG_ 351 ICBAD_20ms_Group05_Reserved5 "IICBAD_20ms_Group05_Reserved5";
BA_ "SysSignalName" SG_ 351 ICBAD_20ms_Group05_Reserved5 "ICBAD_20ms_Group05_Reserved5";
BA_ "CompuMethodName" SG_ 351 APATotWhlToqReqVal "APATotWhlToqReqVal";
BA_ "ISignalName" SG_ 351 APATotWhlToqReqVal "IAPATotWhlToqReqVal";
BA_ "LongName" SG_ 351 APATotWhlToqReqVal "Advanced_Park_Assist_Total_Wheel_Torque_Request_Value";
BA_ "SysSignalName" SG_ 351 APATotWhlToqReqVal "APATotWhlToqReqVal";
BA_ "CompuMethodName" SG_ 351 ICBAD_20ms_Group05_Reserved6 "ICBAD_20ms_Group05_Reserved6";
BA_ "GenSigStartValue" SG_ 351 ICBAD_20ms_Group05_Reserved6 255;
BA_ "ISignalName" SG_ 351 ICBAD_20ms_Group05_Reserved6 "IICBAD_20ms_Group05_Reserved6";
BA_ "SysSignalName" SG_ 351 ICBAD_20ms_Group05_Reserved6 "ICBAD_20ms_Group05_Reserved6";
BA_ "CompuMethodName" SG_ 351 ICBAD_20ms_Group05_Reserved7 "ICBAD_20ms_Group05_Reserved7";
BA_ "GenSigStartValue" SG_ 351 ICBAD_20ms_Group05_Reserved7 255;
BA_ "ISignalName" SG_ 351 ICBAD_20ms_Group05_Reserved7 "IICBAD_20ms_Group05_Reserved7";
BA_ "SysSignalName" SG_ 351 ICBAD_20ms_Group05_Reserved7 "ICBAD_20ms_Group05_Reserved7";
BA_ "CompuMethodName" SG_ 351 ICBAD_20ms_Group05_Reserved8 "ICBAD_20ms_Group05_Reserved8";
BA_ "GenSigStartValue" SG_ 351 ICBAD_20ms_Group05_Reserved8 255;
BA_ "ISignalName" SG_ 351 ICBAD_20ms_Group05_Reserved8 "IICBAD_20ms_Group05_Reserved8";
BA_ "SysSignalName" SG_ 351 ICBAD_20ms_Group05_Reserved8 "ICBAD_20ms_Group05_Reserved8";
BA_ "CompuMethodName" SG_ 351 ICBAD_20ms_Group05_Reserved9 "ICBAD_20ms_Group05_Reserved9";
BA_ "GenSigStartValue" SG_ 351 ICBAD_20ms_Group05_Reserved9 255;
BA_ "ISignalName" SG_ 351 ICBAD_20ms_Group05_Reserved9 "IICBAD_20ms_Group05_Reserved9";
BA_ "SysSignalName" SG_ 351 ICBAD_20ms_Group05_Reserved9 "ICBAD_20ms_Group05_Reserved9";
BA_ "CompuMethodName" SG_ 351 ICBAD_20ms_Group05_Reserved10 "ICBAD_20ms_Group05_Reserved10";
BA_ "GenSigStartValue" SG_ 351 ICBAD_20ms_Group05_Reserved10 255;
BA_ "ISignalName" SG_ 351 ICBAD_20ms_Group05_Reserved10 "IICBAD_20ms_Group05_Reserved10";
BA_ "SysSignalName" SG_ 351 ICBAD_20ms_Group05_Reserved10 "ICBAD_20ms_Group05_Reserved10";
BA_ "CompuMethodName" SG_ 351 ICBAD_20ms_Group05_Reserved11 "ICBAD_20ms_Group05_Reserved11";
BA_ "GenSigStartValue" SG_ 351 ICBAD_20ms_Group05_Reserved11 255;
BA_ "ISignalName" SG_ 351 ICBAD_20ms_Group05_Reserved11 "IICBAD_20ms_Group05_Reserved11";
BA_ "SysSignalName" SG_ 351 ICBAD_20ms_Group05_Reserved11 "ICBAD_20ms_Group05_Reserved11";
BA_ "CompuMethodName" SG_ 351 ICBAD_20ms_Group05_Reserved12 "ICBAD_20ms_Group05_Reserved12";
BA_ "GenSigStartValue" SG_ 351 ICBAD_20ms_Group05_Reserved12 255;
BA_ "ISignalName" SG_ 351 ICBAD_20ms_Group05_Reserved12 "IICBAD_20ms_Group05_Reserved12";
BA_ "SysSignalName" SG_ 351 ICBAD_20ms_Group05_Reserved12 "ICBAD_20ms_Group05_Reserved12";
BA_ "CompuMethodName" SG_ 351 ICBAD_20ms_Group05_Reserved13 "ICBAD_20ms_Group05_Reserved13";
BA_ "GenSigStartValue" SG_ 351 ICBAD_20ms_Group05_Reserved13 255;
BA_ "ISignalName" SG_ 351 ICBAD_20ms_Group05_Reserved13 "IICBAD_20ms_Group05_Reserved13";
BA_ "SysSignalName" SG_ 351 ICBAD_20ms_Group05_Reserved13 "ICBAD_20ms_Group05_Reserved13";
BA_ "CompuMethodName" SG_ 351 ICBAD_20ms_Group05_Reserved14 "ICBAD_20ms_Group05_Reserved14";
BA_ "GenSigStartValue" SG_ 351 ICBAD_20ms_Group05_Reserved14 255;
BA_ "ISignalName" SG_ 351 ICBAD_20ms_Group05_Reserved14 "IICBAD_20ms_Group05_Reserved14";
BA_ "SysSignalName" SG_ 351 ICBAD_20ms_Group05_Reserved14 "ICBAD_20ms_Group05_Reserved14";
BA_ "CompuMethodName" SG_ 351 ICBAD_20ms_Group05_Reserved15 "ICBAD_20ms_Group05_Reserved15";
BA_ "GenSigStartValue" SG_ 351 ICBAD_20ms_Group05_Reserved15 255;
BA_ "ISignalName" SG_ 351 ICBAD_20ms_Group05_Reserved15 "IICBAD_20ms_Group05_Reserved15";
BA_ "SysSignalName" SG_ 351 ICBAD_20ms_Group05_Reserved15 "ICBAD_20ms_Group05_Reserved15";
BA_ "CompuMethodName" SG_ 424 ICBAD_20ms_Group12_CRC "ICBAD_20ms_Group12_CRC";
BA_ "ISignalName" SG_ 424 ICBAD_20ms_Group12_CRC "IICBAD_20ms_Group12_CRC";
BA_ "LongName" SG_ 424 ICBAD_20ms_Group12_CRC "ICBAD_20ms_Group12_CRC";
BA_ "SysSignalName" SG_ 424 ICBAD_20ms_Group12_CRC "ICBAD_20ms_Group12_CRC";
BA_ "CompuMethodName" SG_ 424 ICBAD_20ms_Group12_RC "ICBAD_20ms_Group12_RC";
BA_ "ISignalName" SG_ 424 ICBAD_20ms_Group12_RC "IICBAD_20ms_Group12_RC";
BA_ "LongName" SG_ 424 ICBAD_20ms_Group12_RC "ICBAD_20ms_Group12_RC";
BA_ "SysSignalName" SG_ 424 ICBAD_20ms_Group12_RC "ICBAD_20ms_Group12_RC";
BA_ "CompuMethodName" SG_ 424 AutodDrvngSysStsV "AutodDrvngSysStsV";
BA_ "ISignalName" SG_ 424 AutodDrvngSysStsV "IAutodDrvngSysStsV";
BA_ "LongName" SG_ 424 AutodDrvngSysStsV "Automated Driving System Status Validity";
BA_ "SysSignalName" SG_ 424 AutodDrvngSysStsV "AutodDrvngSysStsV";
BA_ "CompuMethodName" SG_ 424 ICBAD_20ms_Group12_Reserved1 "ICBAD_20ms_Group12_Reserved1";
BA_ "GenSigStartValue" SG_ 424 ICBAD_20ms_Group12_Reserved1 7;
BA_ "ISignalName" SG_ 424 ICBAD_20ms_Group12_Reserved1 "IICBAD_20ms_Group12_Reserved1";
BA_ "SysSignalName" SG_ 424 ICBAD_20ms_Group12_Reserved1 "ICBAD_20ms_Group12_Reserved1";
BA_ "CompuMethodName" SG_ 424 ICBAD_20ms_Group12_Reserved2 "ICBAD_20ms_Group12_Reserved2";
BA_ "GenSigStartValue" SG_ 424 ICBAD_20ms_Group12_Reserved2 31;
BA_ "ISignalName" SG_ 424 ICBAD_20ms_Group12_Reserved2 "IICBAD_20ms_Group12_Reserved2";
BA_ "SysSignalName" SG_ 424 ICBAD_20ms_Group12_Reserved2 "ICBAD_20ms_Group12_Reserved2";
BA_ "CompuMethodName" SG_ 424 APASts "APASts";
BA_ "ISignalName" SG_ 424 APASts "IAPASts";
BA_ "LongName" SG_ 424 APASts "Advanced_Park_Assist_Status";
BA_ "SysSignalName" SG_ 424 APASts "APASts";
BA_ "CompuMethodName" SG_ 424 AutodDrvngSysSts "AutodDrvngSysSts";
BA_ "ISignalName" SG_ 424 AutodDrvngSysSts "IAutodDrvngSysSts";
BA_ "LongName" SG_ 424 AutodDrvngSysSts "Automated_Driving_System_Status";
BA_ "SysSignalName" SG_ 424 AutodDrvngSysSts "AutodDrvngSysSts";
BA_ "CompuMethodName" SG_ 424 ICBAD_20ms_Group12_Reserved3 "ICBAD_20ms_Group12_Reserved3";
BA_ "GenSigStartValue" SG_ 424 ICBAD_20ms_Group12_Reserved3 255;
BA_ "ISignalName" SG_ 424 ICBAD_20ms_Group12_Reserved3 "IICBAD_20ms_Group12_Reserved3";
BA_ "SysSignalName" SG_ 424 ICBAD_20ms_Group12_Reserved3 "ICBAD_20ms_Group12_Reserved3";
BA_ "CompuMethodName" SG_ 424 ICBAD_20ms_Group12_Reserved4 "ICBAD_20ms_Group12_Reserved4";
BA_ "GenSigStartValue" SG_ 424 ICBAD_20ms_Group12_Reserved4 255;
BA_ "ISignalName" SG_ 424 ICBAD_20ms_Group12_Reserved4 "IICBAD_20ms_Group12_Reserved4";
BA_ "SysSignalName" SG_ 424 ICBAD_20ms_Group12_Reserved4 "ICBAD_20ms_Group12_Reserved4";
BA_ "CompuMethodName" SG_ 424 ICBAD_20ms_Group12_Reserved5 "ICBAD_20ms_Group12_Reserved5";
BA_ "GenSigStartValue" SG_ 424 ICBAD_20ms_Group12_Reserved5 255;
BA_ "ISignalName" SG_ 424 ICBAD_20ms_Group12_Reserved5 "IICBAD_20ms_Group12_Reserved5";
BA_ "SysSignalName" SG_ 424 ICBAD_20ms_Group12_Reserved5 "ICBAD_20ms_Group12_Reserved5";
BA_ "CompuMethodName" SG_ 424 ICBAD_20ms_Group12_Reserved6 "ICBAD_20ms_Group12_Reserved6";
BA_ "GenSigStartValue" SG_ 424 ICBAD_20ms_Group12_Reserved6 255;
BA_ "ISignalName" SG_ 424 ICBAD_20ms_Group12_Reserved6 "IICBAD_20ms_Group12_Reserved6";
BA_ "SysSignalName" SG_ 424 ICBAD_20ms_Group12_Reserved6 "ICBAD_20ms_Group12_Reserved6";
BA_ "CompuMethodName" SG_ 431 ICBAD_20ms_Group15_CRC "ICBAD_20ms_Group15_CRC";
BA_ "ISignalName" SG_ 431 ICBAD_20ms_Group15_CRC "IICBAD_20ms_Group15_CRC";
BA_ "LongName" SG_ 431 ICBAD_20ms_Group15_CRC "ICBAD_20ms_Group15_CRC";
BA_ "SysSignalName" SG_ 431 ICBAD_20ms_Group15_CRC "ICBAD_20ms_Group15_CRC";
BA_ "CompuMethodName" SG_ 431 ICBAD_20ms_Group15_RC "ICBAD_20ms_Group15_RC";
BA_ "ISignalName" SG_ 431 ICBAD_20ms_Group15_RC "IICBAD_20ms_Group15_RC";
BA_ "LongName" SG_ 431 ICBAD_20ms_Group15_RC "ICBAD_20ms_Group15_RC";
BA_ "SysSignalName" SG_ 431 ICBAD_20ms_Group15_RC "ICBAD_20ms_Group15_RC";
BA_ "CompuMethodName" SG_ 431 ACCDclReqSts "ACCDclReqSts";
BA_ "ISignalName" SG_ 431 ACCDclReqSts "IACCDclReqSts";
BA_ "LongName" SG_ 431 ACCDclReqSts "Adaptive Cruise Control Deceleration Request Status";
BA_ "SysSignalName" SG_ 431 ACCDclReqSts "ACCDclReqSts";
BA_ "CompuMethodName" SG_ 431 ICBAD_20ms_Group15_Reserved1 "ICBAD_20ms_Group15_Reserved1";
BA_ "GenSigStartValue" SG_ 431 ICBAD_20ms_Group15_Reserved1 3;
BA_ "ISignalName" SG_ 431 ICBAD_20ms_Group15_Reserved1 "IICBAD_20ms_Group15_Reserved1";
BA_ "SysSignalName" SG_ 431 ICBAD_20ms_Group15_Reserved1 "ICBAD_20ms_Group15_Reserved1";
BA_ "CompuMethodName" SG_ 431 ICBAD_20ms_Group15_Reserved2 "ICBAD_20ms_Group15_Reserved2";
BA_ "GenSigStartValue" SG_ 431 ICBAD_20ms_Group15_Reserved2 255;
BA_ "ISignalName" SG_ 431 ICBAD_20ms_Group15_Reserved2 "IICBAD_20ms_Group15_Reserved2";
BA_ "SysSignalName" SG_ 431 ICBAD_20ms_Group15_Reserved2 "ICBAD_20ms_Group15_Reserved2";
BA_ "CompuMethodName" SG_ 431 ACCOtptShaftTotToqReqVal "ACCOtptShaftTotToqReqVal";
BA_ "GenSigStartValue" SG_ 431 ACCOtptShaftTotToqReqVal 1696;
BA_ "ISignalName" SG_ 431 ACCOtptShaftTotToqReqVal "IACCOtptShaftTotToqReqVal";
BA_ "LongName" SG_ 431 ACCOtptShaftTotToqReqVal "Adaptive Cruise Control Output Shaft Total Torque Request Value";
BA_ "SysSignalName" SG_ 431 ACCOtptShaftTotToqReqVal "ACCOtptShaftTotToqReqVal";
BA_ "CompuMethodName" SG_ 431 ICBAD_20ms_Group15_Reserved3 "ICBAD_20ms_Group15_Reserved3";
BA_ "GenSigStartValue" SG_ 431 ICBAD_20ms_Group15_Reserved3 3;
BA_ "ISignalName" SG_ 431 ICBAD_20ms_Group15_Reserved3 "IICBAD_20ms_Group15_Reserved3";
BA_ "SysSignalName" SG_ 431 ICBAD_20ms_Group15_Reserved3 "ICBAD_20ms_Group15_Reserved3";
BA_ "CompuMethodName" SG_ 431 ACCOtptShaftTotToqReqSts "ACCOtptShaftTotToqReqSts";
BA_ "ISignalName" SG_ 431 ACCOtptShaftTotToqReqSts "IACCOtptShaftTotToqReqSts";
BA_ "LongName" SG_ 431 ACCOtptShaftTotToqReqSts "Adaptive Cruise Control Output Shaft Total Torque Request Status";
BA_ "SysSignalName" SG_ 431 ACCOtptShaftTotToqReqSts "ACCOtptShaftTotToqReqSts";
BA_ "CompuMethodName" SG_ 431 AutodDrvngSysStsPT "AutodDrvngSysStsPT";
BA_ "ISignalName" SG_ 431 AutodDrvngSysStsPT "IAutodDrvngSysStsPT";
BA_ "LongName" SG_ 431 AutodDrvngSysStsPT "Automated Driving System Status PT";
BA_ "SysSignalName" SG_ 431 AutodDrvngSysStsPT "AutodDrvngSysStsPT";
BA_ "CompuMethodName" SG_ 431 ICBAD_20ms_Group15_Reserved4 "ICBAD_20ms_Group15_Reserved4";
BA_ "GenSigStartValue" SG_ 431 ICBAD_20ms_Group15_Reserved4 255;
BA_ "ISignalName" SG_ 431 ICBAD_20ms_Group15_Reserved4 "IICBAD_20ms_Group15_Reserved4";
BA_ "SysSignalName" SG_ 431 ICBAD_20ms_Group15_Reserved4 "ICBAD_20ms_Group15_Reserved4";
BA_ "CompuMethodName" SG_ 431 ICBAD_20ms_Group15_Reserved5 "ICBAD_20ms_Group15_Reserved5";
BA_ "GenSigStartValue" SG_ 431 ICBAD_20ms_Group15_Reserved5 255;
BA_ "ISignalName" SG_ 431 ICBAD_20ms_Group15_Reserved5 "IICBAD_20ms_Group15_Reserved5";
BA_ "SysSignalName" SG_ 431 ICBAD_20ms_Group15_Reserved5 "ICBAD_20ms_Group15_Reserved5";
BA_ "CompuMethodName" SG_ 431 ICBAD_20ms_Group15_Reserved6 "ICBAD_20ms_Group15_Reserved6";
BA_ "GenSigStartValue" SG_ 431 ICBAD_20ms_Group15_Reserved6 255;
BA_ "ISignalName" SG_ 431 ICBAD_20ms_Group15_Reserved6 "IICBAD_20ms_Group15_Reserved6";
BA_ "SysSignalName" SG_ 431 ICBAD_20ms_Group15_Reserved6 "ICBAD_20ms_Group15_Reserved6";
BA_ "CompuMethodName" SG_ 431 ICBAD_20ms_Group15_Reserved7 "ICBAD_20ms_Group15_Reserved7";
BA_ "GenSigStartValue" SG_ 431 ICBAD_20ms_Group15_Reserved7 255;
BA_ "ISignalName" SG_ 431 ICBAD_20ms_Group15_Reserved7 "IICBAD_20ms_Group15_Reserved7";
BA_ "SysSignalName" SG_ 431 ICBAD_20ms_Group15_Reserved7 "ICBAD_20ms_Group15_Reserved7";
BA_ "CompuMethodName" SG_ 431 ICBAD_20ms_Group15_Reserved8 "ICBAD_20ms_Group15_Reserved8";
BA_ "GenSigStartValue" SG_ 431 ICBAD_20ms_Group15_Reserved8 255;
BA_ "ISignalName" SG_ 431 ICBAD_20ms_Group15_Reserved8 "IICBAD_20ms_Group15_Reserved8";
BA_ "SysSignalName" SG_ 431 ICBAD_20ms_Group15_Reserved8 "ICBAD_20ms_Group15_Reserved8";
BA_ "CompuMethodName" SG_ 431 ICBAD_20ms_Group15_Reserved9 "ICBAD_20ms_Group15_Reserved9";
BA_ "GenSigStartValue" SG_ 431 ICBAD_20ms_Group15_Reserved9 255;
BA_ "ISignalName" SG_ 431 ICBAD_20ms_Group15_Reserved9 "IICBAD_20ms_Group15_Reserved9";
BA_ "SysSignalName" SG_ 431 ICBAD_20ms_Group15_Reserved9 "ICBAD_20ms_Group15_Reserved9";

VAL_ 791 HVDCHVILStsV 0 "HVDCHVILStsV_0_Valid" 1 "HVDCHVILStsV_1_Invalid";
VAL_ 791 HVDCDCSta 0 "HVDCDCSta_0_Standby" 1 "HVDCDCSta_1_Reserved" 2 "HVDCDCSta_2_Buck" 3 "HVDCDCSta_3_DcLinkDischarge" 4 "HVDCDCSta_4_Boost" 5 "HVDCDCSta_5_Failure" 6 "HVDCDCSta_6_Reserved" 7 "HVDCDCSta_7_Reserved";
VAL_ 791 OnBdChrgrHVILStsVal 0 "OnBdChrgrHVILStsVal_0_Initial" 1 "OnBdChrgrHVILStsVal_1_Normal" 2 "OnBdChrgrHVILStsVal_2_Fault";
VAL_ 791 PDUHVILStsV 0 "PDUHVILStsV_0_Valid" 1 "PDUHVILStsV_1_Invalid";
VAL_ 791 PDUHVILSts 0 "PDUHVILSts_0_Initial" 1 "PDUHVILSts_1_Normal" 2 "PDUHVILSts_2_Fault";
VAL_ 791 OnBdChrgrHVILStsValV 0 "OnBdChrgrHVILStsValV_0_Valid" 1 "OnBdChrgrHVILStsValV_1_Invalid";
VAL_ 791 HVDCHVILSts 0 "HVDCHVILSts_0_Initial" 1 "HVDCHVILSts_1_Normal" 2 "HVDCHVILSts_2_Fault";
VAL_ 915 DCOverCurrentHV 0 "DCOverCurrentHV_0_False" 1 "DCOverCurrentHV_1_True";
VAL_ 915 DCOverCurrentLV 0 "DCOverCurrentLV_0_False" 1 "DCOverCurrentLV_1_True";
VAL_ 915 DCOverVoltHV 0 "DCOverVoltHV_0_False" 1 "DCOverVoltHV_1_True";
VAL_ 915 DCOverVoltLV 0 "DCOverVoltLV_0_False" 1 "DCOverVoltLV_1_True";
VAL_ 915 DCUnderVoltHV 0 "DCUnderVoltHV_0_False" 1 "DCUnderVoltHV_1_True";
VAL_ 915 DCUnderVoltLV 0 "DCUnderVoltLV_0_False" 1 "DCUnderVoltLV_1_True";
VAL_ 915 DCVoltFail 0 "DCVoltFail_0_No_Failure" 1 "DCVoltFail_1_Failure";
VAL_ 915 DschrgOptMaxPwrV 0 "DschrgOptMaxPwrV_0_Invalid" 1 "DschrgOptMaxPwrV_1_Valid";
VAL_ 915 CCUInnrDschrgplugin 0 "CCUInnrDschrgplugin_0_Disconnected" 1 "CCUInnrDschrgplugin_1_Connected";
VAL_ 915 CCUInnrDschrgSpRsn 0 "CCUInnrDschrgSpRsn_0_Default" 1 "CCUInnrDschrgSpRsn_1_Vehcile_Power_Limit" 2 "CCUInnrDschrgSpRsn_2_AC_Charging" 3 "CCUInnrDschrgSpRsn_3_Not_Plug_in_DisCharge" 4 "CCUInnrDschrgSpRsn_4_Other_reason" 5 "CCUInnrDschrgSpRsn_5_OBC_Fault" 6 "CCUInnrDschrgSpRsn_6_Reserved" 7 "CCUInnrDschrgSpRsn_7_DisCharging_System_Abnormal" 8 "CCUInnrDschrgSpRsn_8_Usage_mode_not_Satisfy" 9 "CCUInnrDschrgSpRsn_9_DisCharging_Socket_Over_Temperature" 10 "CCUInnrDschrgSpRsn_10_CCU_Inner_Over_Temperature" 11 "CCUInnrDschrgSpRsn_11_Coolant_Over_Temperature" 12 "CCUInnrDschrgSpRsn_12_Over_Load";
VAL_ 992 CCUOnbdChrgrPlugOnV 0 "CCUOnbdChrgrPlugOnV_0_Valid" 1 "CCUOnbdChrgrPlugOnV_1_Invalid";
VAL_ 992 OnBdChrgrCtrlPilotPWMSts 0 "OnBdChrgrCtrlPilotPWMSts_0_CP_9V" 1 "OnBdChrgrCtrlPilotPWMSts_1_CP_0V" 2 "OnBdChrgrCtrlPilotPWMSts_2_CP_9V_PWM" 3 "OnBdChrgrCtrlPilotPWMSts_3_CP_6V" 4 "OnBdChrgrCtrlPilotPWMSts_4_CP_6V_PWM" 5 "OnBdChrgrCtrlPilotPWMSts_5_CP_12V" 6 "OnBdChrgrCtrlPilotPWMSts_6_CP_12V_PWM" 7 "OnBdChrgrCtrlPilotPWMSts_7_CP_Out_Of_Range";
VAL_ 992 OnBdChrgrWkup 0 "OnBdChrgrWkup_0_False" 1 "OnBdChrgrWkup_1_True";
VAL_ 992 OnBdChrgrSts 0 "OnBdChrgrSts_0_idle" 1 "OnBdChrgrSts_1_Power_up" 3 "OnBdChrgrSts_3_Ready" 4 "OnBdChrgrSts_4_Pending" 5 "OnBdChrgrSts_5_Charging" 6 "OnBdChrgrSts_6_Discharging" 7 "OnBdChrgrSts_7_Warning" 9 "OnBdChrgrSts_9_Fault" 10 "OnBdChrgrSts_10_A_Stop" 12 "OnBdChrgrSts_12_C_Power_Off";
VAL_ 992 OnbdChrgrOtptCrntV 0 "OnbdChrgrOtptCrntV_0_Valid" 1 "OnbdChrgrOtptCrntV_1_Invalid";
VAL_ 992 OnbdChrgrOpngMd 0 "OnbdChrgrOpngMd_0_Default" 1 "OnbdChrgrOpngMd_1_Charging_Mode" 2 "OnbdChrgrOpngMd_2_V2L_Mode" 3 "OnbdChrgrOpngMd_3_V2V_Mode" 4 "OnbdChrgrOpngMd_4_V2G_Mode" 5 "OnbdChrgrOpngMd_5_Heating_Mode";
VAL_ 992 OnBdChrgrOtptVolV 0 "OnBdChrgrOtptVolV_0_Valid" 1 "OnBdChrgrOtptVolV_1_Invalid";
VAL_ 992 CCUActiveWkup 0 "CCUActiveWkup_0_False" 1 "CCUActiveWkup_1_True";
VAL_ 992 CCUOnbdChrgrPlugOn 0 "CCUOnbdChrgrPlugOn_0_Disconnected" 1 "CCUOnbdChrgrPlugOn_1_Connected_Gun_is_63A" 2 "CCUOnbdChrgrPlugOn_2_Connected_Gun_is_32A" 3 "CCUOnbdChrgrPlugOn_3_Connected_Gun_is_16A" 4 "CCUOnbdChrgrPlugOn_4_Connected_Gun_is_10A" 5 "CCUOnbdChrgrPlugOn_5_Semi_connected" 6 "CCUOnbdChrgrPlugOn_6_Abnormal_Connected" 7 "CCUOnbdChrgrPlugOn_7_V2L_Connected" 8 "CCUOnbdChrgrPlugOn_8_V2G_Connected" 9 "CCUOnbdChrgrPlugOn_9_Unknow_Connected";
VAL_ 992 CCUOnbdChrgrSpRsn 0 "CCUOnbdChrgrSpRsn_0_Default" 1 "CCUOnbdChrgrSpRsn_1_Grid_Fault" 3 "CCUOnbdChrgrSpRsn_3_Charging_Device_Fault" 5 "CCUOnbdChrgrSpRsn_5_OBC_Fault" 7 "CCUOnbdChrgrSpRsn_7_Charging_System_Abnormal" 9 "CCUOnbdChrgrSpRsn_9_Charging_Socket_Over_Temperature" 10 "CCUOnbdChrgrSpRsn_10_A_Ambient_Temperature_Abnormal" 11 "CCUOnbdChrgrSpRsn_11_B_Coolant_Pump_Abnormal" 12 "CCUOnbdChrgrSpRsn_12_V2L_Over_Load";
VAL_ 992 OnBdChrgrLastWkup 0 "OnBdChrgrLastWkup_0_False" 1 "OnBdChrgrLastWkup_1_True";
VAL_ 966 AirCtrlrHVILClsd 0 "AirCtrlrHVILClsd_0_Initial" 1 "AirCtrlrHVILClsd_1_Normal" 2 "AirCtrlrHVILClsd_2_Fault";
VAL_ 966 AirCtrlrHVILClsdV 0 "AirCtrlrHVILClsdV_0_Valid" 1 "AirCtrlrHVILClsdV_1_Invalid";
VAL_ 966 ESSPTCHVILSts 0 "ESSPTCHVILSts_0_Initial" 1 "ESSPTCHVILSts_1_Normal" 2 "ESSPTCHVILSts_2_Fault";
VAL_ 966 CCUOnbdChrgrSktEleccLckEnable 0 "CCUOnbdChrgrSktEleccLckEnable_0_Default" 1 "CCUOnbdChrgrSktEleccLckEnable_1_Locked" 2 "CCUOnbdChrgrSktEleccLckEnable_2_Unlocked";
VAL_ 966 HVDCDCIntnlFlr 0 "HVDCDCIntnlFlr_0_False" 1 "HVDCDCIntnlFlr_1_True";
VAL_ 966 HVDCDCHdwrFlr 0 "HVDCDCHdwrFlr_0_False" 1 "HVDCDCHdwrFlr_1_True";
VAL_ 966 ESSPTCHVILStsV 0 "ESSPTCHVILStsV_0_Valid" 1 "ESSPTCHVILStsV_1_Invalid";
VAL_ 1248 CCU_NM_BSMtoRMS_PTCANFD 0 "CCU_NM_BSMtoRMS_PTCANFD_0_CCU_NM_BSMtoRMS_0_False" 1 "CCU_NM_BSMtoRMS_PTCANFD_1_CCU_NM_BSMtoRMS_1_True";
VAL_ 1248 CCU_NM_PBSMtoRMS_PTCANFD 0 "CCU_NM_PBSMtoRMS_PTCANFD_0_CCU_NM_PBSMtoRMS_0_False" 1 "CCU_NM_PBSMtoRMS_PTCANFD_1_CCU_NM_PBSMtoRMS_1_True";
VAL_ 1248 CCU_NM_RMStoNOS_PTCANFD 0 "CCU_NM_RMStoNOS_PTCANFD_0_CCU_NM_RMStoNOS_0_False" 1 "CCU_NM_RMStoNOS_PTCANFD_1_CCU_NM_RMStoNOS_1_True";
VAL_ 1248 CCU_NM_RSStoNOS_PTCANFD 0 "CCU_NM_RSStoNOS_PTCANFD_0_CCU_NM_RSStoNOS_0_False" 1 "CCU_NM_RSStoNOS_PTCANFD_1_CCU_NM_RSStoNOS_1_True";
VAL_ 1248 CCU_NM_RSStoRMS_PTCANFD 0 "CCU_NM_RSStoRMS_PTCANFD_0_CCU_NM_RSStoRMS_0_False" 1 "CCU_NM_RSStoRMS_PTCANFD_1_CCU_NM_RSStoRMS_1_True";
VAL_ 1248 CCU_NM_NOStoRMS_PTCANFD 0 "CCU_NM_NOStoRMS_PTCANFD_0_CCU_NM_NOStoRMS_0_False" 1 "CCU_NM_NOStoRMS_PTCANFD_1_CCU_NM_NOStoRMS_1_True";
VAL_ 1248 CCU_NM_NOSSta_PTCANFD 0 "CCU_NM_NOSSta_PTCANFD_0_CCU_NM_NOSSta_0_False" 1 "CCU_NM_NOSSta_PTCANFD_1_CCU_NM_NOSSta_1_True";
VAL_ 1248 CCU_NM_RMSSta_PTCANFD 0 "CCU_NM_RMSSta_PTCANFD_0_CCU_NM_RMSSta_0_False" 1 "CCU_NM_RMSSta_PTCANFD_1_CCU_NM_RMSSta_1_True";
VAL_ 1248 CCU_NWI_PTCANFD 0 "CCU_NWI_PTCANFD_0_NoWakeNetworkSource" 1 "CCU_NWI_PTCANFD_1_PowerModeIsNonOFF" 2 "CCU_NWI_PTCANFD_2_OnboardChargerConnected";
VAL_ 1248 CCU_NOI_PTCANFD 0 "CCU_NOI_PTCANFD_0_NoRequest" 65535 "CCU_NOI_PTCANFD_65535_AllNetworkOperationActive";
VAL_ 1248 CCU_NKI_PTCANFD 0 "CCU_NKI_PTCANFD_0_NoRequest" 1 "CCU_NKI_PTCANFD_1_PowerModeIsNonOFF";
VAL_ 132 EnActuStdyStaToqV 0 "EnActuStdyStaToqV_0_Valid" 1 "EnActuStdyStaToqV_1_Invalid";
VAL_ 132 EnRunA 0 "EnRunA_0_False" 1 "EnRunA_1_True";
VAL_ 132 EnSpdSts 0 "EnSpdSts_0_Normal_Operation" 1 "EnSpdSts_1_Degraded_Operation" 2 "EnSpdSts_2_Reserved" 3 "EnSpdSts_3_Invalid";
VAL_ 132 ClOpenReqA 0 "ClOpenReqA_0_False" 1 "ClOpenReqA_1_True";
VAL_ 132 EnCtrlrRunCrkTrmlSts 0 "EnCtrlrRunCrkTrmlSts_0_Inactive" 1 "EnCtrlrRunCrkTrmlSts_1_Active";
VAL_ 132 IntlckRelayAuth 0 "IntlckRelayAuth_0__Interlock_relay_engagement_is_forbidden" 1 "IntlckRelayAuth_1__Interlock_relay_engagement_is_authorized";
VAL_ 132 RVSPtCrkAbotd 0 "RVSPtCrkAbotd_0_False" 1 "RVSPtCrkAbotd_1_True";
VAL_ 132 RVSPtRunAbotd 0 "RVSPtRunAbotd_0_False" 1 "RVSPtRunAbotd_1_True";
VAL_ 132 EnTestMdEnbReq 0 "EnTestMdEnbReq_0_False" 1 "EnTestMdEnbReq_1_True";
VAL_ 132 EnSpReqToTr 0 "EnSpReqToTr_0_False" 1 "EnSpReqToTr_1_True";
VAL_ 132 EnCCMd 0 "EnCCMd_0_Inactive" 1 "EnCCMd_1_Engaged" 2 "EnCCMd_2_Resume" 3 "EnCCMd_3_Accel" 4 "EnCCMd_4_Coast" 5 "EnCCMd_5_Tap" 6 "EnCCMd_6_Reserved" 7 "EnCCMd_7_Reserved";
VAL_ 1365 TrClThrmlProtnNotfn_ECM 0 "TrClThrmlProtnNotfn_ECM_0_No_Indication" 1 "TrClThrmlProtnNotfn_ECM_1_Indication_1" 2 "TrClThrmlProtnNotfn_ECM_2_Indication_2" 3 "TrClThrmlProtnNotfn_ECM_3_Indication_3" 4 "TrClThrmlProtnNotfn_ECM_4_Indication_4" 5 "TrClThrmlProtnNotfn_ECM_5_Indication_5" 6 "TrClThrmlProtnNotfn_ECM_6_Indication_6" 7 "TrClThrmlProtnNotfn_ECM_7_Indication_7" 8 "TrClThrmlProtnNotfn_ECM_8_Indication_8" 9 "TrClThrmlProtnNotfn_ECM_9_Indication_9" 10 "TrClThrmlProtnNotfn_ECM_10_Indication_10" 11 "TrClThrmlProtnNotfn_ECM_11_Indication_11" 12 "TrClThrmlProtnNotfn_ECM_12_Indication_12" 13 "TrClThrmlProtnNotfn_ECM_13_Indication_13" 14 "TrClThrmlProtnNotfn_ECM_14_Indication_14" 15 "TrClThrmlProtnNotfn_ECM_15_Indication_15";
VAL_ 1365 OtsdAirTemPtEstdV 0 "OtsdAirTemPtEstdV_0_Valid" 1 "OtsdAirTemPtEstdV_1_Invalid";
VAL_ 1365 OtsdAirTemPtEstdMsk 0 "OtsdAirTemPtEstdMsk_0_Don_t_Use_Data" 1 "OtsdAirTemPtEstdMsk_1_Use_Data";
VAL_ 1365 EnClntTemV 0 "EnClntTemV_0_Valid" 1 "EnClntTemV_1_Invalid";
VAL_ 1365 EnWarmUpCycAch 0 "EnWarmUpCycAch_0_False" 1 "EnWarmUpCycAch_1_True";
VAL_ 1365 EnIntkAirTemV 0 "EnIntkAirTemV_0_Valid" 1 "EnIntkAirTemV_1_Invalid";
VAL_ 1365 BarPrsAbsV 0 "BarPrsAbsV_0_Valid" 1 "BarPrsAbsV_1_Invalid";
VAL_ 531 ECODrvngSpdRutA 0 "ECODrvngSpdRutA_0_False" 1 "ECODrvngSpdRutA_1_True";
VAL_ 531 EcoDrvngAIO 0 "EcoDrvngAIO_0_False" 1 "EcoDrvngAIO_1_True";
VAL_ 531 EcoDrvngDspStsGearShftIndSts 0 "EcoDrvngDspStsGearShftIndSts_0_No_Shift" 1 "EcoDrvngDspStsGearShftIndSts_1_Gear_Shift_Up" 2 "EcoDrvngDspStsGearShftIndSts_2_Gear_Shift_Down" 3 "EcoDrvngDspStsGearShftIndSts_3_Reserved";
VAL_ 531 EnToqMinExtdRngV 0 "EnToqMinExtdRngV_0_Valid" 1 "EnToqMinExtdRngV_1_Invalid";
VAL_ 531 EnToqMaxExtdRngV 0 "EnToqMaxExtdRngV_0_Valid" 1 "EnToqMaxExtdRngV_1_Invalid";
VAL_ 531 EcoDrvngDspStsRcmndFwdGear 0 "EcoDrvngDspStsRcmndFwdGear_0_None" 1 "EcoDrvngDspStsRcmndFwdGear_1_First_Gear" 2 "EcoDrvngDspStsRcmndFwdGear_2_Second_Gear" 3 "EcoDrvngDspStsRcmndFwdGear_3_Third_Gear" 4 "EcoDrvngDspStsRcmndFwdGear_4_Fouth_Gear" 5 "EcoDrvngDspStsRcmndFwdGear_5_Fifth_Gear" 6 "EcoDrvngDspStsRcmndFwdGear_6_Sixth_Gear" 7 "EcoDrvngDspStsRcmndFwdGear_7_Seventh_Gear" 8 "EcoDrvngDspStsRcmndFwdGear_8_Eighth_Gear" 9 "EcoDrvngDspStsRcmndFwdGear_9_Unused_and_Reserved_1" 10 "EcoDrvngDspStsRcmndFwdGear_10_Unused_and_Reserved_2" 11 "EcoDrvngDspStsRcmndFwdGear_11_Unused_and_Reserved_3" 12 "EcoDrvngDspStsRcmndFwdGear_12_Unused_and_Reserved_4" 13 "EcoDrvngDspStsRcmndFwdGear_13_Unused_and_Reserved_5" 14 "EcoDrvngDspStsRcmndFwdGear_14_Unused_and_Reserved_6" 15 "EcoDrvngDspStsRcmndFwdGear_15_Unused_and_Reserved_7";
VAL_ 451 EnToqActuExtdRngV 0 "EnToqActuExtdRngV_0_Valid" 1 "EnToqActuExtdRngV_1_Invalid";
VAL_ 451 EnToqRducnFlrSts 0 "EnToqRducnFlrSts_0__Torque_Reduction_OK" 1 "EnToqRducnFlrSts_1__Torque_Reduction_Temporarily_Failed" 2 "EnToqRducnFlrSts_2__Torque_Reduction_Permanently_Failed" 3 "EnToqRducnFlrSts_3__Torque_Reduction_Limited" 4 "EnToqRducnFlrSts_4__Torque_Reduction_Communication_Failed" 5 "EnToqRducnFlrSts_5_Reserved" 6 "EnToqRducnFlrSts_6_Reserved" 7 "EnToqRducnFlrSts_7_Reserved";
VAL_ 451 PropSysA 0 "PropSysA_0_False" 1 "PropSysA_1_True";
VAL_ 451 EnAutoSpNotProb 0 "EnAutoSpNotProb_0_False" 1 "EnAutoSpNotProb_1_True";
VAL_ 451 EnASSStallDet 0 "EnASSStallDet_0_False" 1 "EnASSStallDet_1_True";
VAL_ 451 EnASSSta 0 "EnASSSta_0_Engine_Off" 1 "EnASSSta_1_Engine_Running" 2 "EnASSSta_2_Engine_Starting" 3 "EnASSSta_3_Engine_Stopping";
VAL_ 451 EnASSFuelReqdOn 0 "EnASSFuelReqdOn_0_False" 1 "EnASSFuelReqdOn_1_True";
VAL_ 451 EnASSFrngDet 0 "EnASSFrngDet_0_False" 1 "EnASSFrngDet_1_True";
VAL_ 451 EnToqDrvrReqdExtdRngV 0 "EnToqDrvrReqdExtdRngV_0_Valid" 1 "EnToqDrvrReqdExtdRngV_1_Invalid";
VAL_ 1249 ESS_NM_BSMtoRMS_PTCANFD 0 "ESS_NM_BSMtoRMS_PTCANFD_0_False" 1 "ESS_NM_BSMtoRMS_PTCANFD_1_True";
VAL_ 1249 ESS_NM_PBSMtoRMS_PTCANFD 0 "ESS_NM_PBSMtoRMS_PTCANFD_0_False" 1 "ESS_NM_PBSMtoRMS_PTCANFD_1_True";
VAL_ 1249 ESS_NM_RMStoNOS_PTCANFD 0 "ESS_NM_RMStoNOS_PTCANFD_0_False" 1 "ESS_NM_RMStoNOS_PTCANFD_1_True";
VAL_ 1249 ESS_NM_RSStoNOS_PTCANFD 0 "ESS_NM_RSStoNOS_PTCANFD_0_False" 1 "ESS_NM_RSStoNOS_PTCANFD_1_True";
VAL_ 1249 ESS_NM_RSStoRMS_PTCANFD 0 "ESS_NM_RSStoRMS_PTCANFD_0_False" 1 "ESS_NM_RSStoRMS_PTCANFD_1_True";
VAL_ 1249 ESS_NM_NOStoRMS_PTCANFD 0 "ESS_NM_NOStoRMS_PTCANFD_0_False" 1 "ESS_NM_NOStoRMS_PTCANFD_1_True";
VAL_ 1249 ESS_NM_NOSSta_PTCANFD 0 "ESS_NM_NOSSta_PTCANFD_0_False" 1 "ESS_NM_NOSSta_PTCANFD_1_True";
VAL_ 1249 ESS_NM_RMSSta_PTCANFD 0 "ESS_NM_RMSSta_PTCANFD_0_False" 1 "ESS_NM_RMSSta_PTCANFD_1_True";
VAL_ 1249 ESS_NWI_PTCANFD 0 "ESS_NWI_PTCANFD_0_NoWakeNetworkSource" 1 "ESS_NWI_PTCANFD_1_KL15orOBCWk" 4 "ESS_NWI_PTCANFD_4_ThermalFaultActive" 5 "ESS_NWI_PTCANFD_5_OffboardChargerConnected" 6 "ESS_NWI_PTCANFD_6_PoweroffMonitoringCountdownEnd" 7 "ESS_NWI_PTCANFD_7_Level3AlarmTriggeredDuringPoweroffMonitoring";
VAL_ 1249 ESS_NOI_PTCANFD 0 "ESS_NOI_PTCANFD_0_NoRequest" 65535 "ESS_NOI_PTCANFD_65535_AllNetworkOperationActive";
VAL_ 1249 ESS_NKI_PTCANFD 0 "ESS_NKI_PTCANFD_0_NoRequest" 1 "ESS_NKI_PTCANFD_1_PowerModeIsNonOFF" 2 "ESS_NKI_PTCANFD_2_OnboardChargingOrWilessCharging" 4 "ESS_NKI_PTCANFD_4_OffboardCharging" 8 "ESS_NKI_PTCANFD_8_ThermalFaultActive" 16 "ESS_NKI_PTCANFD_16_ReservedCharging" 32 "ESS_NKI_PTCANFD_32_V2L" 64 "ESS_NKI_PTCANFD_64_Charging_Cooling" 256 "ESS_NKI_PTCANFD_256_PreCharging" 512 "ESS_NKI_PTCANFD_512_PoweroffMonitoringCountdownEnd" 1024 "ESS_NKI_PTCANFD_1024_Level3AlarmTriggeredDuringPoweroffMonitoring" 2048 "BMS_NKI_PTCANFD_2048_OndbChargerFlapTimeWindow";
VAL_ 307 ACCDrvrSelTrgtSpd 0 "ACCDrvrSelTrgtSpd_0_no_speed_set";
VAL_ 307 ACCGoNotfr 0 "ACCGoNotfr_0_False" 1 "ACCGoNotfr_1_True";
VAL_ 307 ACCDetObjDistLvl 0 "ACCDetObjDistLvl_0_NoGapSet" 1 "ACCDetObjDistLvl_1_DistanceLevel1" 2 "ACCDetObjDistLvl_2_DistanceLevel2" 3 "ACCDetObjDistLvl_3_DistanceLevel3" 4 "ACCDetObjDistLvl_4_DistanceLevel4" 5 "ACCDetObjDistLvl_5_DistanceLevel5" 6 "ACCDetObjDistLvl_6_reserved" 7 "ACCDetObjDistLvl_7_reserved";
VAL_ 307 ELKSysSts_IPD 0 "ELKSysSts_IPD_0_off" 1 "ELKSysSts_IPD_1_Passive" 2 "ELKSysSts_IPD_2_Stand_by" 3 "ELKSysSts_IPD_3_Active_Roadedge" 4 "ELKSysSts_IPD_4_Active_Oncoming" 5 "ELKSysSts_IPD_5_Active_Overtaking" 6 "ELKSysSts_IPD_6_Overrride" 7 "ELKSysSts_IPD_7_Error" 8 "ELKSysSts_IPD_8_Reserve";
VAL_ 307 ACCTotWhlToqReqSts 0 "ACCTotWhlToqReqSts_0_NoRequest" 1 "ACCTotWhlToqReqSts_1_TorqueRequest" 2 "ACCTotWhlToqReqSts_2_Reserved";
VAL_ 307 ACCTJAMdSwDspCmd 0 "ACCTJAMdSwDspCmd_0_unavailable" 1 "ACCTJAMdSwDspCmd_1_ACC" 2 "ACCTJAMdSwDspCmd_2_TJA" 3 "ACCTJAMdSwDspCmd_3_SHWA" 4 "ACCTJAMdSwDspCmd_4_Off" 5 "ACCTJAMdSwDspCmd_5_Reserved" 6 "ACCTJAMdSwDspCmd_6_Reserved" 7 "ACCTJAMdSwDspCmd_7_Reserved";
VAL_ 307 ACCSeldTrgtDistLvl 0 "ACCSeldTrgtDistLvl_0_NoGapSet" 1 "ACCSeldTrgtDistLvl_1_DistanceLevel1" 2 "ACCSeldTrgtDistLvl_2_DistanceLevel2" 3 "ACCSeldTrgtDistLvl_3_DistanceLevel3" 4 "ACCSeldTrgtDistLvl_4_DistanceLevel4" 5 "ACCSeldTrgtDistLvl_5_DistanceLevel5";
VAL_ 307 HandOffStrgWhlDetnSta 0 "HandOffStrgWhlDetnSta_0_Hands_On" 1 "HandOffStrgWhlDetnSta_1_Hands_Off_level_1" 2 "HandOffStrgWhlDetnSta_2_Hands_Off_level_2" 3 "HandOffStrgWhlDetnSta_3_Hands_Off_level_3";
VAL_ 307 ILCActvnDircnDspCmd 0 "ILCActvnDircnDspCmd_0_Unavailable" 1 "ILCActvnDircnDspCmd_1_IlcNotActive" 2 "ILCActvnDircnDspCmd_2_IlcActiveLeft" 3 "ILCActvnDircnDspCmd_3_IlcActiveRight";
VAL_ 307 ILCSwDspCmd 0 "ILCSwDspCmd_0_unavailable" 1 "ILCSwDspCmd_1_off" 2 "ILCSwDspCmd_2_on" 3 "ILCSwDspCmd_3_reserved";
VAL_ 307 ILCSysSts 0 "ILCSysSts_0_Off" 1 "ILCSysSts_1_Failure" 2 "ILCSysSts_2_Standby" 3 "ILCSysSts_3_Passive" 4 "ILCSysSts_4_ActiveRequest" 5 "ILCSysSts_5_ActiveControl" 6 "ILCSysSts_6_Reserved" 7 "ILCSysSts_7_Reserved";
VAL_ 307 ILCActvnVelDspCmd 0 "ILCActvnVelDspCmd_0_Unavailable" 1 "ILCActvnVelDspCmd_1_IlcNotActive" 2 "ILCActvnVelDspCmd_2_IlcAcceleration" 3 "ILCActvnVelDspCmd_3_IlcDeceleration";
VAL_ 307 HandOffStrgWhlDetnStaV 0 "HandOffStrgWhlDetnStaV_0_Valid" 1 "HandOffStrgWhlDetnStaV_1_Invalid";
VAL_ 307 LDWLKAAudReq 0 "LDWLKAAudReq_0_no_request" 1 "LDWLKAAudReq_1_level_1" 2 "LDWLKAAudReq_2_level_2" 3 "LDWLKAAudReq_3_level_3";
VAL_ 307 LDWAdoWrnngDspCmd 0 "LDWAdoWrnngDspCmd_0_Unavailable" 1 "LDWAdoWrnngDspCmd_1_off" 2 "LDWAdoWrnngDspCmd_2_on" 3 "LDWAdoWrnngDspCmd_3_reserved";
VAL_ 307 LDWLKADspCmd 0 "LDWLKADspCmd_0_Unavailable" 1 "LDWLKADspCmd_1_off" 2 "LDWLKADspCmd_2_LDW" 3 "LDWLKADspCmd_3_LDP0" 4 "LDWLKADspCmd_4_LKA" 5 "LDWLKADspCmd_5_LDW_ELK" 6 "LDWLKADspCmd_6_LDP_ELK";
VAL_ 307 LKADrvrTkovReq 0 "LKADrvrTkovReq_0_False" 1 "LKADrvrTkovReq_1_True";
VAL_ 307 LDWSnstvtLvl 0 "LDWSnstvtLvl_0_unavailable" 1 "LDWSnstvtLvl_1_Low" 2 "LDWSnstvtLvl_2_Standard" 3 "LDWSnstvtLvl_3_High";
VAL_ 307 LDWLKAHptWrnngDspCmd 0 "LDWLKAHptWrnngDspCmd_0_unavailable" 1 "LDWLKAHptWrnngDspCmd_1_off" 2 "LDWLKAHptWrnngDspCmd_2_on";
VAL_ 307 EyeOffRoadDetnSta 0 "EyeOffRoadDetnSta_0_Eye_On" 1 "EyeOffRoadDetnSta_1_Eye_Off_level_1" 2 "EyeOffRoadDetnSta_2_Eye_Off_level_2" 3 "EyeOffRoadDetnSta_3_Eye_Off_level_3";
VAL_ 307 EyeOffRoadDetnStaV 0 "EyeOffRoadDetnStaV_0_Valid" 1 "EyeOffRoadDetnStaV_1_Invalid";
VAL_ 307 ACCMsgReq 0 "ACCMsgReq_0_NoDisplay" 1 "ACCMsgReq_1_Speed_is_lower_than_boundary" 2 "ACCMsgReq_2_active_failed_because_of_Handoff_Prohibition" 3 "ACCMsgReq_3_go_notifier_between_10s_and_50s" 4 "ACCMsgReq_4_go_notifier_between_50s_and_300s" 5 "ACCMsgReq_5_system_fault" 6 "ACCMsgReq_6_Reserved" 7 "ACCMsgReq_7_TCS_or_VSE_off" 8 "ACCMsgReq_8_Brake_pedal_is_not_pressed_when_vehicle_is_standstill" 9 "ACCMsgReq_9_Brake_pedal_is_not_released_during_driving" 10 "ACCMsgReq_10_Speed_is_out_of_boundary" 11 "ACCMsgReq_11_EPB_applied" 12 "ACCMsgReq_12_shift_is_not_in_D" 13 "ACCMsgReq_13_door_or_bonnet_is_open" 14 "ACCMsgReq_14_Driver_Seatbelt_released" 15 "ACCMsgReq_15_Driver_mode_not_support" 16 "ACCMsgReq_16_Reserve" 17 "ACCMsgReq_17_Reserve" 18 "ACCMsgReq_18_Reserve" 19 "ACCMsgReq_19_Reserve" 20 "ACCMsgReq_20_Reserve" 21 "ACCMsgReq_21_Reserve" 22 "ACCMsgReq_22_Reserve" 23 "ACCMsgReq_23_Reserve" 24 "ACCMsgReq_24_Reserve" 25 "ACCMsgReq_25_Reserve" 26 "ACCMsgReq_26_Reserve" 27 "ACCMsgReq_27_Reserve" 28 "ACCMsgReq_28_Reserve" 29 "ACCMsgReq_29_Reserve" 30 "ACCMsgReq_30_Reserve" 31 "ACCMsgReq_31_Reserve";
VAL_ 382 ACCSdslReq 0 "ACCSdslReq_0_No_Request" 1 "ACCSdslReq_1_Request";
VAL_ 382 ACCGoReq 0 "ACCGoReq_0_NoRequest" 1 "ACCGoReq_1_Request";
VAL_ 382 ACCAccReqSts_CH 0 "ACCAccReqSts_CH_0_No_Request" 1 "ACCAccReqSts_CH_1_ACC_Acceleration_Request";
VAL_ 382 APAEPBOPReq 0 "APAEPBOPReq_0_No_Request" 1 "APAEPBOPReq_1_Apply" 2 "APAEPBOPReq_2_Release";
VAL_ 382 ACCSysFltSts 0 "ACCSysFltSts_0_NoError" 1 "ACCSysFltSts_1_PerformanceDegradation" 2 "ACCSysFltSts_2_SystemTemporaryUnvailable" 3 "ACCSysFltSts_3_ServiceRequired" 4 "ACCSysFltSts_4_Reserved" 5 "ACCSysFltSts_5_Reserved" 6 "ACCSysFltSts_6_Reserved" 7 "ACCSysFltSts_7_Reserved";
VAL_ 382 ACCSysSts 0 "ACCSysSts_0_Off" 1 "ACCSysSts_1_StandBy" 2 "ACCSysSts_2_Active" 3 "ACCSysSts_3_Override" 4 "ACCSysSts_4_BrakeOnly" 5 "ACCSysSts_5_StandstillActive" 6 "ACCSysSts_6_StandstillWait" 7 "ACCSysSts_7_Passive";
VAL_ 382 APASCSAcclReqSts 0 "APASCSAcclReqSts_0_NoRequest" 1 "APASCSAcclReqSts_1_DecelerationRequest";
VAL_ 382 APAEPBOPReqV 0 "APAEPBOPReqV_0_Valid" 1 "APAEPBOPReqV_1_Invalid";
VAL_ 382 AutodDrvngSysSCSSdslReqV 0 "AutodDrvngSysSCSSdslReqV_0_Valid" 1 "AutodDrvngSysSCSSdslReqV_1_Invalid";
VAL_ 382 AutodDrvngSysSCSSdslReq 0 "AutodDrvngSysSCSSdslReq_0_NoRequest" 1 "AutodDrvngSysSCSSdslReq_1_request";
VAL_ 382 AutodDrvngSysEmgcBrkReqV 0 "AutodDrvngSysEmgcBrkReqV_0_Valid" 1 "AutodDrvngSysEmgcBrkReqV_1_Invalid";
VAL_ 382 AutodDrvngSysEmgcBrkReq 0 "AutodDrvngSysEmgcBrkReq_0_NoRequest" 1 "AutodDrvngSysEmgcBrkReq_1_EmergencyBrakeRequest";
VAL_ 382 AutodDrvngSysSCSDrvOffReqV 0 "AutodDrvngSysSCSDrvOffReqV_0_Valid" 1 "AutodDrvngSysSCSDrvOffReqV_1_Invalid";
VAL_ 382 AutodDrvngSysSCSDrvOffReq 0 "AutodDrvngSysSCSDrvOffReq_0_NoRequest" 1 "AutodDrvngSysSCSDrvOffReq_1_DriveOffRequest";
VAL_ 382 AutodDrvngSysMdReqV 0 "AutodDrvngSysMdReqV_0_Valid" 1 "AutodDrvngSysMdReqV_1_Invalid";
VAL_ 382 AutodDrvngSysMdReq 0 "AutodDrvngSysMdReq_0_DriverModeRequest" 1 "AutodDrvngSysMdReq_1_AutomatedDriverModeRequest";
VAL_ 382 AutodDrvngSysFlrStsV 0 "AutodDrvngSysFlrStsV_0_Valid" 1 "AutodDrvngSysFlrStsV_1_Invalid";
VAL_ 382 AutodDrvngSysFlrSts 0 "AutodDrvngSysFlrSts_0_NoError" 1 "AutodDrvngSysFlrSts_1_PerformanceDegradation" 2 "AutodDrvngSysFlrSts_2_SystemUnavailable" 3 "AutodDrvngSysFlrSts_3_Reserved" 4 "AutodDrvngSysFlrSts_4_Reserved" 5 "AutodDrvngSysFlrSts_5_Reserved" 6 "AutodDrvngSysFlrSts_6_Reserved" 7 "AutodDrvngSysFlrSts_7_Reserved";
VAL_ 343 AEBPrflReq 0 "AEBPrflReq_0_False" 1 "AEBPrflReq_1_True";
VAL_ 343 AEBSysSts 0 "AEBSysSts_0_Off" 1 "AEBSysSts_1_Standby" 2 "AEBSysSts_2_Disable" 3 "AEBSysSts_3_Override" 4 "AEBSysSts_4_Active" 5 "AEBSysSts_5_Reserved" 6 "AEBSysSts_6_Reserved" 7 "AEBSysSts_7_Reserved";
VAL_ 343 AEBDclReqSts 0 "AEBDclReqSts_0_NoRequest" 1 "AEBDclReqSts_1_AebDecelerationRequest" 2 "AEBDclReqSts_2_PebDecelerationRequest";
VAL_ 343 AEBBrkJerkLvlReq 0 "AEBBrkJerkLvlReq_0_NoRequest" 1 "AEBBrkJerkLvlReq_1_Level1_low" 2 "AEBBrkJerkLvlReq_2_Level2_middle" 3 "AEBBrkJerkLvlReq_3_Level3_high";
VAL_ 343 AEBHydBrkAstLvlReq 0 "AEBHydBrkAstLvlReq_0_NoRequest" 1 "AEBHydBrkAstLvlReq_1_Level1_low" 2 "AEBHydBrkAstLvlReq_2_Level2_middle" 3 "AEBHydBrkAstLvlReq_3_Level3_high" 4 "AEBHydBrkAstLvlReq_4_Reserved" 5 "AEBHydBrkAstLvlReq_5_Reserved" 6 "AEBHydBrkAstLvlReq_6_Reserved" 7 "AEBHydBrkAstLvlReq_7_Reserved";
VAL_ 343 AEBSysFltSts 0 "AEBSysFltSts_0_NoError" 1 "AEBSysFltSts_1_PerformanceDegradation" 2 "AEBSysFltSts_2_SystemTemporaryUnvailable" 3 "AEBSysFltSts_3_ServiceRequired" 4 "AEBSysFltSts_4_Reserved" 5 "AEBSysFltSts_5_Reserved" 6 "AEBSysFltSts_6_Reserved" 7 "AEBSysFltSts_7_Reserved";
VAL_ 360 APAShifterPosReqd 0 "APAShifterPosReqd_0_ScuInitialization" 1 "APAShifterPosReqd_1_S" 2 "APAShifterPosReqd_2_W" 3 "APAShifterPosReqd_3_M" 5 "APAShifterPosReqd_5_D" 6 "APAShifterPosReqd_6_N" 7 "APAShifterPosReqd_7_R" 8 "APAShifterPosReqd_8_P" 9 "APAShifterPosReqd_9_Reserved" 10 "APAShifterPosReqd_10_Error";
VAL_ 360 APASCUReqSts 0 "APASCUReqSts_0_No_Request" 1 "APASCUReqSts_1_Request" 2 "APASCUReqSts_2_Active" 3 "APASCUReqSts_3_Reversed";
VAL_ 360 APACmdEPSSts 0 "APACmdEPSSts_0_No_request" 1 "APACmdEPSSts_1_Control_EPS_request" 2 "APACmdEPSSts_2_EPS_control";
VAL_ 360 APAShifterPosReqdV 0 "APAShifterPosReqdV_0_Valid" 1 "APAShifterPosReqdV_1_Invalid";
VAL_ 360 APASCUReqStsV 0 "APASCUReqStsV_0_Valid" 1 "APASCUReqStsV_1_Invalid";
VAL_ 360 APAF 0 "APAF_0_Normal" 1 "APAF_1_APA_failure";
VAL_ 351 APAVCUReqSts 0 "APAVCUReqSts_0_NoRequest" 1 "APAVCUReqSts_1_RequestSpeedControl" 2 "APAVCUReqSts_2_RequestTorqueControl" 3 "APAVCUReqSts_3_Active";
VAL_ 351 APARevrDrgReq 0 "APARevrDrgReq_0_NoRequest" 1 "APARevrDrgReq_1_RequestReverseDrag";
VAL_ 424 AutodDrvngSysStsV 0 "AutodDrvngSysStsV_0_Valid" 1 "AutodDrvngSysStsV_1_Invalid";
VAL_ 424 APASts 0 "APASts_0_Disable" 1 "APASts_1_Standby" 2 "APASts_2_Semi_apaActive" 3 "APASts_3_Fully_apaActive" 4 "APASts_4_Failed";
VAL_ 424 AutodDrvngSysSts 0 "AutodDrvngSysSts_CH_0_Off" 1 "AutodDrvngSysSts_CH_1_APA_Disable" 2 "AutodDrvngSysSts_CH_2_APA_Standby" 3 "AutodDrvngSysSts_CH_3_Semi_APA_Active" 4 "AutodDrvngSysSts_CH_4_Fully_APA_Active" 5 "AutodDrvngSysSts_CH_5_APA_Failed" 6 "AutodDrvngSysSts_CH_6_Automated_driving_system_Disable" 7 "AutodDrvngSysSts_CH_7_Automated_driving_system_Standby" 8 "AutodDrvngSysSts_CH_8_Automated_driving_system_Failed" 9 "AutodDrvngSysSts_CH_9_Automated_driving_system_active";
VAL_ 431 ACCDclReqSts 0 "ACCDclReqSts_0_No_Request" 1 "ACCDclReqSts_1_ACC_Deceleration_Request";
VAL_ 431 ACCOtptShaftTotToqReqSts 0 "ACCOtptShaftTotToqReqSts_0_NoRequest" 1 "ACCOtptShaftTotToqReqSts_1_TorqueRequest";
VAL_ 431 AutodDrvngSysStsPT 0 "AutodDrvngSysStsPT_0_Off" 1 "AutodDrvngSysStsPT_1_APA_Disable" 2 "AutodDrvngSysStsPT_2_APA_Standby" 3 "AutodDrvngSysStsPT_3_Semi_APA_Active" 4 "AutodDrvngSysStsPT_4_Fully_APA_Active" 5 "AutodDrvngSysStsPT_5_APA_Failed" 6 "AutodDrvngSysStsPT_6_Automated_driving_system_Disable" 7 "AutodDrvngSysStsPT_7_Automated_driving_system_Standby" 8 "AutodDrvngSysStsPT_8_Automated_driving_system_Failed" 9 "AutodDrvngSysStsPT_9_Automated_driving_system_active";
SIG_GROUP_ 791 ICCU_100ms_Group02 1 : CCU_100ms_Group02_CRC CCU_100ms_Group02_RC CCU_100ms_Group02_Reserved1 CCU_100ms_Group02_Reserved2 CCU_100ms_Group02_Reserved3 CCU_100ms_Group02_Reserved4 HVDCDCSta HVDCDCTem HVDCHVILSts HVDCHVILStsV OnBdChrgrHVILStsVal OnBdChrgrHVILStsValV PDUHVILSts PDUHVILStsV;
SIG_GROUP_ 992 ICCU_100ms_Group07 1 : CCUActiveWkup CCUOnbdChrgrMaxChrgPwr CCUOnbdChrgrPlugOn CCUOnbdChrgrPlugOnV CCUOnbdChrgrSpRsn CCU_100ms_Group07_CRC CCU_100ms_Group07_RC CCU_100ms_Group07_Reserved1 CCU_100ms_Group07_Reserved10 CCU_100ms_Group07_Reserved11 CCU_100ms_Group07_Reserved2 CCU_100ms_Group07_Reserved3 CCU_100ms_Group07_Reserved4 CCU_100ms_Group07_Reserved5 CCU_100ms_Group07_Reserved6 CCU_100ms_Group07_Reserved7 CCU_100ms_Group07_Reserved8 CCU_100ms_Group07_Reserved9 OnBdChrgrAltrCrntInptCrnt OnBdChrgrAltrCrntInptVol OnBdChrgrCtrlPilotPWMDuty OnBdChrgrCtrlPilotPWMSts OnBdChrgrL1AltrCrntInptCrnt OnBdChrgrL1AltrCrntInptVol OnBdChrgrL2AltrCrntInptCrnt OnBdChrgrL2AltrCrntInptVol OnBdChrgrL3AltrCrntInptCrnt OnBdChrgrL3AltrCrntInptVol OnBdChrgrLastWkup OnBdChrgrOtptVolV OnBdChrgrSts OnBdChrgrWkup OnbdChrgrAltrCrntInptHVCrntLmt OnbdChrgrOpngMd OnbdChrgrOtptCrntV OnbdChrgrOtptCrntVal OnbdChrgrOtptVolVal;
SIG_GROUP_ 966 ICCU_100ms_Group11 1 : AirCtrlrHVILClsd AirCtrlrHVILClsdV CCUClntFlowReq CCUOnbdChrgrSktEleccLckEnable CCU_100ms_Group11_CRC CCU_100ms_Group11_RC CCU_100ms_Group11_Reserved1 CCU_100ms_Group11_Reserved10 CCU_100ms_Group11_Reserved11 CCU_100ms_Group11_Reserved12 CCU_100ms_Group11_Reserved13 CCU_100ms_Group11_Reserved14 CCU_100ms_Group11_Reserved2 CCU_100ms_Group11_Reserved3 CCU_100ms_Group11_Reserved4 CCU_100ms_Group11_Reserved5 CCU_100ms_Group11_Reserved6 CCU_100ms_Group11_Reserved7 CCU_100ms_Group11_Reserved8 CCU_100ms_Group11_Reserved9 ESSPTCHVILSts ESSPTCHVILStsV HVDCDCClntPumpPWMReq HVDCDCHdwrFlr HVDCDCIntnlFlr;
SIG_GROUP_ 132 IECM_010ms_Group00 1 : ClOpenReqA ECM_010ms_Group00_CRC ECM_010ms_Group00_RC ECM_010ms_Group00_Reserved39 ECM_010ms_Group00_Reserved63 EnActuStdyStaToq EnActuStdyStaToqV EnCCMd EnCtrlrRunCrkTrmlSts EnRunA EnSpReqToTr EnSpd EnSpdSts EnTestMdEnbReq IntlckRelayAuth RVSPtCrkAbotd RVSPtRunAbotd;
SIG_GROUP_ 1365 IECM_500ms_group02 1 : BarPrsAbs BarPrsAbsOBD BarPrsAbsV ECM_500ms_group02_CRC ECM_500ms_group02_RC ECM_500ms_group02_Reserved1 EnClntTem EnClntTemV EnIntkAirTem EnIntkAirTemV EnWarmUpCycAch OtsdAirTemPtEstd OtsdAirTemPtEstdMsk OtsdAirTemPtEstdV TrClThrmlProtnNotfn_ECM;
SIG_GROUP_ 531 IECM_ZONE_050ms_Group09 1 : ECM_ZONE_050ms_Group09_CRC ECM_ZONE_050ms_Group09_RC ECM_ZONE_050ms_Group09_Reserved1 ECM_ZONE_050ms_Group09_Reserved2 ECM_ZONE_050ms_Group09_Reserved3 ECODrvngSpdRutA EcoDrvngAIO EcoDrvngDspStsGearShftIndSts EcoDrvngDspStsRcmndFwdGear EnToqMaxExtdRng EnToqMaxExtdRngV EnToqMinExtdRng EnToqMinExtdRngV;
SIG_GROUP_ 451 IECM_ZONE_020ms_Group03 1 : ECM_020ms_PDU03_CRC ECM_020ms_PDU03_RC ECM_ZONE_020ms_Group03_Reserved1 ECM_ZONE_020ms_Group03_Reserved2 EnASSFrngDet EnASSFuelReqdOn EnASSSta EnASSStallDet EnAutoSpNotProb EnToqActuExtdRng EnToqActuExtdRngV EnToqDrvrReqdExtdRng EnToqDrvrReqdExtdRngV EnToqRducnFlrSts PropSysA;
SIG_GROUP_ 307 IFVCM_20ms_Group02 1 : ACCDetObjDistLvl ACCDrvrSelTrgtSpd ACCGoNotfr ACCMsgReq ACCSeldTrgtDistLvl ACCTJAMdSwDspCmd ACCTotWhlToqReqSts ACCTotWhlToqReqVal ELKSysSts_IPD EyeOffRoadDetnSta EyeOffRoadDetnStaV FVCM_20ms_Group02_CRC FVCM_20ms_Group02_RC FVCM_20ms_Group02_Reserved1 FVCM_20ms_Group02_Reserved2 FVCM_20ms_Group02_Reserved3 FVCM_20ms_Group02_Reserved4 FVCM_20ms_Group02_Reserved5 FVCM_20ms_Group02_Reserved6 FVCM_20ms_Group02_Reserved7 FVCM_20ms_Group02_Reserved8 HandOffStrgWhlDetnSta HandOffStrgWhlDetnStaV ILCActvnDircnDspCmd ILCActvnVelDspCmd ILCSwDspCmd ILCSysSts LDWAdoWrnngDspCmd LDWLKAAudReq LDWLKADspCmd LDWLKAHptWrnngDspCmd LDWSnstvtLvl LKADrvrTkovReq;
SIG_GROUP_ 382 IICBAD_20ms_Group07 1 : ACCAccReqSts_CH ACCAccReqVal ACCGoReq ACCSdslReq ACCSysFltSts ACCSysSts AIPkgAPASCSAcclReqVal APAEPBOPReq APAEPBOPReqV APASCSAcclReqSts AutodDrvngSysEmgcBrkReq AutodDrvngSysEmgcBrkReqV AutodDrvngSysFlrSts AutodDrvngSysFlrStsV AutodDrvngSysMdReq AutodDrvngSysMdReqV AutodDrvngSysSCSDrvOffReq AutodDrvngSysSCSDrvOffReqV AutodDrvngSysSCSSdslReq AutodDrvngSysSCSSdslReqV ICBAD_20ms_Group07_CRC ICBAD_20ms_Group07_RC ICBAD_20ms_Group07_Reserved1;
SIG_GROUP_ 343 IICBAD_20ms_Group46 1 : AEBBrkJerkLvlReq AEBDclReqSts AEBDclReqToqVal AEBDclReqVal AEBHydBrkAstLvlReq AEBPrflReq AEBSysFltSts AEBSysSts ICBAD_20ms_Group46_CRC ICBAD_20ms_Group46_RC ICBAD_20ms_Group46_Reserved1 ICBAD_20ms_Group46_Reserved2;
SIG_GROUP_ 360 IICBAD_20ms_Group13 1 : APACmdEPSSts APAF APASCUReqSts APASCUReqStsV APAShifterPosReqd APAShifterPosReqdV APATrgtEPSStrgWhlAng ICBAD_20ms_Group13_CRC ICBAD_20ms_Group13_RC ICBAD_20ms_Group13_Reserved1 ICBAD_20ms_Group13_Reserved2 ICBAD_20ms_Group13_Reserved3 ICBAD_20ms_Group13_Reserved4 ICBAD_20ms_Group13_Reserved5;
SIG_GROUP_ 351 IICBAD_20ms_Group05 1 : APACrpSpdReqVal_IPD APARevrDrgReq APAToqReqVal APATotWhlToqReqVal APAVCUReqSts ICBAD_20ms_Group05_CRC ICBAD_20ms_Group05_RC ICBAD_20ms_Group05_Reserved1 ICBAD_20ms_Group05_Reserved10 ICBAD_20ms_Group05_Reserved11 ICBAD_20ms_Group05_Reserved12 ICBAD_20ms_Group05_Reserved13 ICBAD_20ms_Group05_Reserved14 ICBAD_20ms_Group05_Reserved15 ICBAD_20ms_Group05_Reserved2 ICBAD_20ms_Group05_Reserved3 ICBAD_20ms_Group05_Reserved4 ICBAD_20ms_Group05_Reserved5 ICBAD_20ms_Group05_Reserved6 ICBAD_20ms_Group05_Reserved7 ICBAD_20ms_Group05_Reserved8 ICBAD_20ms_Group05_Reserved9;
SIG_GROUP_ 424 IICBAD_20ms_Group12 1 : APASts AutodDrvngSysSts AutodDrvngSysStsV ICBAD_20ms_Group12_CRC ICBAD_20ms_Group12_RC ICBAD_20ms_Group12_Reserved1 ICBAD_20ms_Group12_Reserved2 ICBAD_20ms_Group12_Reserved3 ICBAD_20ms_Group12_Reserved4 ICBAD_20ms_Group12_Reserved5 ICBAD_20ms_Group12_Reserved6;
SIG_GROUP_ 431 IICBAD_20ms_Group15 1 : ACCDclReqSts ACCOtptShaftTotToqReqSts ACCOtptShaftTotToqReqVal AutodDrvngSysStsPT ICBAD_20ms_Group15_CRC ICBAD_20ms_Group15_RC ICBAD_20ms_Group15_Reserved1 ICBAD_20ms_Group15_Reserved2 ICBAD_20ms_Group15_Reserved3 ICBAD_20ms_Group15_Reserved4 ICBAD_20ms_Group15_Reserved5 ICBAD_20ms_Group15_Reserved6 ICBAD_20ms_Group15_Reserved7 ICBAD_20ms_Group15_Reserved8 ICBAD_20ms_Group15_Reserved9;
